VERSION ""

NS_ :

BS_:

BU_: APIM_CISM FCIMB RACM_RCIM DSP WCM DACMC HUD_ADV TRM_ITRM ACM GWM _delete APIM IPC GENERIC TSTR

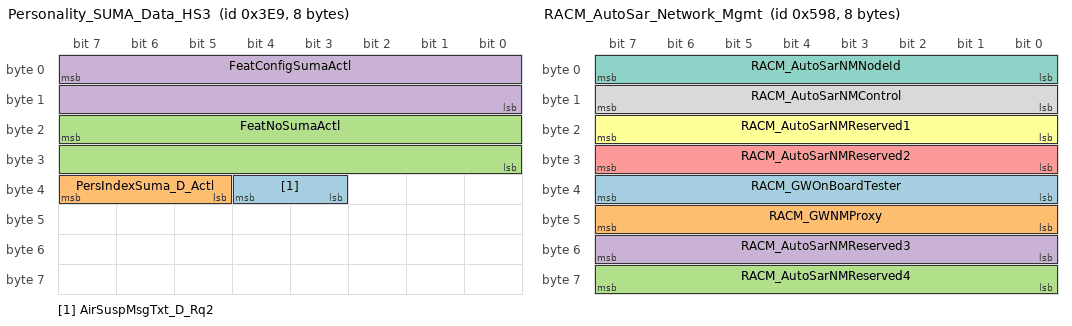
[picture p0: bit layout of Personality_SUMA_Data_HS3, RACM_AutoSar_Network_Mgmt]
BO_ 1001 Personality_SUMA_Data_HS3: 8 GWM
 SG_ AirSuspMsgTxt_D_Rq2 : 36|2@0+ (1,0) [0|3] "SED"  APIM_CISM,APIM,IPC
 SG_ PersIndexSuma_D_Actl : 39|3@0+ (1,0) [0|7] "SED"  APIM_CISM,APIM,IPC
 SG_ FeatNoSumaActl : 23|16@0+ (1,0) [0|65535] "Number"  APIM_CISM,APIM,IPC
 SG_ FeatConfigSumaActl : 7|16@0+ (1,0) [0|65535] "Undefined"  APIM_CISM,APIM,IPC

BO_ 1916 TesterPhysicalResRACM: 8 RACM_RCIM
 SG_ TesterPhysicalResRACM : 7|64@0+ (1,0) [0|1.84467E+019] "unitless"  TSTR

BO_ 1908 TesterPhysicalReqRACM: 8 TSTR
 SG_ TesterPhysicalReqRACM : 7|64@0+ (1,0) [0|1.84467E+019] "unitless"  RACM_RCIM

BO_ 1432 RACM_AutoSar_Network_Mgmt: 8 RACM_RCIM
 SG_ RACM_GWOnBoardTester : 39|8@0+ (1,0) [0|255] "unitless"  HUD_ADV,GWM
 SG_ RACM_GWNMProxy : 47|8@0+ (1,0) [0|255] "unitless"  HUD_ADV,GWM
 SG_ RACM_AutoSarNMReserved4 : 63|8@0+ (1,0) [0|255] "unitless"  HUD_ADV,GWM
 SG_ RACM_AutoSarNMReserved3 : 55|8@0+ (1,0) [0|255] "unitless"  HUD_ADV,GWM
 SG_ RACM_AutoSarNMReserved2 : 31|8@0+ (1,0) [0|255] "unitless"  HUD_ADV,GWM
 SG_ RACM_AutoSarNMReserved1 : 23|8@0+ (1,0) [0|255] "unitless"  HUD_ADV,GWM
 SG_ RACM_AutoSarNMNodeId : 7|8@0+ (1,0) [0|255] "unitless"  HUD_ADV,GWM
 SG_ RACM_AutoSarNMControl : 15|8@0+ (1,0) [0|255] "unitless"  HUD_ADV,GWM

BO_ 1923 TesterPhysicalReqDSP: 8 TSTR
 SG_ TesterPhysicalReqDSP : 7|64@0+ (1,0) [0|1.84467E+019] "unitless"  DSP

BO_ 1931 TesterPhysicalResDSP: 8 DSP
 SG_ TesterPhysicalResDSP : 7|64@0+ (1,0) [0|1.84467E+019] "unitless"  TSTR

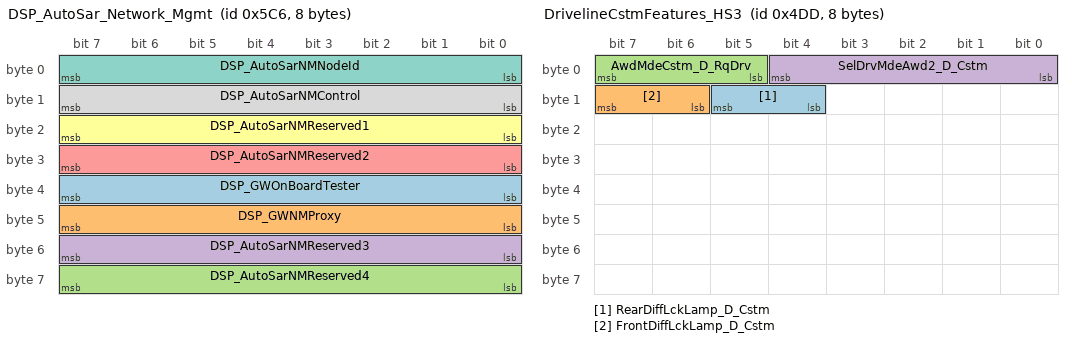
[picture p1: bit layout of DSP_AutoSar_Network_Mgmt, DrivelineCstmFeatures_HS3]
BO_ 1478 DSP_AutoSar_Network_Mgmt: 8 DSP
 SG_ DSP_GWOnBoardTester : 39|8@0+ (1,0) [0|255] "unitless"  HUD_ADV
 SG_ DSP_GWNMProxy : 47|8@0+ (1,0) [0|255] "unitless"  HUD_ADV
 SG_ DSP_AutoSarNMReserved4 : 63|8@0+ (1,0) [0|255] "unitless"  HUD_ADV
 SG_ DSP_AutoSarNMReserved3 : 55|8@0+ (1,0) [0|255] "unitless"  HUD_ADV
 SG_ DSP_AutoSarNMReserved2 : 31|8@0+ (1,0) [0|255] "unitless"  HUD_ADV
 SG_ DSP_AutoSarNMReserved1 : 23|8@0+ (1,0) [0|255] "unitless"  HUD_ADV
 SG_ DSP_AutoSarNMNodeId : 7|8@0+ (1,0) [0|255] "unitless"  HUD_ADV
 SG_ DSP_AutoSarNMControl : 15|8@0+ (1,0) [0|255] "unitless"  HUD_ADV

BO_ 1245 DrivelineCstmFeatures_HS3: 8 GWM
 SG_ RearDiffLckLamp_D_Cstm : 13|2@0+ (1,0) [0|3] "SED"  IPC
 SG_ FrontDiffLckLamp_D_Cstm : 15|2@0+ (1,0) [0|3] "SED"  IPC
 SG_ AwdMdeCstm_D_RqDrv : 7|3@0+ (1,0) [0|7] "SED"  IPC
 SG_ SelDrvMdeAwd2_D_Cstm : 4|5@0+ (1,0) [0|31] "SED"  GENERIC

BO_ 1242 PowertrainCstmData_HS3: 8 GWM
 SG_ EngExhMdeQuietCstm_D_Rq : 7|3@0+ (1,0) [0|7] "SED"  IPC
 SG_ StopStrtCstm_D_Rq : 15|2@0+ (1,0) [0|3] "SED"  IPC
 SG_ SelDrvMdeCstmPt_D_Rq : 4|5@0+ (1,0) [0|31] "SED"  GENERIC

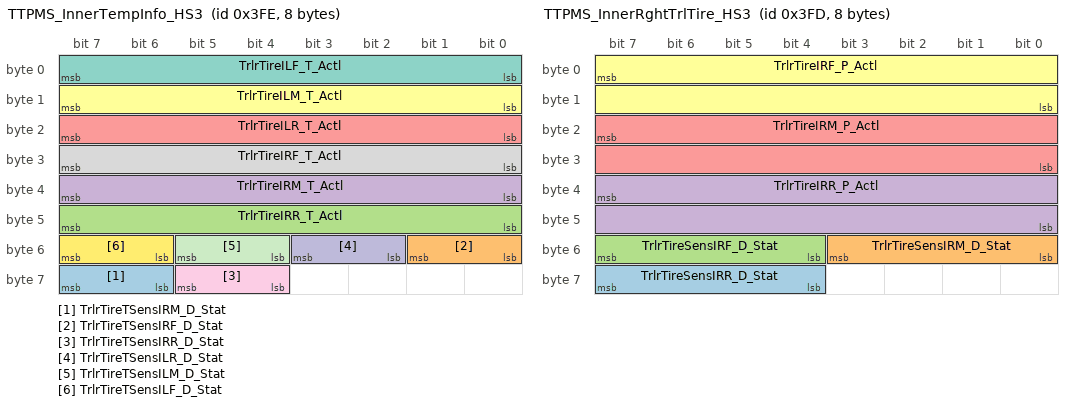
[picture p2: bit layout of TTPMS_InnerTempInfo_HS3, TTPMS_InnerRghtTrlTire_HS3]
BO_ 1022 TTPMS_InnerTempInfo_HS3: 8 GWM
 SG_ TrlrTireTSensIRM_D_Stat : 63|2@0+ (1,0) [0|3] "SED"  APIM_CISM,APIM,IPC
 SG_ TrlrTireTSensIRF_D_Stat : 49|2@0+ (1,0) [0|3] "SED"  APIM_CISM,APIM,IPC
 SG_ TrlrTireIRR_T_Actl : 47|8@0+ (1,-60) [-60|193] "degC"  APIM_CISM,APIM,IPC
 SG_ TrlrTireIRM_T_Actl : 39|8@0+ (1,-60) [-60|193] "degC"  APIM_CISM,APIM,IPC
 SG_ TrlrTireILR_T_Actl : 23|8@0+ (1,-60) [-60|193] "degC"  APIM_CISM,APIM,IPC
 SG_ TrlrTireILM_T_Actl : 15|8@0+ (1,-60) [-60|193] "degC"  APIM_CISM,APIM,IPC
 SG_ TrlrTireILF_T_Actl : 7|8@0+ (1,-60) [-60|193] "degC"  APIM_CISM,APIM,IPC
 SG_ TrlrTireIRF_T_Actl : 31|8@0+ (1,-60) [-60|193] "degC"  APIM_CISM,APIM,IPC
 SG_ TrlrTireTSensIRR_D_Stat : 61|2@0+ (1,0) [0|3] "SED"  APIM_CISM,APIM,IPC
 SG_ TrlrTireTSensILR_D_Stat : 51|2@0+ (1,0) [0|3] "SED"  APIM_CISM,APIM,IPC
 SG_ TrlrTireTSensILM_D_Stat : 53|2@0+ (1,0) [0|3] "SED"  APIM_CISM,APIM,IPC
 SG_ TrlrTireTSensILF_D_Stat : 55|2@0+ (1,0) [0|3] "SED"  APIM_CISM,APIM,IPC

BO_ 1021 TTPMS_InnerRghtTrlTire_HS3: 8 GWM
 SG_ TrlrTireSensIRR_D_Stat : 63|4@0+ (1,0) [0|15] "SED"  APIM_CISM,APIM,IPC
 SG_ TrlrTireSensIRM_D_Stat : 51|4@0+ (1,0) [0|15] "SED"  APIM_CISM,APIM,IPC
 SG_ TrlrTireSensIRF_D_Stat : 55|4@0+ (1,0) [0|15] "SED"  APIM_CISM,APIM,IPC
 SG_ TrlrTireIRR_P_Actl : 39|16@0+ (1,0) [0|65533] "kilopascal"  APIM_CISM,APIM,IPC
 SG_ TrlrTireIRM_P_Actl : 23|16@0+ (1,0) [0|65533] "kilopascal"  APIM_CISM,APIM,IPC
 SG_ TrlrTireIRF_P_Actl : 7|16@0+ (1,0) [0|65533] "kilopascal"  APIM_CISM,APIM,IPC

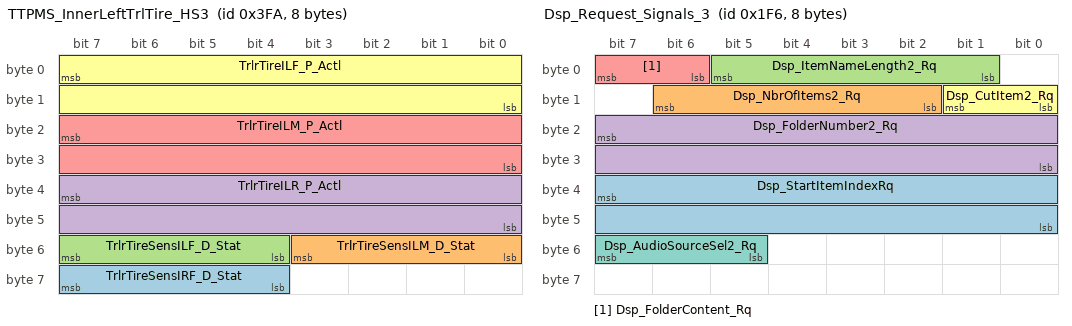
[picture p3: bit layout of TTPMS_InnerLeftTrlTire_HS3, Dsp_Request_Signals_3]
BO_ 1018 TTPMS_InnerLeftTrlTire_HS3: 8 GWM
 SG_ TrlrTireSensIRF_D_Stat : 63|4@0+ (1,0) [0|15] "SED"  APIM,IPC
 SG_ TrlrTireSensILM_D_Stat : 51|4@0+ (1,0) [0|15] "SED"  APIM_CISM,APIM,IPC
 SG_ TrlrTireSensILF_D_Stat : 55|4@0+ (1,0) [0|15] "SED"  APIM_CISM,APIM,IPC
 SG_ TrlrTireILR_P_Actl : 39|16@0+ (1,0) [0|65533] "kilopascal"  APIM_CISM,APIM,IPC
 SG_ TrlrTireILM_P_Actl : 23|16@0+ (1,0) [0|65533] "kilopascal"  APIM_CISM,APIM,IPC
 SG_ TrlrTireILF_P_Actl : 7|16@0+ (1,0) [0|65533] "kilopascal"  APIM_CISM,APIM,IPC

BO_ 502 Dsp_Request_Signals_3: 8 APIM
 SG_ Dsp_StartItemIndexRq : 39|16@0+ (1,0) [0|65535] "unitless"  APIM_CISM,ACM
 SG_ Dsp_NbrOfItems2_Rq : 14|5@0+ (1,0) [0|20] "SED"  APIM_CISM,ACM
 SG_ Dsp_ItemNameLength2_Rq : 5|5@0+ (1,0) [0|20] "SED"  APIM_CISM,ACM
 SG_ Dsp_FolderNumber2_Rq : 23|16@0+ (1,0) [0|65535] "unitless"  APIM_CISM,ACM
 SG_ Dsp_FolderContent_Rq : 7|2@0+ (1,0) [0|3] "SED"  APIM_CISM,ACM
 SG_ Dsp_CutItem2_Rq : 9|2@0+ (1,0) [0|3] "SED"  APIM_CISM,ACM
 SG_ Dsp_AudioSourceSel2_Rq : 55|3@0+ (1,0) [0|7] "SED"  APIM_CISM,ACM

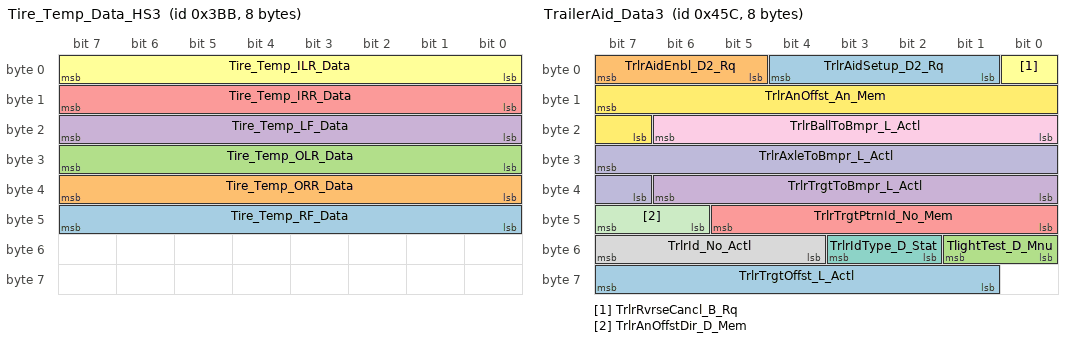
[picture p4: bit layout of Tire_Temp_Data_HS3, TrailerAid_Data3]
BO_ 955 Tire_Temp_Data_HS3: 8 GWM
 SG_ Tire_Temp_RF_Data : 47|8@0+ (1,-60) [-60|193] "degC"  IPC,APIM,APIM_CISM
 SG_ Tire_Temp_ORR_Data : 39|8@0+ (1,-60) [-60|193] "degC"  IPC,APIM,APIM_CISM
 SG_ Tire_Temp_OLR_Data : 31|8@0+ (1,-60) [-60|193] "degC"  IPC,APIM,APIM_CISM
 SG_ Tire_Temp_LF_Data : 23|8@0+ (1,-60) [-60|193] "degC"  IPC,APIM,APIM_CISM
 SG_ Tire_Temp_IRR_Data : 15|8@0+ (1,-60) [-60|193] "degC"  IPC,APIM,APIM_CISM
 SG_ Tire_Temp_ILR_Data : 7|8@0+ (1,-60) [-60|193] "degC"  IPC,APIM,APIM_CISM

BO_ 1116 TrailerAid_Data3: 8 APIM
 SG_ TrlrAidSetup_D2_Rq : 4|4@0+ (1,0) [0|15] "SED"  GWM
 SG_ TrlrAidEnbl_D2_Rq : 7|3@0+ (1,0) [0|7] "SED"  GWM
 SG_ TlightTest_D_Mnu : 49|2@0+ (1,0) [0|3] "SED"  GWM
 SG_ TrlrTrgtToBmpr_L_Actl : 38|7@0+ (0.0127,0) [0|1.6129] "meter"  GWM
 SG_ TrlrTrgtPtrnId_No_Mem : 45|6@0+ (1,0) [0|63] "unitless"  GWM
 SG_ TrlrRvrseCancl_B_Rq : 0|1@0+ (1,0) [0|1] "SED"  GWM
 SG_ TrlrIdType_D_Stat : 51|2@0+ (1,0) [0|3] "SED"  GWM
 SG_ TrlrId_No_Actl : 55|4@0+ (1,0) [0|15] "unitless"  GWM
 SG_ TrlrBallToBmpr_L_Actl : 22|7@0+ (0.0127,0) [0|1.6129] "meter"  GWM
 SG_ TrlrAxleToBmpr_L_Actl : 31|9@0+ (0.0254,0) [0|12.9794] "meter"  GWM
 SG_ TrlrAnOffstDir_D_Mem : 47|2@0+ (1,0) [0|3] "SED"  GWM
 SG_ TrlrAnOffst_An_Mem : 15|9@0+ (0.1,0) [0|51.1] "degrees"  GWM
 SG_ TrlrTrgtOffst_L_Actl : 63|7@0+ (0.0127,0) [0|1.6129] "meter"  GWM

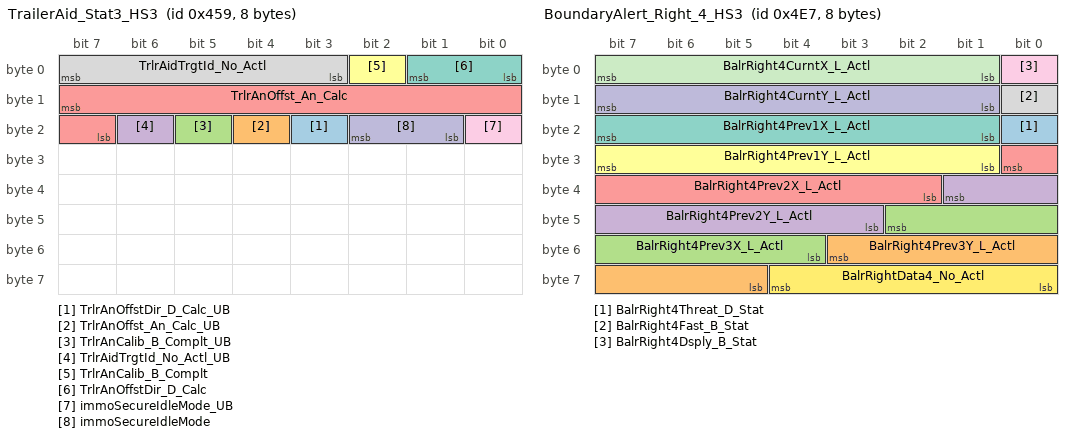
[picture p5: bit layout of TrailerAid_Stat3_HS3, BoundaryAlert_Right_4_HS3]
BO_ 1113 TrailerAid_Stat3_HS3: 8 GWM
 SG_ TrlrAnOffstDir_D_Calc_UB : 19|1@0+ (1,0) [0|1] "SED"  APIM_CISM,IPC,APIM
 SG_ TrlrAnOffst_An_Calc_UB : 20|1@0+ (1,0) [0|1] "SED"  APIM_CISM,IPC,APIM
 SG_ TrlrAnCalib_B_Complt_UB : 21|1@0+ (1,0) [0|1] "SED"  APIM_CISM,IPC,APIM
 SG_ TrlrAidTrgtId_No_Actl_UB : 22|1@0+ (1,0) [0|1] "SED"  APIM_CISM,IPC,APIM
 SG_ TrlrAnOffst_An_Calc : 15|9@0+ (0.1,0) [0|51.1] "degrees"  APIM_CISM,IPC,APIM
 SG_ TrlrAnCalib_B_Complt : 2|1@0+ (1,0) [0|1] "SED"  APIM_CISM,IPC,APIM
 SG_ TrlrAnOffstDir_D_Calc : 1|2@0+ (1,0) [0|3] "SED"  APIM_CISM,IPC,APIM
 SG_ TrlrAidTrgtId_No_Actl : 7|5@0+ (1,0) [0|31] "unitless"  APIM_CISM,IPC,APIM
 SG_ immoSecureIdleMode_UB : 16|1@0+ (1,0) [0|1] "SED"  APIM_CISM,APIM
 SG_ immoSecureIdleMode : 18|2@0+ (1,0) [0|3] "SED"  APIM_CISM,APIM

BO_ 1255 BoundaryAlert_Right_4_HS3: 8 GWM
 SG_ BalrRight4Threat_D_Stat : 16|1@0+ (1,0) [0|1] "SED"  IPC
 SG_ BalrRight4Prev3Y_L_Actl : 51|7@0+ (0.5,-32) [-32|31.5] "meter"  IPC
 SG_ BalrRight4Prev3X_L_Actl : 42|7@0+ (0.5,-32) [-32|31.5] "meter"  IPC
 SG_ BalrRight4Prev2Y_L_Actl : 33|7@0+ (0.5,-32) [-32|31.5] "meter"  IPC
 SG_ BalrRight4Prev2X_L_Actl : 24|7@0+ (0.5,-32) [-32|31.5] "meter"  IPC
 SG_ BalrRight4Prev1Y_L_Actl : 31|7@0+ (0.5,-32) [-32|31.5] "meter"  IPC
 SG_ BalrRight4Prev1X_L_Actl : 23|7@0+ (0.5,-32) [-32|31.5] "meter"  IPC
 SG_ BalrRight4Fast_B_Stat : 8|1@0+ (1,0) [0|1] "SED"  IPC
 SG_ BalrRight4Dsply_B_Stat : 0|1@0+ (1,0) [0|1] "SED"  IPC
 SG_ BalrRight4CurntY_L_Actl : 15|7@0+ (0.5,-32) [-32|31.5] "meter"  IPC
 SG_ BalrRight4CurntX_L_Actl : 7|7@0+ (0.5,-32) [-32|31.5] "meter"  IPC
 SG_ BalrRightData4_No_Actl : 60|5@0+ (1,0) [0|31] "unitless" Vector__XXX

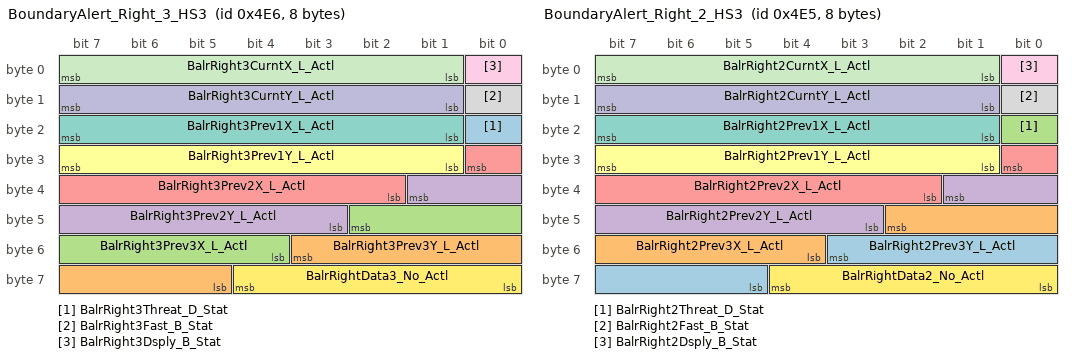
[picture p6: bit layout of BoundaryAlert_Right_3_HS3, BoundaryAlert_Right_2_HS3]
BO_ 1254 BoundaryAlert_Right_3_HS3: 8 GWM
 SG_ BalrRight3Threat_D_Stat : 16|1@0+ (1,0) [0|1] "SED"  IPC
 SG_ BalrRight3Prev3Y_L_Actl : 51|7@0+ (0.5,-32) [-32|31.5] "meter"  IPC
 SG_ BalrRight3Prev3X_L_Actl : 42|7@0+ (0.5,-32) [-32|31.5] "meter"  IPC
 SG_ BalrRight3Prev2Y_L_Actl : 33|7@0+ (0.5,-32) [-32|31.5] "meter"  IPC
 SG_ BalrRight3Prev2X_L_Actl : 24|7@0+ (0.5,-32) [-32|31.5] "meter"  IPC
 SG_ BalrRight3Prev1Y_L_Actl : 31|7@0+ (0.5,-32) [-32|31.5] "meter"  IPC
 SG_ BalrRight3Prev1X_L_Actl : 23|7@0+ (0.5,-32) [-32|31.5] "meter"  IPC
 SG_ BalrRight3Fast_B_Stat : 8|1@0+ (1,0) [0|1] "SED"  IPC
 SG_ BalrRight3Dsply_B_Stat : 0|1@0+ (1,0) [0|1] "SED"  IPC
 SG_ BalrRight3CurntY_L_Actl : 15|7@0+ (0.5,-32) [-32|31.5] "meter"  IPC
 SG_ BalrRight3CurntX_L_Actl : 7|7@0+ (0.5,-32) [-32|31.5] "meter"  IPC
 SG_ BalrRightData3_No_Actl : 60|5@0+ (1,0) [0|31] "unitless" Vector__XXX

BO_ 1253 BoundaryAlert_Right_2_HS3: 8 GWM
 SG_ BalrRight2Prev3Y_L_Actl : 51|7@0+ (0.5,-32) [-32|31.5] "meter"  IPC
 SG_ BalrRight2Prev3X_L_Actl : 42|7@0+ (0.5,-32) [-32|31.5] "meter"  IPC
 SG_ BalrRight2Threat_D_Stat : 16|1@0+ (1,0) [0|1] "SED"  IPC
 SG_ BalrRight2Prev2Y_L_Actl : 33|7@0+ (0.5,-32) [-32|31.5] "meter"  IPC
 SG_ BalrRight2Prev2X_L_Actl : 24|7@0+ (0.5,-32) [-32|31.5] "meter"  IPC
 SG_ BalrRight2Prev1Y_L_Actl : 31|7@0+ (0.5,-32) [-32|31.5] "meter"  IPC
 SG_ BalrRight2Prev1X_L_Actl : 23|7@0+ (0.5,-32) [-32|31.5] "meter"  IPC
 SG_ BalrRight2Fast_B_Stat : 8|1@0+ (1,0) [0|1] "SED"  IPC
 SG_ BalrRight2Dsply_B_Stat : 0|1@0+ (1,0) [0|1] "SED"  IPC
 SG_ BalrRight2CurntY_L_Actl : 15|7@0+ (0.5,-32) [-32|31.5] "meter"  IPC
 SG_ BalrRight2CurntX_L_Actl : 7|7@0+ (0.5,-32) [-32|31.5] "meter"  IPC
 SG_ BalrRightData2_No_Actl : 60|5@0+ (1,0) [0|31] "unitless" Vector__XXX

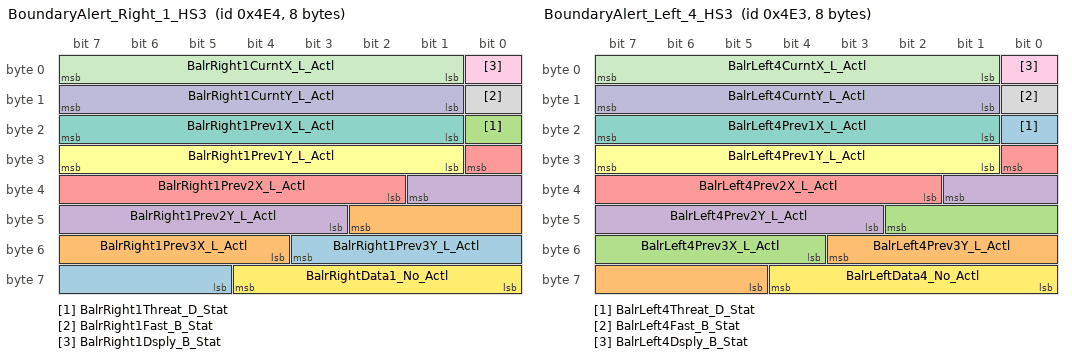
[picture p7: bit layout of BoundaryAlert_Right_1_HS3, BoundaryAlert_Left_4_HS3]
BO_ 1252 BoundaryAlert_Right_1_HS3: 8 GWM
 SG_ BalrRight1Prev3Y_L_Actl : 51|7@0+ (0.5,-32) [-32|31.5] "meter"  IPC
 SG_ BalrRight1Prev3X_L_Actl : 42|7@0+ (0.5,-32) [-32|31.5] "meter"  IPC
 SG_ BalrRight1Threat_D_Stat : 16|1@0+ (1,0) [0|1] "SED"  IPC
 SG_ BalrRight1Prev2Y_L_Actl : 33|7@0+ (0.5,-32) [-32|31.5] "meter"  IPC
 SG_ BalrRight1Prev2X_L_Actl : 24|7@0+ (0.5,-32) [-32|31.5] "meter"  IPC
 SG_ BalrRight1Prev1Y_L_Actl : 31|7@0+ (0.5,-32) [-32|31.5] "meter"  IPC
 SG_ BalrRight1Prev1X_L_Actl : 23|7@0+ (0.5,-32) [-32|31.5] "meter"  IPC
 SG_ BalrRight1Fast_B_Stat : 8|1@0+ (1,0) [0|1] "SED"  IPC
 SG_ BalrRight1Dsply_B_Stat : 0|1@0+ (1,0) [0|1] "SED"  IPC
 SG_ BalrRight1CurntY_L_Actl : 15|7@0+ (0.5,-32) [-32|31.5] "meter"  IPC
 SG_ BalrRight1CurntX_L_Actl : 7|7@0+ (0.5,-32) [-32|31.5] "meter"  IPC
 SG_ BalrRightData1_No_Actl : 60|5@0+ (1,0) [0|31] "unitless" Vector__XXX

BO_ 1251 BoundaryAlert_Left_4_HS3: 8 GWM
 SG_ BalrLeft4Threat_D_Stat : 16|1@0+ (1,0) [0|1] "SED"  IPC
 SG_ BalrLeft4Prev3Y_L_Actl : 51|7@0+ (0.5,-32) [-32|31.5] "meter"  IPC
 SG_ BalrLeft4Prev3X_L_Actl : 42|7@0+ (0.5,-32) [-32|31.5] "meter"  IPC
 SG_ BalrLeft4Prev2Y_L_Actl : 33|7@0+ (0.5,-32) [-32|31.5] "meter"  IPC
 SG_ BalrLeft4Prev2X_L_Actl : 24|7@0+ (0.5,-32) [-32|31.5] "meter"  IPC
 SG_ BalrLeft4Prev1Y_L_Actl : 31|7@0+ (0.5,-32) [-32|31.5] "meter"  IPC
 SG_ BalrLeft4Prev1X_L_Actl : 23|7@0+ (0.5,-32) [-32|31.5] "meter"  IPC
 SG_ BalrLeft4Fast_B_Stat : 8|1@0+ (1,0) [0|1] "SED"  IPC
 SG_ BalrLeft4Dsply_B_Stat : 0|1@0+ (1,0) [0|1] "SED"  IPC
 SG_ BalrLeft4CurntY_L_Actl : 15|7@0+ (0.5,-32) [-32|31.5] "meter"  IPC
 SG_ BalrLeft4CurntX_L_Actl : 7|7@0+ (0.5,-32) [-32|31.5] "meter"  IPC
 SG_ BalrLeftData4_No_Actl : 60|5@0+ (1,0) [0|31] "unitless" Vector__XXX

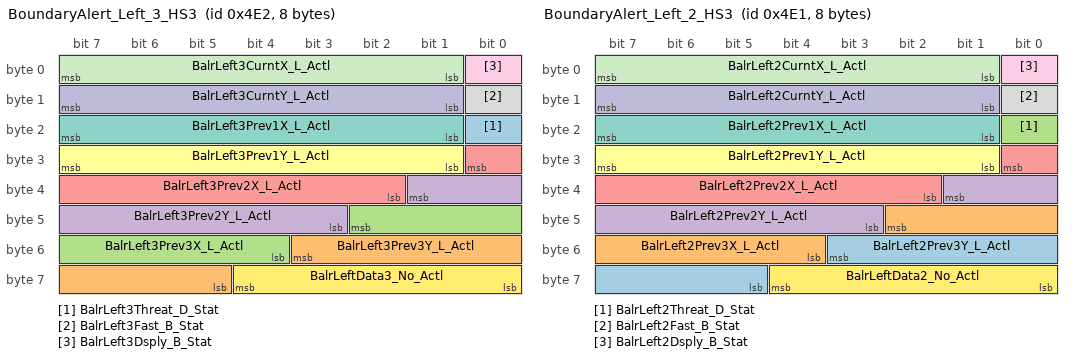
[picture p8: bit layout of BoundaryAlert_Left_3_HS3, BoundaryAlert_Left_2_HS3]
BO_ 1250 BoundaryAlert_Left_3_HS3: 8 GWM
 SG_ BalrLeft3Threat_D_Stat : 16|1@0+ (1,0) [0|1] "SED"  IPC
 SG_ BalrLeft3Prev3Y_L_Actl : 51|7@0+ (0.5,-32) [-32|31.5] "meter"  IPC
 SG_ BalrLeft3Prev3X_L_Actl : 42|7@0+ (0.5,-32) [-32|31.5] "meter"  IPC
 SG_ BalrLeft3Prev2Y_L_Actl : 33|7@0+ (0.5,-32) [-32|31.5] "meter"  IPC
 SG_ BalrLeft3Prev2X_L_Actl : 24|7@0+ (0.5,-32) [-32|31.5] "meter"  IPC
 SG_ BalrLeft3Prev1Y_L_Actl : 31|7@0+ (0.5,-32) [-32|31.5] "meter"  IPC
 SG_ BalrLeft3Prev1X_L_Actl : 23|7@0+ (0.5,-32) [-32|31.5] "meter"  IPC
 SG_ BalrLeft3Fast_B_Stat : 8|1@0+ (1,0) [0|1] "SED"  IPC
 SG_ BalrLeft3Dsply_B_Stat : 0|1@0+ (1,0) [0|1] "SED"  IPC
 SG_ BalrLeft3CurntY_L_Actl : 15|7@0+ (0.5,-32) [-32|31.5] "meter"  IPC
 SG_ BalrLeft3CurntX_L_Actl : 7|7@0+ (0.5,-32) [-32|31.5] "meter"  IPC
 SG_ BalrLeftData3_No_Actl : 60|5@0+ (1,0) [0|31] "unitless" Vector__XXX

BO_ 1249 BoundaryAlert_Left_2_HS3: 8 GWM
 SG_ BalrLeft2Prev3Y_L_Actl : 51|7@0+ (0.5,-32) [-32|31.5] "meter"  IPC
 SG_ BalrLeft2Prev3X_L_Actl : 42|7@0+ (0.5,-32) [-32|31.5] "meter"  IPC
 SG_ BalrLeft2Threat_D_Stat : 16|1@0+ (1,0) [0|1] "SED"  IPC
 SG_ BalrLeft2Prev2Y_L_Actl : 33|7@0+ (0.5,-32) [-32|31.5] "meter"  IPC
 SG_ BalrLeft2Prev2X_L_Actl : 24|7@0+ (0.5,-32) [-32|31.5] "meter"  IPC
 SG_ BalrLeft2Prev1Y_L_Actl : 31|7@0+ (0.5,-32) [-32|31.5] "meter"  IPC
 SG_ BalrLeft2Prev1X_L_Actl : 23|7@0+ (0.5,-32) [-32|31.5] "meter"  IPC
 SG_ BalrLeft2Fast_B_Stat : 8|1@0+ (1,0) [0|1] "SED"  IPC
 SG_ BalrLeft2Dsply_B_Stat : 0|1@0+ (1,0) [0|1] "SED"  IPC
 SG_ BalrLeft2CurntY_L_Actl : 15|7@0+ (0.5,-32) [-32|31.5] "meter"  IPC
 SG_ BalrLeft2CurntX_L_Actl : 7|7@0+ (0.5,-32) [-32|31.5] "meter"  IPC
 SG_ BalrLeftData2_No_Actl : 60|5@0+ (1,0) [0|31] "unitless" Vector__XXX

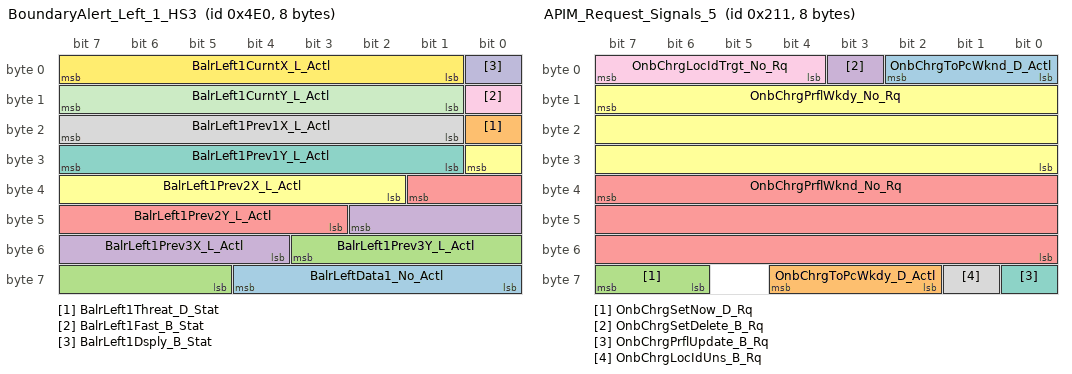
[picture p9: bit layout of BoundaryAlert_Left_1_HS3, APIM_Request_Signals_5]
BO_ 1248 BoundaryAlert_Left_1_HS3: 8 GWM
 SG_ BalrLeftData1_No_Actl : 60|5@0+ (1,0) [0|31] "unitless" Vector__XXX
 SG_ BalrLeft1Threat_D_Stat : 16|1@0+ (1,0) [0|1] "SED"  IPC
 SG_ BalrLeft1Prev3Y_L_Actl : 51|7@0+ (0.5,-32) [-32|31.5] "meter"  IPC
 SG_ BalrLeft1Prev3X_L_Actl : 42|7@0+ (0.5,-32) [-32|31.5] "meter"  IPC
 SG_ BalrLeft1Prev2Y_L_Actl : 33|7@0+ (0.5,-32) [-32|31.5] "meter"  IPC
 SG_ BalrLeft1Prev2X_L_Actl : 24|7@0+ (0.5,-32) [-32|31.5] "meter"  IPC
 SG_ BalrLeft1Prev1Y_L_Actl : 31|7@0+ (0.5,-32) [-32|31.5] "meter"  IPC
 SG_ BalrLeft1Prev1X_L_Actl : 23|7@0+ (0.5,-32) [-32|31.5] "meter"  IPC
 SG_ BalrLeft1Fast_B_Stat : 8|1@0+ (1,0) [0|1] "SED"  IPC
 SG_ BalrLeft1Dsply_B_Stat : 0|1@0+ (1,0) [0|1] "SED"  IPC
 SG_ BalrLeft1CurntY_L_Actl : 15|7@0+ (0.5,-32) [-32|31.5] "meter"  IPC
 SG_ BalrLeft1CurntX_L_Actl : 7|7@0+ (0.5,-32) [-32|31.5] "meter"  IPC

BO_ 1256 GWM_Send_Signals_15_HS3: 8 GWM
 SG_ StopLamp_B_RqTrlrAft_UB : 47|1@0+ (1,0) [0|1] "SED"  TRM_ITRM
 SG_ StopLamp_B_RqTrlrAft : 32|1@0+ (1,0) [0|1] "SED"  TRM_ITRM
 SG_ BalrMdeRight_D_Stat_UB : 21|1@0+ (1,0) [0|1] "SED"  IPC
 SG_ BalrMdeSelRight_B_Stat_UB : 17|1@0+ (1,0) [0|1] "SED"  IPC
 SG_ BalrRight_D_Stat_UB : 16|1@0+ (1,0) [0|1] "SED"  IPC
 SG_ BalrLckRight_B_Stat_UB : 14|1@0+ (1,0) [0|1] "SED"  IPC
 SG_ BalrChimeRight_D_Rq_UB : 2|1@0+ (1,0) [0|1] "SED"  IPC
 SG_ BalrSnsRight_D_Falt_UB : 24|1@0+ (1,0) [0|1] "SED"  IPC
 SG_ BalrWndwRight_B_Stat_UB : 36|1@0+ (1,0) [0|1] "SED"  IPC
 SG_ BalrLckRight_B_Stat : 15|1@0+ (1,0) [0|1] "SED"  IPC
 SG_ BalrWndwRight_B_Stat : 37|1@0+ (1,0) [0|1] "SED"  IPC
 SG_ BalrMdeSelRight_B_Stat : 18|1@0+ (1,0) [0|1] "SED"  IPC
 SG_ BalrSnsRight_D_Falt : 26|2@0+ (1,0) [0|3] "SED"  IPC
 SG_ BalrChimeRight_D_Rq : 4|2@0+ (1,0) [0|3] "SED"  IPC
 SG_ BalrMdeRight_D_Stat : 23|2@0+ (1,0) [0|3] "SED"  IPC
 SG_ BalrRight_D_Stat : 31|2@0+ (1,0) [0|3] "SED"  IPC
 SG_ BalrWndwLeft_B_Stat_UB : 38|1@0+ (1,0) [0|1] "SED"  IPC
 SG_ BalrSnsLeft_D_Falt_UB : 27|1@0+ (1,0) [0|1] "SED"  IPC
 SG_ BalrMdeSelLeft_B_Stat_UB : 19|1@0+ (1,0) [0|1] "SED"  IPC
 SG_ BalrMdeLeft_D_Stat_UB : 8|1@0+ (1,0) [0|1] "SED"  IPC
 SG_ BalrLeft_D_Stat_UB : 11|1@0+ (1,0) [0|1] "SED"  IPC
 SG_ BalrLckLeft_B_Stat_UB : 0|1@0+ (1,0) [0|1] "SED"  IPC
 SG_ BalrChimeLeft_D_Rq_UB : 5|1@0+ (1,0) [0|1] "SED"  IPC
 SG_ BalrLeft_D_Stat : 13|2@0+ (1,0) [0|3] "SED"  IPC
 SG_ BalrMdeSelLeft_B_Stat : 20|1@0+ (1,0) [0|1] "SED"  IPC
 SG_ BalrLckLeft_B_Stat : 1|1@0+ (1,0) [0|1] "SED"  IPC
 SG_ BalrWndwLeft_B_Stat : 39|1@0+ (1,0) [0|1] "SED"  IPC
 SG_ BalrMdeLeft_D_Stat : 10|2@0+ (1,0) [0|3] "SED"  IPC
 SG_ BalrSnsLeft_D_Falt : 29|2@0+ (1,0) [0|3] "SED"  IPC
 SG_ BalrChimeLeft_D_Rq : 7|2@0+ (1,0) [0|3] "SED"  IPC
 SG_ WakeAlarm2_D_Stat_UB : 33|1@0+ (1,0) [0|1] "SED"  TRM_ITRM
 SG_ WakeAlarm2_D_Stat : 35|2@0+ (1,0) [0|3] "SED"  TRM_ITRM

BO_ 529 APIM_Request_Signals_5: 8 APIM
 SG_ OnbChrgToPcWknd_D_Actl : 2|3@0+ (1,0) [0|7] "percent"  GWM
 SG_ OnbChrgToPcWkdy_D_Actl : 60|3@0+ (1,0) [0|7] "percent"  GWM
 SG_ OnbChrgSetNow_D_Rq : 63|2@0+ (1,0) [0|3] "SED"  GWM
 SG_ OnbChrgSetDelete_B_Rq : 3|1@0+ (1,0) [0|1] "SED"  GWM
 SG_ OnbChrgPrflWknd_No_Rq : 39|24@0+ (1,0) [0|16777215] "unitless"  GWM
 SG_ OnbChrgPrflWkdy_No_Rq : 15|24@0+ (1,0) [0|16777215] "unitless"  GWM
 SG_ OnbChrgPrflUpdate_B_Rq : 56|1@0+ (1,0) [0|1] "SED"  GWM
 SG_ OnbChrgLocIdUns_B_Rq : 57|1@0+ (1,0) [0|1] "SED"  GWM
 SG_ OnbChrgLocIdTrgt_No_Rq : 7|4@0+ (1,0) [0|15] "Unitless"  GWM

BO_ 642 GWM_Send_Signals_14_HS3: 8 GWM
 SG_ SldrrMsgTxt_D2_Rq_UB : 8|1@0+ (1,0) [0|1] "SED"  IPC
 SG_ SldrrMsgTxt_D2_Rq : 11|3@0+ (1,0) [0|7] "SED"  IPC
 SG_ SldrrChime_D_Rq_UB : 12|1@0+ (1,0) [0|1] "SED"  IPC
 SG_ SldrrChime_D_Rq : 15|3@0+ (1,0) [0|7] "SED"  IPC
 SG_ SldrlMsgTxt_D2_Rq_UB : 0|1@0+ (1,0) [0|1] "SED"  IPC
 SG_ SldrlMsgTxt_D2_Rq : 3|3@0+ (1,0) [0|7] "SED"  IPC
 SG_ SldrlChime_D_Rq_UB : 4|1@0+ (1,0) [0|1] "SED"  IPC
 SG_ SldrlChime_D_Rq : 7|3@0+ (1,0) [0|7] "SED"  IPC
 SG_ PaakMyKeySearch_D_Stat_UB : 27|1@0+ (1,0) [0|1] "SED"  APIM_CISM,APIM
 SG_ UreaLvlQlty_D_RqDsply_UB : 48|1@0+ (1,0) [0|1] "SED"  IPC
 SG_ DieslPrtcWarn_D_Rq_UB : 24|1@0+ (1,0) [0|1] "SED"  IPC
 SG_ UreaQltySysWarn_D_Rq_UB : 25|1@0+ (1,0) [0|1] "SED"  IPC
 SG_ UreaLvlTxtWarn_D_Rq_UB : 26|1@0+ (1,0) [0|1] "SED"  IPC
 SG_ UreaLvlQlty_D_RqDsply : 59|3@0+ (1,0) [0|7] "SED"  IPC
 SG_ UreaLvlTxtWarn_D_Rq : 63|4@0+ (1,0) [0|15] "SED"  IPC
 SG_ UreaQltySysWarn_D_Rq : 51|3@0+ (1,0) [0|7] "SED"  IPC
 SG_ DieslPrtcWarn_D_Rq : 55|4@0+ (1,0) [0|15] "SED"  IPC
 SG_ KeyMyKeyTot_No2_Cnt_UB : 40|1@0+ (1,0) [0|1] "SED"  APIM_CISM,APIM
 SG_ KeyAdmnTot_No2_Cnt_UB : 32|1@0+ (1,0) [0|1] "SED"  APIM_CISM,APIM
 SG_ KeyMyKeyTot_No2_Cnt : 47|7@0+ (1,0) [0|127] "unitless"  APIM_CISM,APIM
 SG_ KeyAdmnTot_No2_Cnt : 39|7@0+ (1,0) [0|127] "unitless"  APIM_CISM,APIM
 SG_ DcChrgSrvcRqd_B_Rq_UB : 31|1@0+ (1,0) [0|1] "SED"  IPC
 SG_ DcChrgSrvcRqd_B_Rq : 16|1@0+ (1,0) [0|1] "SED"  IPC
 SG_ PaakMyKeySearch_D_Stat : 30|3@0+ (1,0) [0|7] "SED"  APIM_CISM,APIM
 SG_ GrdAsstActv_B_Stat_UB : 17|1@0+ (1,0) [0|1] "SED"  IPC
 SG_ GrdAsstActv_B_Stat : 18|1@0+ (1,0) [0|1] "SED"  IPC
 SG_ TrlrAidTrlrId_No_Rq_UB : 19|1@0+ (1,0) [0|1] "SED"  APIM_CISM,IPC,APIM
 SG_ TrlrAidTrlrId_No_Rq : 23|4@0+ (1,0) [0|15] "unitless"  APIM_CISM,IPC,APIM

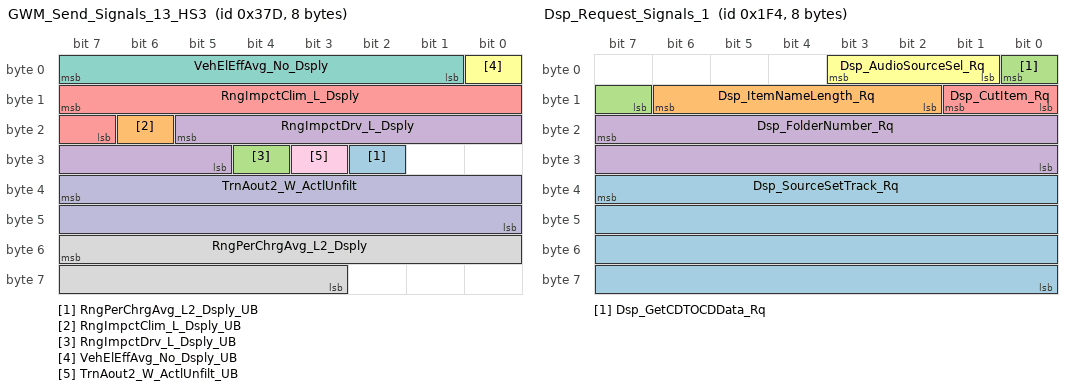
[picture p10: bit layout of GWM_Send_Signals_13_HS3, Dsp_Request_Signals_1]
BO_ 893 GWM_Send_Signals_13_HS3: 8 GWM
 SG_ RngPerChrgAvg_L2_Dsply_UB : 26|1@0+ (1,0) [0|1] "SED"  APIM,APIM_CISM,IPC
 SG_ RngImpctClim_L_Dsply_UB : 22|1@0+ (1,0) [0|1] "SED"  IPC
 SG_ RngImpctDrv_L_Dsply_UB : 28|1@0+ (1,0) [0|1] "SED"  IPC
 SG_ RngImpctDrv_L_Dsply : 21|9@0+ (1,-255) [-255|256] "km"  IPC
 SG_ RngImpctClim_L_Dsply : 15|9@0+ (1,-255) [-255|256] "km"  IPC
 SG_ VehElEffAvg_No_Dsply_UB : 0|1@0+ (1,0) [0|1] "SED"  APIM_CISM,IPC,APIM
 SG_ VehElEffAvg_No_Dsply : 7|7@0+ (10,-100) [-100|1150] "wattHr/km"  APIM_CISM,IPC,APIM
 SG_ RngPerChrgAvg_L2_Dsply : 55|13@0+ (0.1,0) [0|818.9] "km"  APIM,APIM_CISM,IPC
 SG_ TrnAout2_W_ActlUnfilt_UB : 27|1@0+ (1,0) [0|1] "SED"  APIM_CISM,ACM
 SG_ TrnAout2_W_ActlUnfilt : 39|16@0+ (0.1,-3276.5) [-3276.5|3276.8] "rad/s"  APIM_CISM,ACM

BO_ 500 Dsp_Request_Signals_1: 8 APIM
 SG_ Dsp_SourceSetTrack_Rq : 39|32@0+ (1,0) [0|4294967295] "unitless"  APIM_CISM,ACM
 SG_ Dsp_ItemNameLength_Rq : 14|5@0+ (1,0) [0|20] "SED"  APIM_CISM,ACM
 SG_ Dsp_GetCDTOCDData_Rq : 0|2@0+ (1,0) [0|3] "SED"  APIM_CISM,ACM
 SG_ Dsp_FolderNumber_Rq : 23|16@0+ (1,0) [0|65535] "unitless"  APIM_CISM,ACM
 SG_ Dsp_CutItem_Rq : 9|2@0+ (1,0) [0|3] "SED"  APIM_CISM,ACM
 SG_ Dsp_AudioSourceSel_Rq : 3|3@0+ (1,0) [0|7] "SED"  APIM_CISM,ACM

BO_ 503 Dsp_Request_Signals_4: 8 APIM
 SG_ Dsp_PlayFrstTrInFldr_Rq : 39|16@0+ (1,0) [0|65535] "unitless"  APIM_CISM,ACM
 SG_ Dsp_ItemIndex_Rq : 23|16@0+ (1,0) [0|65535] "unitless"  APIM_CISM,ACM
 SG_ Dsp_FolderNumber3_Rq : 7|16@0+ (1,0) [0|65535] "unitless"  APIM_CISM,ACM
 SG_ Dsp_AudioSourceSel3_Rq : 55|3@0+ (1,0) [0|7] "SED"  APIM_CISM,ACM

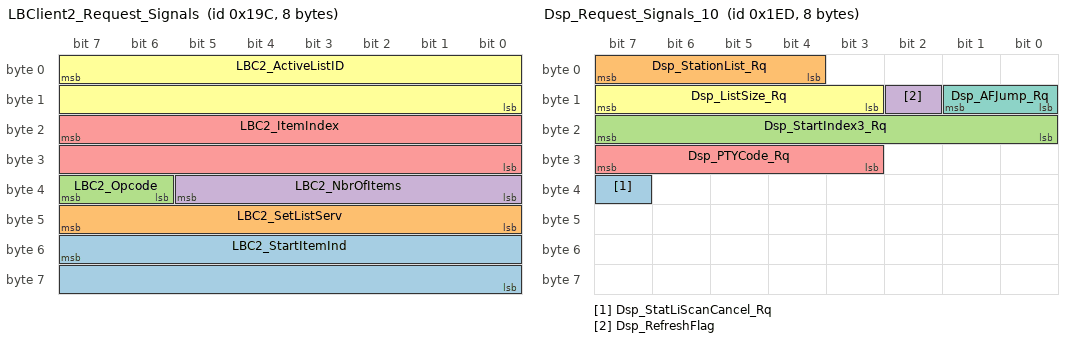
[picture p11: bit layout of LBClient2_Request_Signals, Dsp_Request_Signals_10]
BO_ 412 LBClient2_Request_Signals: 8 APIM
 SG_ LBC2_StartItemInd : 55|16@0+ (1,0) [0|65535] "unitless"  APIM_CISM,ACM
 SG_ LBC2_SetListServ : 47|8@0+ (1,0) [0|255] "unitless"  APIM_CISM,ACM
 SG_ LBC2_Opcode : 39|2@0+ (1,0) [0|3] "SED"  APIM_CISM,ACM
 SG_ LBC2_NbrOfItems : 37|6@0+ (1,0) [0|63] "unitless"  APIM_CISM,ACM
 SG_ LBC2_ItemIndex : 23|16@0+ (1,0) [0|65535] "unitless"  APIM_CISM,ACM
 SG_ LBC2_ActiveListID : 7|16@0+ (1,0) [0|65535] "unitless"  APIM_CISM,ACM

BO_ 493 Dsp_Request_Signals_10: 8 APIM
 SG_ Dsp_StatLiScanCancel_Rq : 39|1@0+ (1,0) [0|1] "SED"  APIM_CISM,ACM
 SG_ Dsp_StationList_Rq : 7|4@0+ (1,0) [0|15] "SED"  APIM_CISM,ACM
 SG_ Dsp_StartIndex3_Rq : 23|8@0+ (1,0) [0|255] "unitless"  APIM_CISM,ACM
 SG_ Dsp_RefreshFlag : 10|1@0+ (1,0) [0|1] "SED"  APIM_CISM,ACM
 SG_ Dsp_PTYCode_Rq : 31|5@0+ (1,0) [0|31] "SED"  APIM_CISM,ACM
 SG_ Dsp_ListSize_Rq : 15|5@0+ (1,0) [0|31] "SED"  APIM_CISM,ACM
 SG_ Dsp_AFJump_Rq : 9|2@0+ (1,0) [0|3] "SED"  APIM_CISM,ACM

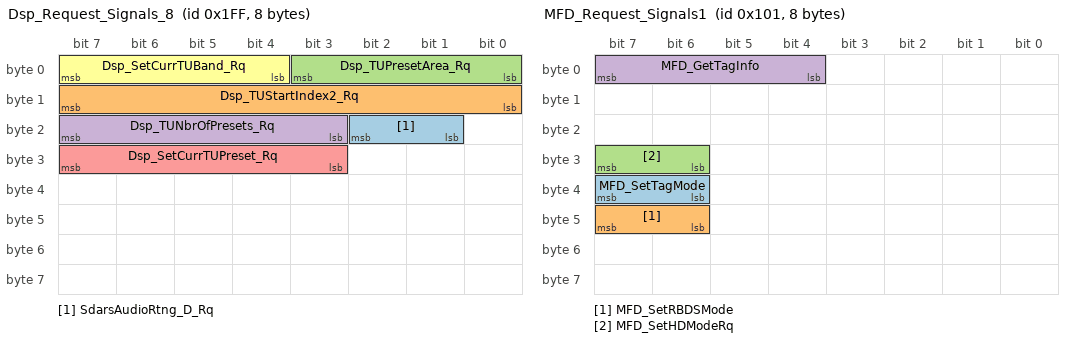
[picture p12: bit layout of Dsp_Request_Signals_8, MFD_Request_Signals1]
BO_ 511 Dsp_Request_Signals_8: 8 APIM
 SG_ SdarsAudioRtng_D_Rq : 18|2@0+ (1,0) [0|3] "SED"  APIM_CISM,ACM
 SG_ Dsp_TUStartIndex2_Rq : 15|8@0+ (1,0) [0|255] "unitless"  APIM_CISM,ACM
 SG_ Dsp_TUPresetArea_Rq : 3|4@0+ (1,0) [0|15] "SED"  APIM_CISM,ACM
 SG_ Dsp_TUNbrOfPresets_Rq : 23|5@0+ (1,0) [0|30] "SED"  APIM_CISM,ACM
 SG_ Dsp_SetCurrTUPreset_Rq : 31|5@0+ (1,0) [0|31] "SED"  APIM_CISM,ACM
 SG_ Dsp_SetCurrTUBand_Rq : 7|4@0+ (1,0) [0|15] "SED"  APIM_CISM,ACM

BO_ 257 MFD_Request_Signals1: 8 APIM
 SG_ MFD_SetTagMode : 39|2@0+ (1,0) [0|3] "SED"  APIM_CISM,ACM
 SG_ MFD_SetRBDSMode : 47|2@0+ (1,0) [0|3] "SED"  APIM_CISM,ACM
 SG_ MFD_SetHDModeRq : 31|2@0+ (1,0) [0|3] "SED"  APIM_CISM,ACM
 SG_ MFD_GetTagInfo : 7|4@0+ (1,0) [0|15] "day"  APIM_CISM,ACM

BO_ 713 SDARS_RDISP_WORD_Rx: 8 APIM
 SG_ SDARS_RDISP_WORD_Rx : 7|64@0+ (1,0) [0|1.84467440737096E+019] "unitless"  APIM_CISM,ACM

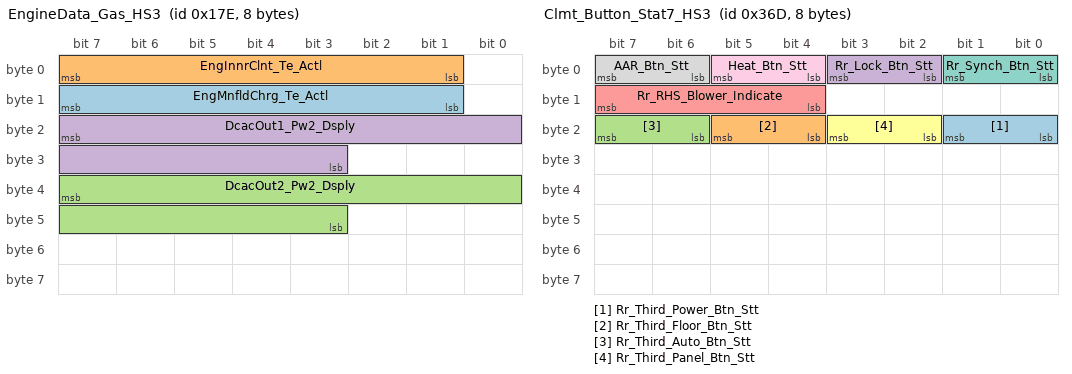
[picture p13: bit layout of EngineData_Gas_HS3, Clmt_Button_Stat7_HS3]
BO_ 382 EngineData_Gas_HS3: 8 GWM
 SG_ EngMnfldChrg_Te_Actl : 15|7@0+ (1,-20) [-20|105] "degC"  IPC
 SG_ EngInnrClnt_Te_Actl : 7|7@0+ (1,50) [50|175] "degC"  IPC
 SG_ DcacOut2_Pw2_Dsply : 39|13@0+ (1,0) [0|8189] "watts"  APIM_CISM,APIM
 SG_ DcacOut1_Pw2_Dsply : 23|13@0+ (1,0) [0|8189] "watts"  APIM_CISM,APIM

BO_ 877 Clmt_Button_Stat7_HS3: 8 GWM
 SG_ Rr_Third_Power_Btn_Stt : 17|2@0+ (1,0) [0|3] "SED"  APIM_CISM,APIM,RACM_RCIM
 SG_ Rr_Third_Floor_Btn_Stt : 21|2@0+ (1,0) [0|3] "SED"  APIM_CISM,APIM,RACM_RCIM
 SG_ Rr_Third_Auto_Btn_Stt : 23|2@0+ (1,0) [0|3] "SED"  APIM_CISM,APIM,RACM_RCIM
 SG_ Rr_Lock_Btn_Stt : 3|2@0+ (1,0) [0|3] "SED"  APIM_CISM,RACM_RCIM,APIM
 SG_ Rr_RHS_Blower_Indicate : 15|4@0+ (1,0) [0|15] "SED"  APIM_CISM,RACM_RCIM,APIM
 SG_ Rr_Third_Panel_Btn_Stt : 19|2@0+ (1,0) [0|3] "SED"  APIM_CISM,APIM,RACM_RCIM
 SG_ Rr_Synch_Btn_Stt : 1|2@0+ (1,0) [0|3] "SED"  RACM_RCIM,APIM_CISM,APIM
 SG_ AAR_Btn_Stt : 7|2@0+ (1,0) [0|3] "SED"  RACM_RCIM,APIM_CISM,FCIMB,APIM
 SG_ Heat_Btn_Stt : 5|2@0+ (1,0) [0|3] "SED"  RACM_RCIM,APIM_CISM,FCIMB,APIM

BO_ 592 RFA_BLEM_APIM_Tx_HS3: 8 GWM
 SG_ RFA_BLEM_APIM_Tx : 7|64@0+ (1,0) [0|1.84467440737096E+019] "unitless"  APIM_CISM,APIM

BO_ 600 APIM_RFA_BLEM_Tx: 8 APIM
 SG_ APIM_RFA_BLEM_Tx : 7|64@0+ (1,0) [0|1.84467440737096E+019] "unitless"  GWM

BO_ 708 TMCSrvr_TMCClnt_WORD_Tx: 8 ACM
 SG_ TMCSrvr_TMCClnt_WORD_Tx : 7|64@0+ (1,0) [0|1.84467440737096E+019] "unitless"  APIM_CISM,APIM

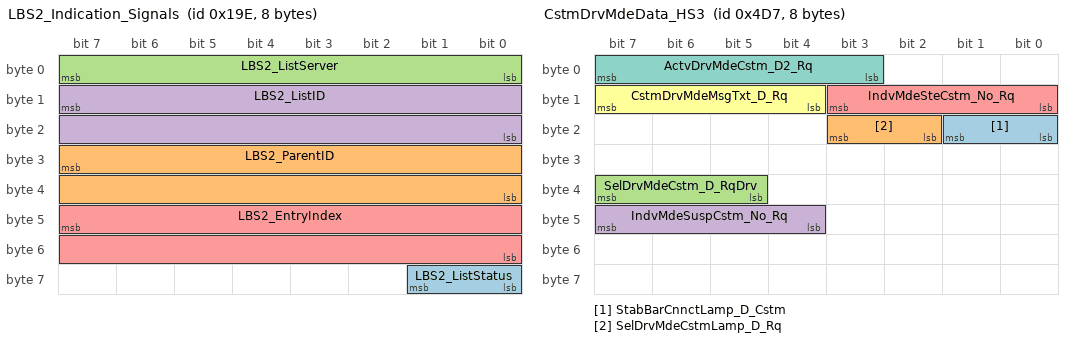
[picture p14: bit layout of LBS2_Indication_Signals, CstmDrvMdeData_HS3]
BO_ 414 LBS2_Indication_Signals: 8 ACM
 SG_ LBS2_ListStatus : 57|2@0+ (1,0) [0|3] "SED"  RACM_RCIM,APIM,IPC
 SG_ LBS2_ParentID : 31|16@0+ (1,0) [0|65535] "unitless"  RACM_RCIM,APIM,IPC
 SG_ LBS2_ListServer : 7|8@0+ (1,0) [0|255] "unitless"  RACM_RCIM,APIM,IPC
 SG_ LBS2_ListID : 15|16@0+ (1,0) [0|65535] "unitless"  RACM_RCIM,APIM,IPC
 SG_ LBS2_EntryIndex : 47|16@0+ (1,0) [0|65535] "unitless"  APIM,IPC,RACM_RCIM

BO_ 1239 CstmDrvMdeData_HS3: 8 GWM
 SG_ StabBarCnnctLamp_D_Cstm : 17|2@0+ (1,0) [0|3] "SED"  IPC
 SG_ SelDrvMdeCstmLamp_D_Rq : 19|2@0+ (1,0) [0|3] "SED"  IPC
 SG_ SelDrvMdeCstm_D_RqDrv : 39|3@0+ (1,0) [0|7] "SED"  IPC
 SG_ IndvMdeSuspCstm_No_Rq : 47|4@0+ (1,0) [0|15] "unitless"  IPC
 SG_ IndvMdeSteCstm_No_Rq : 11|4@0+ (1,0) [0|15] "unitless"  IPC
 SG_ CstmDrvMdeMsgTxt_D_Rq : 15|4@0+ (1,0) [0|15] "SED"  IPC
 SG_ ActvDrvMdeCstm_D2_Rq : 7|5@0+ (1,0) [0|31] "SED"  IPC

BO_ 716 TMCSrvr_TMCClient_WORD_Rx: 8 APIM
 SG_ TMCSrvr_TMCClnt_WORD_Rx : 7|64@0+ (1,0) [0|1.84467440737096E+019] "unitless"  APIM_CISM,ACM

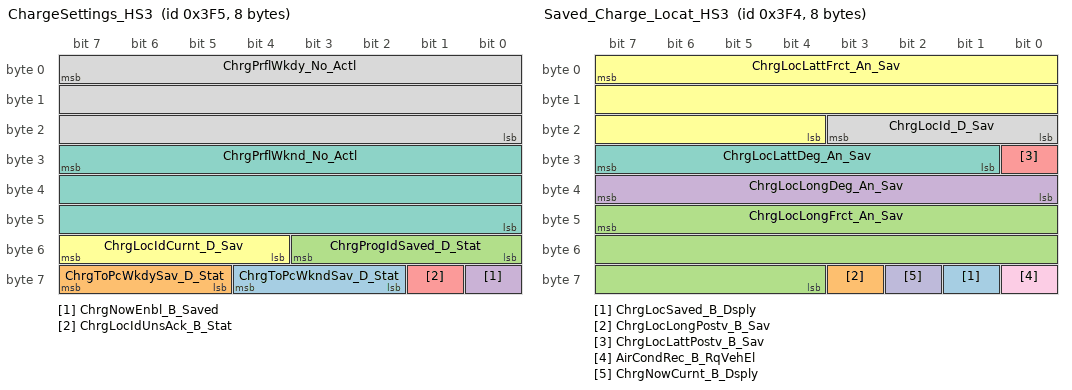
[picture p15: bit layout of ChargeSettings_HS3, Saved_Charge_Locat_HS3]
BO_ 1013 ChargeSettings_HS3: 8 GWM
 SG_ ChrgToPcWkndSav_D_Stat : 60|3@0+ (1,0) [0|7] "SED"  APIM_CISM,APIM
 SG_ ChrgToPcWkdySav_D_Stat : 63|3@0+ (1,0) [0|7] "SED"  APIM_CISM,APIM
 SG_ ChrgProgIdSaved_D_Stat : 51|4@0+ (1,0) [0|15] "Unitless"  APIM_CISM,APIM
 SG_ ChrgNowEnbl_B_Saved : 56|1@0+ (1,0) [0|1] "SED"  APIM_CISM,APIM
 SG_ ChrgLocIdUnsAck_B_Stat : 57|1@0+ (1,0) [0|1] "SED"  APIM_CISM,APIM
 SG_ ChrgLocIdCurnt_D_Sav : 55|4@0+ (1,0) [0|15] "unitless"  APIM_CISM,IPC,APIM
 SG_ ChrgPrflWknd_No_Actl : 31|24@0+ (1,0) [0|16777215] "unitless"  APIM_CISM,APIM
 SG_ ChrgPrflWkdy_No_Actl : 7|24@0+ (1,0) [0|16777215] "unitless"  APIM_CISM,APIM

BO_ 641 GWM_Send_Signals_10_HS3: 8 GWM
 SG_ ChrgGoTElement_B_Dsply_UB : 57|1@0+ (1,0) [0|1] "SED"  APIM,APIM_CISM
 SG_ ChrgGoTElement_B_Dsply : 58|1@0+ (1,0) [0|1] "SED"  APIM,APIM_CISM
 SG_ BattChrgTrgtSoC_D_Rq : 46|3@0+ (1,0) [0|7] "Percent"  IPC
 SG_ BattChrgTrgtSoC_D_Rq_UB : 43|1@0+ (1,0) [0|1] "SED"  IPC
 SG_ ChrgLocIdCurnt_D_Uns_UB : 59|1@0+ (1,0) [0|1] "SED"  APIM_CISM,APIM
 SG_ ChrgLocIdCurnt_D_Uns : 63|4@0+ (1,0) [0|15] "unitless"  APIM_CISM,APIM
 SG_ IgnPsswrdActv_B_Stat_UB : 54|1@0+ (1,0) [0|1] "SED"  APIM_CISM,APIM
 SG_ IgnPsswrdSetup_B_Rq_UB : 50|1@0+ (1,0) [0|1] "SED"  APIM_CISM,APIM
 SG_ IgnPsswrdLckout_B_Stat_UB : 51|1@0+ (1,0) [0|1] "SED"  APIM_CISM,APIM
 SG_ IgnPsswrdSetup_B_Rq : 52|1@0+ (1,0) [0|1] "SED"  APIM_CISM,APIM
 SG_ IgnPsswrdLckout_B_Stat : 53|1@0+ (1,0) [0|1] "SED"  APIM_CISM,APIM
 SG_ PaakCnnct_D_Stat_UB : 40|1@0+ (1,0) [0|1] "SED"  APIM_CISM,APIM
 SG_ PaakCnnct_D_Stat : 42|2@0+ (1,0) [0|3] "SED"  APIM_CISM,APIM
 SG_ IgnPsswrdActv_B_Stat : 55|1@0+ (1,0) [0|1] "SED"  APIM_CISM,APIM
 SG_ ChrgGoTTouch_B_Stat_UB : 47|1@0+ (1,0) [0|1] "SED"  APIM_CISM,APIM
 SG_ ChrgGoTTouch_B_Stat : 24|1@0+ (1,0) [0|1] "SED"  APIM_CISM,APIM
 SG_ ChrgGoTPrcond_D_Stat_UB : 16|1@0+ (1,0) [0|1] "SED"  APIM_CISM,APIM
 SG_ ChrgGoTPrcond_D_Stat : 26|2@0+ (1,0) [0|3] "SED"  APIM_CISM,APIM
 SG_ ChrgGoTNext_D_Stat_UB : 17|1@0+ (1,0) [0|1] "SED"  APIM_CISM,APIM
 SG_ ChrgGoTNext_D_Stat : 35|4@0+ (1,0) [0|15] "Unitless"  APIM_CISM,APIM
 SG_ ChrgGoTMnte_D_Stat_UB : 18|1@0+ (1,0) [0|1] "SED"  APIM_CISM,APIM
 SG_ ChrgGoTMnte_D_Stat : 39|4@0+ (1,0) [0|15] "SED"  APIM_CISM,APIM
 SG_ ChrgGoTHr_T_Stat_UB : 19|1@0+ (1,0) [0|1] "SED"  APIM_CISM,APIM
 SG_ ChrgGoTHr_T_Stat : 31|5@0+ (1,0) [0|29] "hour"  APIM_CISM,APIM
 SG_ ChrgGoTExtHtr_B_Stat_UB : 8|1@0+ (1,0) [0|1] "SED"  APIM_CISM,APIM
 SG_ ChrgGoTExtHtr_B_Stat : 9|1@0+ (1,0) [0|1] "SED"  APIM_CISM,APIM
 SG_ ChrgGoTElement_D_Stat_UB : 10|1@0+ (1,0) [0|1] "SED"  APIM_CISM,APIM
 SG_ ChrgGoTElement_D_Stat : 23|4@0+ (1,0) [0|15] "Unitless"  APIM_CISM,APIM
 SG_ ChrgGoTAllOn_B_Stat_UB : 11|1@0+ (1,0) [0|1] "SED"  APIM_CISM,APIM
 SG_ ChrgGoTAllOn_B_Stat : 12|1@0+ (1,0) [0|1] "SED"  APIM_CISM,APIM
 SG_ TrlrAidMsgTxt_D2_Rq : 7|6@0+ (1,0) [0|63] "SED"  APIM_CISM,IPC,TRM_ITRM,APIM
 SG_ TrlrAidEnbl_D2_Stat : 15|3@0+ (1,0) [0|7] "SED"  APIM_CISM,IPC,TRM_ITRM,APIM
 SG_ TrlrAidMsgTxt_D2_Rq_UB : 1|1@0+ (1,0) [0|1] "SED"  APIM_CISM,IPC,TRM_ITRM,APIM
 SG_ TrlrAidEnbl_D2_Stat_UB : 0|1@0+ (1,0) [0|1] "SED"  APIM_CISM,IPC,TRM_ITRM,APIM

BO_ 1012 Saved_Charge_Locat_HS3: 8 GWM
 SG_ ChrgLocSaved_B_Dsply : 57|1@0+ (1,0) [0|1] "SED"  APIM,APIM_CISM
 SG_ ChrgLocLongPostv_B_Sav : 59|1@0+ (1,0) [0|1] "SED"  APIM_CISM,APIM
 SG_ ChrgLocLongFrct_An_Sav : 47|20@0+ (1E-006,0) [0|1.048575] "degrees"  APIM_CISM,APIM
 SG_ ChrgLocLongDeg_An_Sav : 39|8@0+ (1,0) [0|255] "degrees"  APIM_CISM,APIM
 SG_ ChrgLocLattPostv_B_Sav : 24|1@0+ (1,0) [0|1] "SED"  APIM_CISM,APIM
 SG_ ChrgLocLattFrct_An_Sav : 7|20@0+ (1E-006,0) [0|1.048575] "degrees"  APIM_CISM,APIM
 SG_ ChrgLocLattDeg_An_Sav : 31|7@0+ (1,0) [0|127] "unitless"  APIM_CISM,APIM
 SG_ ChrgLocId_D_Sav : 19|4@0+ (1,0) [0|15] "unitless"  APIM_CISM,APIM
 SG_ AirCondRec_B_RqVehEl : 56|1@0+ (1,0) [0|1] "SED"  GENERIC
 SG_ ChrgNowCurnt_B_Dsply : 58|1@0+ (1,0) [0|1] "SED"  IPC,APIM_CISM,APIM

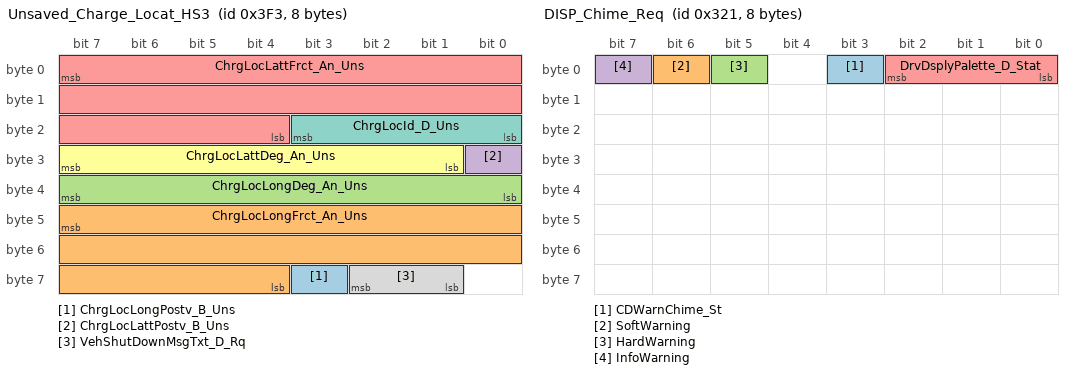
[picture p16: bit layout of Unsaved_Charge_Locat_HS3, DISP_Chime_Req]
BO_ 1011 Unsaved_Charge_Locat_HS3: 8 GWM
 SG_ ChrgLocLongPostv_B_Uns : 59|1@0+ (1,0) [0|1] "SED"  APIM_CISM,APIM
 SG_ ChrgLocLongFrct_An_Uns : 47|20@0+ (1E-006,0) [0|1.048575] "degrees"  APIM_CISM,APIM
 SG_ ChrgLocLongDeg_An_Uns : 39|8@0+ (1,0) [0|255] "degrees"  APIM_CISM,APIM
 SG_ ChrgLocLattPostv_B_Uns : 24|1@0+ (1,0) [0|1] "SED"  APIM_CISM,APIM
 SG_ ChrgLocLattFrct_An_Uns : 7|20@0+ (1E-006,0) [0|1.048575] "degrees"  APIM_CISM,APIM
 SG_ ChrgLocLattDeg_An_Uns : 31|7@0+ (1,0) [0|127] "unitless"  APIM_CISM,APIM
 SG_ ChrgLocId_D_Uns : 19|4@0+ (1,0) [0|15] "unitless"  APIM_CISM,APIM
 SG_ VehShutDownMsgTxt_D_Rq : 58|2@0+ (1,0) [0|3] "SED"  IPC

BO_ 533 APIM_Send_Signals_2: 8 APIM
 SG_ AutoEpbZoomView_B_Stat : 32|1@0+ (1,0) [0|1] "SED"  GWM
 SG_ ClrExitAsstEnbl_D_RqMnu : 60|2@0+ (1,0) [0|3] "SED"  GWM
 SG_ PaakMyKey_D_Rq : 7|2@0+ (1,0) [0|3] "SED"  GWM
 SG_ AutoEpbButtn_B_Stat : 19|1@0+ (1,0) [0|1] "SED"  GWM
 SG_ TrlrAidMde_D_Rq : 5|2@0+ (1,0) [0|3] "SED"  GWM
 SG_ TCU_Init_Actvtn_St : 1|2@0+ (1,0) [0|3] "SED"  GWM
 SG_ TCU_Final_Actvtn_St : 3|2@0+ (1,0) [0|3] "SED"  GWM
 SG_ DcacPw_D_Rq : 62|2@0+ (1,0) [0|3] "SED"  GWM
 SG_ DcacPwReset_B_Rq : 63|1@0+ (1,0) [0|1] "SED"  GWM
 SG_ LghtAmbDrvMde_D_Rq : 49|2@0+ (1,0) [0|3] "SED"  GWM
 SG_ OtaTrg_D_Stat : 41|2@0+ (1,0) [0|3] "SED"  GWM
 SG_ DcacPwLoButtn_B_Stat : 13|1@0+ (1,0) [0|1] "SED"  GWM
 SG_ DcacPwOffButtn_B_Stat : 12|1@0+ (1,0) [0|1] "SED"  GWM
 SG_ DcacPwHiButtn_B_Stat : 14|1@0+ (1,0) [0|1] "SED"  GWM
 SG_ DcacPwResetButtn_B_Stat : 11|1@0+ (1,0) [0|1] "SED"  GWM
 SG_ DcacPwButtn_B_Falt : 15|1@0+ (1,0) [0|1] "SED"  GWM
 SG_ OnbChrgGoTTouch_D_Rq : 43|2@0+ (1,0) [0|3] "SED"  GWM
 SG_ OnbChrgGoTPrcond_D_Rq : 34|2@0+ (1,0) [0|3] "SED"  GWM
 SG_ OnbChrgGoTOn_D_Rq : 25|2@0+ (1,0) [0|3] "SED"  GWM
 SG_ OnbChrgGoTMnte_D_Rq : 47|4@0+ (1,0) [0|15] "minute"  GWM
 SG_ OnbChrgGoTHr_T_Rq : 39|5@0+ (1,0) [0|29] "hour"  GWM
 SG_ OnbChrgGoTExtHtr_D_Rq : 27|2@0+ (1,0) [0|3] "SED"  GWM
 SG_ OnbChrgGoTElement_D_Rq : 31|4@0+ (1,0) [0|15] "Unitless"  GWM
 SG_ OnbChrgGoTDelete_B_Rq : 17|1@0+ (1,0) [0|1] "SED"  GWM
 SG_ OnbChrgClearAll_B_Rq : 18|1@0+ (1,0) [0|1] "SED"  GWM
 SG_ OnbChrgGoTUpdate_B_Rq : 16|1@0+ (1,0) [0|1] "SED"  GWM
 SG_ TrlrAlarmButtn_B_Stat : 50|1@0+ (1,0) [0|1] "SED"  TRM_ITRM,GWM
 SG_ DcacMdeButtn_B_Stat : 8|1@0+ (1,0) [0|1] "SED"  GWM
 SG_ DcacGfciTestBttn_B_Stat : 9|1@0+ (1,0) [0|1] "SED"  GWM
 SG_ TrlrBrkGain_No_Rq : 55|5@0+ (0.5,0) [0|15.5] "unitless"  TRM_ITRM,GWM
 SG_ TrlrHitch_D_RqMnu : 23|4@0+ (1,0) [0|15] "SED"  GWM
 SG_ DcacPwButtn_B_Stat : 10|1@0+ (1,0) [0|1] "SED"  GWM

BO_ 1184 APIM_TCU_Word_Rx_HS3: 8 GWM
 SG_ APIM_TCU_Word_Rx : 7|64@0+ (1,0) [0|1.84467440737096E+019] "unitless"  APIM_CISM,APIM

BO_ 801 DISP_Chime_Req: 8 APIM
 SG_ CDWarnChime_St : 3|1@0+ (1,0) [0|1] "SED"  IPC
 SG_ SoftWarning : 6|1@0+ (1,0) [0|1] "SED"  IPC
 SG_ HardWarning : 5|1@0+ (1,0) [0|1] "SED"  IPC
 SG_ InfoWarning : 7|1@0+ (1,0) [0|1] "SED"  IPC
 SG_ DrvDsplyPalette_D_Stat : 2|3@0+ (1,0) [0|7] "SED"  IPC

BO_ 878 Rear_Climate_Data2: 8 RACM_RCIM
 SG_ ClimtSyncRear2_B_Stat : 58|1@0+ (1,0) [0|1] "SED"  GENERIC,GWM
 SG_ ClimtStHeatRr2_B_Stat : 54|1@0+ (1,0) [0|1] "SED"  GENERIC,GWM
 SG_ ClimtStHeatRl2_B_Stat : 55|1@0+ (1,0) [0|1] "SED"  GENERIC,GWM
 SG_ ClimtStCoolRr2_B_Stat : 52|1@0+ (1,0) [0|1] "SED"  GENERIC,GWM
 SG_ ClimtStCoolRl2_B_Stat : 53|1@0+ (1,0) [0|1] "SED"  GENERIC,GWM
 SG_ ClimtSeatRr2_D_Rq : 39|8@0+ (1,0) [0|64] "SED"  GENERIC,GWM
 SG_ ClimtSeatRl2_D_Rq : 47|8@0+ (1,0) [0|64] "SED"  GENERIC,GWM
 SG_ ClimtRrTe3rd2_D_Stat : 51|2@0+ (1,0) [0|3] "SED"  GENERIC,GWM
 SG_ ClimtRrPw3rd2_B_Stat : 59|1@0+ (1,0) [0|1] "SED"  GENERIC,GWM
 SG_ ClimtRrPnl3rd2_B_Stat : 62|1@0+ (1,0) [0|1] "SED"  GENERIC,GWM
 SG_ ClimtRrPf3rd2_B_Stat : 63|1@0+ (1,0) [0|1] "SED"  GENERIC,GWM
 SG_ ClimtRrFlr3rd2_B_Stat : 61|1@0+ (1,0) [0|1] "SED"  GENERIC,GWM
 SG_ ClimtRrBlwr3rd2_D_Stat : 49|2@0+ (1,0) [0|3] "SED"  GENERIC,GWM
 SG_ ClimtRrAuto3rd2_B_Stat : 60|1@0+ (1,0) [0|1] "SED"  GENERIC,GWM
 SG_ ClimtRearView2_D_Stat : 57|2@0+ (1,0) [0|3] "SED"  GENERIC,GWM
 SG_ ClimtRearTe2_D_Stat : 11|2@0+ (1,0) [0|3] "SED"  GENERIC,GWM
 SG_ ClimtRearTe2_An_Actl : 7|9@0+ (1,0) [0|510] "degrees"  GENERIC,GWM
 SG_ ClimtRearPw2_B_Stat : 29|1@0+ (1,0) [0|1] "SED"  GENERIC,GWM
 SG_ ClimtRearPnlFlr2_B_Stat : 13|1@0+ (1,0) [0|1] "SED"  GENERIC,GWM
 SG_ ClimtRearPnl2_B_Stat : 14|1@0+ (1,0) [0|1] "SED"  GENERIC,GWM
 SG_ ClimtRearFlr2_B_Stat : 12|1@0+ (1,0) [0|1] "SED"  GENERIC,GWM
 SG_ ClimtRearBlwr2_D_Stat : 9|2@0+ (1,0) [0|3] "SED"  GENERIC,GWM
 SG_ ClimtRearBlwr2_An_Actl : 23|9@0+ (1,0) [0|510] "degrees"  GENERIC,GWM
 SG_ ClimtRearAuto2_B_Stat : 30|1@0+ (1,0) [0|1] "SED"  GENERIC,GWM

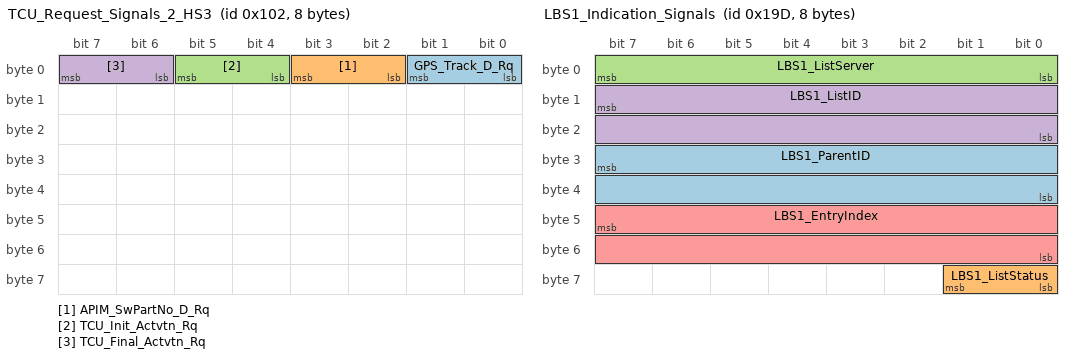
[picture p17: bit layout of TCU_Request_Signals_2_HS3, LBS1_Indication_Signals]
BO_ 258 TCU_Request_Signals_2_HS3: 8 GWM
 SG_ GPS_Track_D_Rq : 1|2@0+ (1,0) [0|3] "SED"  APIM_CISM,APIM
 SG_ APIM_SwPartNo_D_Rq : 3|2@0+ (1,0) [0|3] "SED"  APIM_CISM,APIM
 SG_ TCU_Init_Actvtn_Rq : 5|2@0+ (1,0) [0|3] "SED"  APIM_CISM,APIM
 SG_ TCU_Final_Actvtn_Rq : 7|2@0+ (1,0) [0|3] "SED"  APIM_CISM,APIM

BO_ 1192 APIM_TCU_Word_Tx: 8 APIM
 SG_ APIM_TCU_Word_Tx : 7|64@0+ (1,0) [0|1.84467440737096E+019] "unitless"  GWM

BO_ 413 LBS1_Indication_Signals: 8 APIM
 SG_ LBS1_ParentID : 31|16@0+ (1,0) [0|65535] "unitless"  RACM_RCIM,IPC
 SG_ LBS1_ListStatus : 57|2@0+ (1,0) [0|3] "SED"  IPC,RACM_RCIM
 SG_ LBS1_ListServer : 7|8@0+ (1,0) [0|255] "unitless"  IPC,RACM_RCIM
 SG_ LBS1_ListID : 15|16@0+ (1,0) [0|65535] "unitless"  IPC,RACM_RCIM
 SG_ LBS1_EntryIndex : 47|16@0+ (1,0) [0|65535] "unitless"  IPC,RACM_RCIM

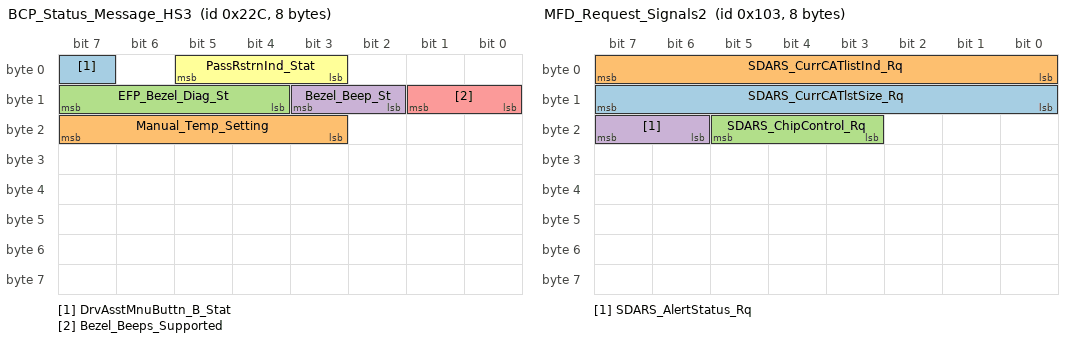
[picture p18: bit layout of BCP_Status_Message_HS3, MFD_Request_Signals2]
BO_ 556 BCP_Status_Message_HS3: 8 GWM
 SG_ DrvAsstMnuButtn_B_Stat : 7|1@0+ (1,0) [0|1] "SED"  APIM_CISM,APIM
 SG_ Manual_Temp_Setting : 23|5@0+ (1,0) [0|31] "SED"  APIM,APIM_CISM
 SG_ EFP_Bezel_Diag_St : 15|4@0+ (1,0) [0|15] "SED"  APIM,APIM_CISM
 SG_ Bezel_Beep_St : 11|2@0+ (1,0) [0|3] "SED"  APIM,APIM_CISM
 SG_ Bezel_Beeps_Supported : 9|2@0+ (1,0) [0|3] "SED"  APIM,APIM_CISM
 SG_ PassRstrnInd_Stat : 5|3@0+ (1,0) [0|7] "SED"  GENERIC

BO_ 259 MFD_Request_Signals2: 8 APIM
 SG_ SDARS_CurrCATlstSize_Rq : 15|8@0+ (1,0) [0|255] "unitless"  APIM_CISM,ACM
 SG_ SDARS_CurrCATlistInd_Rq : 7|8@0+ (1,0) [0|255] "unitless"  APIM_CISM,ACM
 SG_ SDARS_ChipControl_Rq : 21|3@0+ (1,0) [0|7] "SED"  APIM_CISM,ACM
 SG_ SDARS_AlertStatus_Rq : 23|2@0+ (1,0) [0|3] "SED"  APIM_CISM,ACM

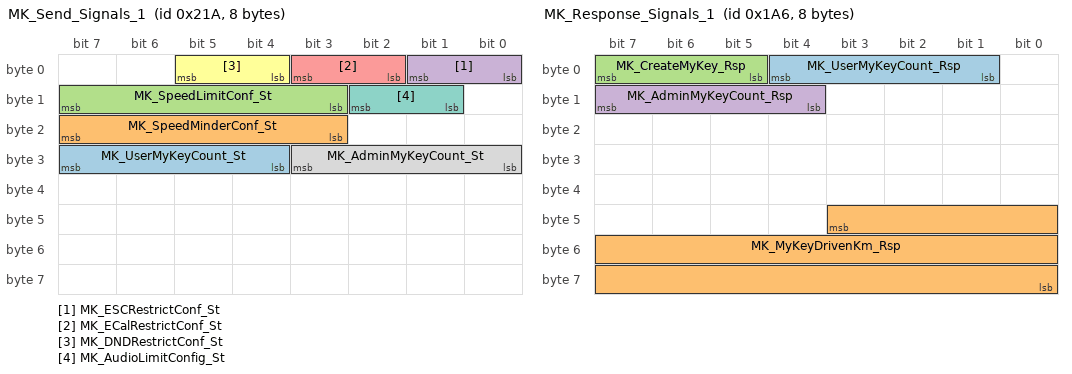
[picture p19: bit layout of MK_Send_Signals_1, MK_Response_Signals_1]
BO_ 538 MK_Send_Signals_1: 8 IPC
 SG_ MK_UserMyKeyCount_St : 31|4@0+ (1,0) [0|13] "SED"  APIM_CISM,APIM
 SG_ MK_SpeedMinderConf_St : 23|5@0+ (1,0) [0|31] "SED"  APIM_CISM,APIM
 SG_ MK_SpeedLimitConf_St : 15|5@0+ (1,0) [0|31] "SED"  APIM_CISM,APIM
 SG_ MK_ESCRestrictConf_St : 1|2@0+ (1,0) [0|3] "SED"  APIM_CISM,GENERIC
 SG_ MK_ECalRestrictConf_St : 3|2@0+ (1,0) [0|3] "SED"  APIM_CISM,APIM
 SG_ MK_DNDRestrictConf_St : 5|2@0+ (1,0) [0|3] "SED"  APIM_CISM,APIM
 SG_ MK_AudioLimitConfig_St : 10|2@0+ (1,0) [0|3] "SED"  APIM_CISM,APIM
 SG_ MK_AdminMyKeyCount_St : 27|4@0+ (1,0) [0|13] "SED"  APIM_CISM,APIM

BO_ 422 MK_Response_Signals_1: 8 IPC
 SG_ MK_UserMyKeyCount_Rsp : 4|4@0+ (1,0) [0|15] "SED"  APIM_CISM,APIM
 SG_ MK_MyKeyDrivenKm_Rsp : 43|20@0+ (1,0) [0|1048575] "km"  APIM_CISM,APIM
 SG_ MK_CreateMyKey_Rsp : 7|3@0+ (1,0) [0|7] "SED"  APIM_CISM,APIM
 SG_ MK_AdminMyKeyCount_Rsp : 15|4@0+ (1,0) [0|15] "SED"  APIM_CISM,APIM

BO_ 1020 Personality_APIM_Data4: 8 APIM
 SG_ CtrStkPersIndex2_D_Actl : 39|3@0+ (1,0) [0|7] "SED"  IPC
 SG_ CtrStkFeatConfig2Actl : 7|16@0+ (1,0) [0|65535] "Undefined"  IPC
 SG_ CtrStkFeat2NoActl : 23|16@0+ (1,0) [0|65535] "Undefined"  IPC
 SG_ CtrStkDsplyOp2_D_Rq : 36|3@0+ (1,0) [0|7] "SED"  IPC

BO_ 1007 Personality_IPC_Data_3: 8 IPC
 SG_ PersIndexIpc2_D_Actl : 39|3@0+ (1,0) [0|7] "SED"  APIM,APIM_CISM
 SG_ FeatNoIpc2Actl : 23|16@0+ (1,0) [0|65535] "Number"  APIM,APIM_CISM
 SG_ FeatConfigIpc2Actl : 7|16@0+ (1,0) [0|65535] "unitless"  APIM,APIM_CISM

BO_TX_BU_ 502 : APIM_CISM,APIM;
BO_TX_BU_ 1116 : APIM_CISM,APIM;
BO_TX_BU_ 529 : APIM_CISM,APIM;
BO_TX_BU_ 500 : APIM_CISM,APIM;
BO_TX_BU_ 503 : APIM_CISM,APIM;
BO_TX_BU_ 412 : APIM_CISM,APIM;
BO_TX_BU_ 493 : APIM_CISM,APIM;
BO_TX_BU_ 511 : APIM_CISM,APIM;
BO_TX_BU_ 257 : APIM_CISM,APIM;
BO_TX_BU_ 713 : APIM_CISM,APIM;
BO_TX_BU_ 600 : APIM_CISM,APIM;
BO_TX_BU_ 708 : APIM_CISM,ACM;
BO_TX_BU_ 414 : APIM_CISM,ACM;
BO_TX_BU_ 716 : APIM_CISM,APIM;
BO_TX_BU_ 533 : APIM_CISM,APIM;
BO_TX_BU_ 801 : ACM,APIM_CISM,APIM;
BO_TX_BU_ 1192 : APIM_CISM,APIM;
BO_TX_BU_ 413 : APIM_CISM,APIM;
BO_TX_BU_ 556 : FCIMB,GWM;
BO_TX_BU_ 259 : APIM_CISM,APIM;
BO_TX_BU_ 1020 : APIM_CISM,APIM;
CM_ SG_ 502 Dsp_StartItemIndexRq "Object Media Player BT SDCard.GetMPInfo.StartItemIndex
USB.GetMPInfo.StartItemIndex
SingleCD.GetMPInfo.StartItemIndex

$FFFF: Inactive";
CM_ SG_ 502 Dsp_NbrOfItems2_Rq "Object Media Player 
BT Audio.GetMPInfo.NbrOfItems
SDCard.GetMPInfo.NbrOfItems
USB.GetMPInfo.NbrOfItems
SingleCD.GetMPInfo.NbrOfItems";
CM_ SG_ 502 Dsp_ItemNameLength2_Rq "Object Media Player 
BT Audio.GetMPInfo.ItemNameLength
SDCard.GetMPInfo.ItemNameLength
USB.GetMPInfo.ItemNameLength
SingleCD.GetMPInfo.ItemNameLength";
CM_ SG_ 502 Dsp_FolderNumber2_Rq "Object Media Player 
BT Audio.GetMPInfo.FolderNumber
USB.GetMPInfo.FolderNumber
SDCard.GetMPInfo.FolderNumber
SingleCD.GetMPInfo.FolderNumber

$FFFF: Inactive";
CM_ SG_ 502 Dsp_FolderContent_Rq "Object Media Player 
BT Audio.GetMPInfo.FolderContent
SDCard.GetMPInfo.FolderContent
USB.GetMPInfo.FolderContent
SingleCD.GetMPinfo.Foldercontent

Note: Value table entries were truncated from:
$0: ..FolderNumber
$1: ..OfParameterFolderNumber";
CM_ SG_ 502 Dsp_CutItem2_Rq "Object Media Player 
BT Audio.GetMPInfo.CutItemName
SDCard.GetMPInfo.CutItemName
USB.GetMPInfo.CutItemName
SingleCD.GetMPInfo.CutItemName

Note: value table entry for value $2 was truncated from:
OneQuarterFromTheBeginningThreeQuarterFromTheEnd";
CM_ SG_ 502 Dsp_AudioSourceSel2_Rq "Object Media Player 
BT Audio.GetMPInfo.AudioSource
SDCard.GetMPInfo.AudioSource
USB.GetMPInfo.AudioSource
SingleCD.GetMPInfo.AudioSource";
CM_ SG_ 500 Dsp_SourceSetTrack_Rq "Object Media Player BTAudio.SetTrack
Object Media Player USB.SetTrack
Object Single CD.SetTrack.AudioSource
";
CM_ SG_ 500 Dsp_ItemNameLength_Rq "Object Media Player BTAudio.GetFolderName.ItemNameLength
Object Media Player USB.GetFolderName.ItemNameLength
Object Single CD.GetFolderName.ItemNameLength";
CM_ SG_ 500 Dsp_GetCDTOCDData_Rq "GetCDTOCData";
CM_ SG_ 500 Dsp_FolderNumber_Rq "Object Media Player BTAudio.GetFolderName.FolderNumber
Object Media Player USB.GetFolderName.FolderNumber
Object Single CD.GetFolderName.FolderNumber";
CM_ SG_ 500 Dsp_CutItem_Rq "Object Media Player BTAudio.GetFolderName.CutItemName
Object Media Player USB.GetFolderName.CutItemName
Object Single CD.GetFolderName.CutItemName

Note: value table entry for value $2 was truncated from:
OneQuarterFromTheBeginningThreeQuarterFromTheEnd";
CM_ SG_ 500 Dsp_AudioSourceSel_Rq "Object Media Player 
{ BTAudio.GetFolderName, 
SDCard.GetFolderName,
USB.GetFolderName,
BTAudio.SetTrack,
SD Card.SetTrack}.AudioSource
USB.SetTrack.AudioSource
Object Single CD.GetFolderName.AudioSource
Object Single CD.SetTrack.AudioSource";
CM_ SG_ 503 Dsp_PlayFrstTrInFldr_Rq "Object Single CD.PlayFirstTrackInFolder
Object Media Player BTAudio.PlayFirstTrackInFolder.FolderNumber
Object Media Player USB.PlayFirstTrackInFolder.FolderNumber

$FFFF: Inactive";
CM_ SG_ 503 Dsp_ItemIndex_Rq "Object Media Player BTAudio.GetDetailedMPInfo.ItemIndex
Object Media Player USB.GetDetailedMPInfo.ItemIndex

$FFFF: Inactive";
CM_ SG_ 503 Dsp_FolderNumber3_Rq "Object Media Player BTAudio.GetDetailedMPInfo.FolderNumber
Object Media Player USB.GetDetailedMPInfo.FolderNumber

$FFFF: Inactive";
CM_ SG_ 503 Dsp_AudioSourceSel3_Rq "Objects Media Player  {BTAudio, USB}.GetDetailedMPInfo.AudioSource

Objects Media Player {Single CD, BTAudio, USB}.PlayFirstTrackInFolder.AudioSource";
CM_ SG_ 412 LBC2_StartItemInd "Object. ListBrowser.ItemInf.Rq.StartItemInd
0x0000:Inactive
0x0001:1
0xFFFE:65634
0xFFFF:Reserved";
CM_ SG_ 412 LBC2_SetListServ "Object. ListBrowser.ItemInf.Rq.SetListServ
0x00:Inactive
0x01:ServerID_1
0xFF:ALL";
CM_ SG_ 412 LBC2_Opcode "Object. ListBrowser.ItemInf.Rq.Opcode";
CM_ SG_ 412 LBC2_NbrOfItems "Object. ListBrowser.ItemInf.Rq.NbrOfItems
0x00:Inactive
0x01:1Item
0x3F:63Items";
CM_ SG_ 412 LBC2_ItemIndex "Object. ListBrowser.ItemInf.Rq.ItemIndex
0x0000:BrowseActiveListID
0x0001:EntryIndex_1
0xFFFF:ParentOfActiveListID";
CM_ SG_ 412 LBC2_ActiveListID "Object. ListBrowser.ItemInf.Rq.ActiveListID
0x0000:Root
0xFFFF:Reserved";
CM_ SG_ 493 Dsp_StatLiScanCancel_Rq "Object Tuner.StationListScan";
CM_ SG_ 493 Dsp_StationList_Rq "Object Tuner.GetStationList(StationList)
(Parameter1)";
CM_ SG_ 493 Dsp_StartIndex3_Rq "Object TunerGetStationList(StartingIndex)
(Parameter3)";
CM_ SG_ 493 Dsp_RefreshFlag "Object Tuner.GetStationList(StationList)
(Parameter5)";
CM_ SG_ 493 Dsp_PTYCode_Rq "Object Tuner.GetStationList(PTYCode)
(Parramater4)

$0: Invalid
$1: PTY 1 (News)
..
$1F: PTY 31 (Alarm)";
CM_ SG_ 493 Dsp_ListSize_Rq "Object Tuner.GetStationList(ListSize)
(Parameter2)";
CM_ SG_ 493 Dsp_AFJump_Rq "Object Tuner.AFJump.Rq";
CM_ SG_ 511 Dsp_TUStartIndex2_Rq "Object Tuner.GetTUPresetInfo.StartIndex2
Object DAB.GetTUPresetInfo.StartIndex2
Object SDARS.GetTUPresetInfo.StartIndex2

$1-$FF: Preset 1 to 255";
CM_ SG_ 511 Dsp_TUPresetArea_Rq "Object Tuner.GetTUPresetInfo.PresetArea
Object DAB.GetTUPresetInfo.PresetArea
Object SDARS.GetTUPresetInfo.PresetArea";
CM_ SG_ 511 Dsp_TUNbrOfPresets_Rq "Object Tuner.GetTUPresetInfo.NumberOfPresets
Object DAB.GetTUPresetInfo.NumberOfPresets
Object SDARS.GetTUPresetInfo.NumberOfPresets

$1-$1E: Preset 1 to 30";
CM_ SG_ 511 Dsp_SetCurrTUPreset_Rq "Object Tuner.GetTUPresetInfo.SetCurrentTUPreset
Object DAB.GetTUPresetInfo.SetCurrentTUPreset
Object SDARS.GetTUPresetInfo.SetCurrentTUPreset

$1-$1E: Preset 1 to 30";
CM_ SG_ 511 Dsp_SetCurrTUBand_Rq "Object Tuner.SetCurrTUBand
Object DAB.SetCurrTUBand
Object SDARS.SetCurrTUBand
";
CM_ SG_ 257 MFD_SetTagMode "Used by MFD to distribute actual Master Clock data to the Slave";
CM_ SG_ 257 MFD_SetRBDSMode "Used by MFD to distribute actual Master Clock data to the Slave";
CM_ SG_ 257 MFD_SetHDModeRq "Used by MFD to distribute actual Master Clock data to the Slave";
CM_ SG_ 257 MFD_GetTagInfo "Used by MFD to distribute actual Master Clock data to the Slave";
CM_ BO_ 382 "ECM, PCM Gas Only msg";
CM_ BO_ 600 "Tx by HS3 APIM";
CM_ SG_ 600 APIM_RFA_BLEM_Tx "Tx by HS3 APIM";
CM_ SG_ 708 TMCSrvr_TMCClnt_WORD_Tx "MM ISO 15765-2 Message Catalogue RDISP2 - AUDIO";
CM_ SG_ 414 LBS2_ParentID "Object. ListBrowser.ItemInf.Rq.ActiveListID
0x0000:Root
0xFFFF:Reserved";
CM_ SG_ 414 LBS2_ListID "Object. ListBrowser.ItemInf.Rq.ItemIndex
0x0000:BrowseActiveListID
0x0001:EntryIndex_1
0xFFFF:ParentOfActiveListID";
CM_ SG_ 414 LBS2_EntryIndex "Object. ListBrowser.ItemInf.Rq.ActiveListID
0x0000:Root
0xFFFF:Reserved";
CM_ SG_ 641 IgnPsswrdSetup_B_Rq "ABSGenSigTimeoutTime=1000";
CM_ SG_ 641 IgnPsswrdLckout_B_Stat "ABSGenSigTimeoutTime=1000";
CM_ BO_ 1184 "TP message";
CM_ SG_ 1192 APIM_TCU_Word_Tx "Tx by HS3 APIM";
CM_ SG_ 413 LBS1_ParentID "Object. ListBrowser.ItemInf.Rq.ActiveListID
0x0000:Root
0xFFFF:Reserved";
CM_ SG_ 413 LBS1_ListID "Object. ListBrowser.ItemInf.Rq.ItemIndex
0x0000:BrowseActiveListID
0x0001:EntryIndex_1
0xFFFF:ParentOfActiveListID";
CM_ SG_ 413 LBS1_EntryIndex "Object. ListBrowser.ItemInf.Rq.ActiveListID
0x0000:Root
0xFFFF:Reserved";
CM_ SG_ 556 EFP_Bezel_Diag_St "Object:BezelDiagnostics.EFP_Bezel_Diag.St";
CM_ SG_ 556 Bezel_Beep_St "Object:VehicleSettings.Bezel_Beeps.St.Status";
CM_ SG_ 556 Bezel_Beeps_Supported "Object: Vehicle Settings. Bezel_Beeps_Supported.St";
CM_ SG_ 259 SDARS_CurrCATlstSize_Rq "Object:SDARSClient.CurrentCatList.Rq.NumberOfItems 

0x00: Invalid
0x01: List Size 1
0x02: List Size 2
....
0x1E: List Size 30
0xFF: No Entry
";
CM_ SG_ 259 SDARS_CurrCATlistInd_Rq "ObjectTuner.SDARSTuner.CurrentCATList
$0: Inactive
$FF:No_Entry";
CM_ SG_ 259 SDARS_AlertStatus_Rq "Object.SDARSClient.AlertStatus.Rq.Status";
CM_ SG_ 538 MK_UserMyKeyCount_St "Object MyKey.SystemKeyCount_St
[Parameter1]";
CM_ SG_ 538 MK_SpeedMinderConf_St "Object MyKey.SpeedMinderConfig_St";
CM_ SG_ 538 MK_SpeedLimitConf_St "Object MyKey.SpeedLimitConfig_St";
CM_ SG_ 538 MK_ECalRestrictConf_St "Object MyKey.ECallRestrictionConfig_St";
CM_ SG_ 538 MK_DNDRestrictConf_St "Object MyKey.DNDRestrictionConfig_St";
CM_ SG_ 538 MK_AudioLimitConfig_St "Object MyKey.AudioLimitConfig_St";
CM_ SG_ 538 MK_AdminMyKeyCount_St "Object MyKey.SystemKeyCount_St
[Parameter2]";
BA_DEF_ BO_  "FrameRouting" STRING ;
BA_DEF_ BO_  "FrameGatewayNetwork" STRING ;
BA_DEF_ BO_  "NetworkInitialization" ENUM  "No","Yes";
BA_DEF_ BO_  "FrameGatewayId" HEX 0 1407;
BA_DEF_ BO_  "EventRateOfChange" INT 10 10000;
BA_DEF_ BO_  "GenMsgStartDelayTime" INT 0 10000;
BA_DEF_ BO_  "GenMsgNrOfRepetition" INT 0 100;
BA_DEF_ BO_  "GenMsgDelayTime" INT 0 1000;
BA_DEF_ BO_  "GenMsgCycleTime" INT 0 100000;
BA_DEF_ BO_  "GenMsgSendType" ENUM  "FixedPeriodic","Event","EnabledPeriodic","NotUsed","NotUsed","EventPeriodic","NotUsed","NotUsed","NoMsgSendType";
BA_DEF_ SG_  "U_U55X_MY2022_Tx" ENUM  "No","Yes";
BA_DEF_ SG_  "U_CD542_MY2021_Tx" ENUM  "No","Yes";
BA_DEF_ SG_  "ECGUsedTxSignal" ENUM  "No","Yes";
BA_DEF_ SG_  "U_T6_MCA_MY2020_Tx" ENUM  "No","Yes";
BA_DEF_ SG_  "U_P702_MY2021_Tx" ENUM  "No","Yes";
BA_DEF_ SG_  "U_CX727_MY2021_Tx" ENUM  "No","Yes";
BA_DEF_ SG_  "U_FNV2_IVI_Rx" ENUM  "No","Yes";
BA_DEF_ SG_  "U_U55X_MY2022_Rx" ENUM  "No","Yes";
BA_DEF_ SG_  "U_CD542_MY2021_Rx" ENUM  "No","Yes";
BA_DEF_ SG_  "ECGUsedRxSignal" ENUM  "No","Yes";
BA_DEF_ SG_  "U_T6_MCA_MY2020_Rx" ENUM  "No","Yes";
BA_DEF_ SG_  "U_P702_MY2021_Rx" ENUM  "No","Yes";
BA_DEF_ SG_  "U_CX727_MY2021_Rx" ENUM  "No","Yes";
BA_DEF_ SG_  "GenSigStartValue" HEX 0 268435455;
BA_DEF_ SG_  "MetaData" ENUM  "No","Yes";
BA_DEF_ SG_  "ContentDependant" ENUM  "No","Yes";
BA_DEF_ SG_  "GenSigStartValueInteger" INT 0 1000000000;
BA_DEF_ SG_  "UsedOnPgmDBC" ENUM  "No","Yes";
BA_DEF_ SG_  "WakeupSignal" ENUM  "No","Yes";
BA_DEF_ SG_  "GenSigInactiveValue" INT 0 100000;
BA_DEF_ SG_  "GenSigSendType" ENUM  "Cyclic","OnWrite","vector_leerstring","OnChange","vector_leerstring","IfActive","vector_leerstring","NoSigSendType";
BA_DEF_ BO_  "OvtpPushApplication" ENUM  "FALSE","TRUE";
BA_DEF_ BO_  "SCP_FreshnessValueLength" INT 0 512;
BA_DEF_ BO_  "SCP_FreshnessValueTxLength" INT 0 512;
BA_DEF_ BO_  "SCP_AuthInfoTxLength" INT 0 512;
BA_DEF_ BO_  "GenMsgRoutingTimeoutTime" INT 0 5000;
BA_DEF_ BO_  "MessageGateway" ENUM  "No","Yes";
BA_DEF_ BO_  "NmAsrMessage" ENUM  "No","Yes";
BA_DEF_ BO_  "DiagState" ENUM  "No","Yes";
BA_DEF_ BO_  "TpTxIndex" INT 0 536870911;
BA_DEF_ BO_  "DiagRequest" ENUM  "No","Yes";
BA_DEF_ BO_  "DiagResponse" ENUM  "No","Yes";
BA_DEF_ BO_  "GenMsgILSupport" ENUM  "No","Yes";
BA_DEF_DEF_  "FrameRouting" "";
BA_DEF_DEF_  "FrameGatewayNetwork" "NONE";
BA_DEF_DEF_  "NetworkInitialization" "Yes";
BA_DEF_DEF_  "FrameGatewayId" 0;
BA_DEF_DEF_  "EventRateOfChange" 10000;
BA_DEF_DEF_  "GenMsgStartDelayTime" 0;
BA_DEF_DEF_  "GenMsgNrOfRepetition" 1;
BA_DEF_DEF_  "GenMsgDelayTime" 20;
BA_DEF_DEF_  "GenMsgCycleTime" 0;
BA_DEF_DEF_  "GenMsgSendType" "NoMsgSendType";
BA_DEF_DEF_  "U_U55X_MY2022_Tx" "No";
BA_DEF_DEF_  "U_CD542_MY2021_Tx" "No";
BA_DEF_DEF_  "ECGUsedTxSignal" "No";
BA_DEF_DEF_  "U_T6_MCA_MY2020_Tx" "No";
BA_DEF_DEF_  "U_P702_MY2021_Tx" "No";
BA_DEF_DEF_  "U_CX727_MY2021_Tx" "No";
BA_DEF_DEF_  "U_FNV2_IVI_Rx" "No";
BA_DEF_DEF_  "U_U55X_MY2022_Rx" "No";
BA_DEF_DEF_  "U_CD542_MY2021_Rx" "No";
BA_DEF_DEF_  "ECGUsedRxSignal" "No";
BA_DEF_DEF_  "U_T6_MCA_MY2020_Rx" "No";
BA_DEF_DEF_  "U_P702_MY2021_Rx" "No";
BA_DEF_DEF_  "U_CX727_MY2021_Rx" "No";
BA_DEF_DEF_  "GenSigStartValue" 0;
BA_DEF_DEF_  "MetaData" "No";
BA_DEF_DEF_  "ContentDependant" "No";
BA_DEF_DEF_  "GenSigStartValueInteger" 0;
BA_DEF_DEF_  "UsedOnPgmDBC" "Yes";
BA_DEF_DEF_  "WakeupSignal" "No";
BA_DEF_DEF_  "GenSigInactiveValue" 0;
BA_DEF_DEF_  "GenSigSendType" "NoSigSendType";
BA_DEF_DEF_  "OvtpPushApplication" "FALSE";
BA_DEF_DEF_  "SCP_FreshnessValueLength" 64;
BA_DEF_DEF_  "SCP_FreshnessValueTxLength" 11;
BA_DEF_DEF_  "SCP_AuthInfoTxLength" 53;
BA_DEF_DEF_  "GenMsgRoutingTimeoutTime" 0;
BA_DEF_DEF_  "MessageGateway" "No";
BA_DEF_DEF_  "NmAsrMessage" "No";
BA_DEF_DEF_  "DiagState" "No";
BA_DEF_DEF_  "TpTxIndex" 0;
BA_DEF_DEF_  "DiagRequest" "No";
BA_DEF_DEF_  "DiagResponse" "No";
BA_DEF_DEF_  "GenMsgILSupport" "Yes";
BA_ "FrameRouting" BO_ 1001 "HS2_CAN,0x3E9;";
BA_ "FrameGatewayNetwork" BO_ 1001 "HS2_CAN";
BA_ "FrameGatewayId" BO_ 1001 1001;
BA_ "NetworkInitialization" BO_ 1916 0;
BA_ "GenMsgDelayTime" BO_ 1916 0;
BA_ "GenMsgSendType" BO_ 1916 1;
BA_ "DiagResponse" BO_ 1916 1;
BA_ "GenMsgILSupport" BO_ 1916 0;
BA_ "NetworkInitialization" BO_ 1908 0;
BA_ "GenMsgDelayTime" BO_ 1908 0;
BA_ "GenMsgSendType" BO_ 1908 1;
BA_ "DiagRequest" BO_ 1908 1;
BA_ "GenMsgILSupport" BO_ 1908 0;
BA_ "NetworkInitialization" BO_ 1432 0;
BA_ "GenMsgCycleTime" BO_ 1432 1000;
BA_ "GenMsgSendType" BO_ 1432 0;
BA_ "NmAsrMessage" BO_ 1432 1;
BA_ "GenMsgILSupport" BO_ 1432 0;
BA_ "NetworkInitialization" BO_ 1923 0;
BA_ "GenMsgDelayTime" BO_ 1923 0;
BA_ "GenMsgSendType" BO_ 1923 1;
BA_ "DiagRequest" BO_ 1923 1;
BA_ "GenMsgILSupport" BO_ 1923 0;
BA_ "NetworkInitialization" BO_ 1931 0;
BA_ "GenMsgDelayTime" BO_ 1931 0;
BA_ "GenMsgSendType" BO_ 1931 1;
BA_ "DiagResponse" BO_ 1931 1;
BA_ "GenMsgILSupport" BO_ 1931 0;
BA_ "NetworkInitialization" BO_ 1478 0;
BA_ "GenMsgCycleTime" BO_ 1478 1000;
BA_ "GenMsgSendType" BO_ 1478 0;
BA_ "NmAsrMessage" BO_ 1478 1;
BA_ "GenMsgILSupport" BO_ 1478 0;
BA_ "GenMsgCycleTime" BO_ 1245 1000;
BA_ "GenMsgSendType" BO_ 1245 5;
BA_ "GenMsgCycleTime" BO_ 1242 1000;
BA_ "GenMsgSendType" BO_ 1242 5;
BA_ "FrameRouting" BO_ 1022 "MS2_CAN,0x3FE;";
BA_ "FrameGatewayNetwork" BO_ 1022 "MS2_CAN";
BA_ "FrameGatewayId" BO_ 1022 1022;
BA_ "FrameRouting" BO_ 1021 "MS2_CAN,0x3FD;";
BA_ "FrameGatewayNetwork" BO_ 1021 "MS2_CAN";
BA_ "FrameGatewayId" BO_ 1021 1021;
BA_ "FrameRouting" BO_ 1018 "MS2_CAN,0x3FA;";
BA_ "FrameGatewayNetwork" BO_ 1018 "MS2_CAN";
BA_ "FrameGatewayId" BO_ 1018 1018;
BA_ "GenMsgSendType" BO_ 502 1;
BA_ "FrameRouting" BO_ 955 "HS1_CAN,0x3BB;";
BA_ "FrameGatewayNetwork" BO_ 955 "HS1_CAN";
BA_ "FrameGatewayId" BO_ 955 955;
BA_ "GenMsgCycleTime" BO_ 1116 1000;
BA_ "GenMsgSendType" BO_ 1116 5;
BA_ "GenMsgCycleTime" BO_ 1113 50;
BA_ "GenMsgSendType" BO_ 1113 0;
BA_ "FrameRouting" BO_ 1255 "FD1_CAN,0x4E7;MS1_CAN,0x4E7";
BA_ "FrameRouting" BO_ 1254 "FD1_CAN,0x4E6;MS1_CAN,0x4E6";
BA_ "FrameRouting" BO_ 1253 "FD1_CAN,0x4E5;MS1_CAN,0x4E5";
BA_ "FrameRouting" BO_ 1252 "FD1_CAN,0x4E4;MS1_CAN,0x4E4";
BA_ "FrameRouting" BO_ 1251 "FD1_CAN,0x4E3;MS1_CAN,0x4E3";
BA_ "FrameRouting" BO_ 1250 "FD1_CAN,0x4E2;MS1_CAN,0x4E2";
BA_ "FrameRouting" BO_ 1249 "FD1_CAN,0x4E1;MS1_CAN,0x4E1";
BA_ "FrameRouting" BO_ 1248 "FD1_CAN,0x4E0;MS1_CAN,0x4E0";
BA_ "GenMsgCycleTime" BO_ 1256 1000;
BA_ "GenMsgSendType" BO_ 1256 5;
BA_ "GenMsgCycleTime" BO_ 529 1000;
BA_ "GenMsgSendType" BO_ 529 5;
BA_ "GenMsgCycleTime" BO_ 642 1000;
BA_ "GenMsgSendType" BO_ 642 5;
BA_ "GenMsgCycleTime" BO_ 893 1000;
BA_ "GenMsgSendType" BO_ 893 0;
BA_ "GenMsgSendType" BO_ 500 1;
BA_ "GenMsgSendType" BO_ 503 1;
BA_ "GenMsgSendType" BO_ 412 1;
BA_ "GenMsgSendType" BO_ 493 1;
BA_ "GenMsgSendType" BO_ 511 1;
BA_ "GenMsgSendType" BO_ 257 1;
BA_ "TpTxIndex" BO_ 713 27;
BA_ "FrameRouting" BO_ 382 "FD1_CAN,0x17E;";
BA_ "FrameGatewayNetwork" BO_ 382 "FD1_CAN";
BA_ "FrameGatewayId" BO_ 382 382;
BA_ "FrameRouting" BO_ 877 "MS1_CAN,0x36D;";
BA_ "FrameGatewayNetwork" BO_ 877 "MS1_CAN";
BA_ "FrameGatewayId" BO_ 877 877;
BA_ "FrameRouting" BO_ 592 "HS4_CAN,0x250";
BA_ "FrameGatewayNetwork" BO_ 592 "HS4_CAN";
BA_ "FrameGatewayId" BO_ 592 592;
BA_ "TpTxIndex" BO_ 592 50;
BA_ "TpTxIndex" BO_ 600 50;
BA_ "TpTxIndex" BO_ 708 33;
BA_ "GenMsgSendType" BO_ 414 1;
BA_ "GenMsgCycleTime" BO_ 1239 1000;
BA_ "GenMsgSendType" BO_ 1239 5;
BA_ "TpTxIndex" BO_ 716 33;
BA_ "FrameRouting" BO_ 1013 "HS1_CAN,0x3F5;";
BA_ "FrameGatewayNetwork" BO_ 1013 "HS1_CAN";
BA_ "FrameGatewayId" BO_ 1013 1013;
BA_ "GenMsgCycleTime" BO_ 641 1000;
BA_ "GenMsgSendType" BO_ 641 5;
BA_ "FrameRouting" BO_ 1012 "HS1_CAN,0x3F4;";
BA_ "FrameGatewayNetwork" BO_ 1012 "HS1_CAN";
BA_ "FrameGatewayId" BO_ 1012 1012;
BA_ "FrameRouting" BO_ 1011 "FD1_CAN,0x3F3;HS1_CAN,0x3F3";
BA_ "GenMsgCycleTime" BO_ 533 1000;
BA_ "GenMsgSendType" BO_ 533 5;
BA_ "FrameRouting" BO_ 1184 "HS4_CAN,0x4A0";
BA_ "FrameGatewayNetwork" BO_ 1184 "HS4_CAN";
BA_ "FrameGatewayId" BO_ 1184 1184;
BA_ "TpTxIndex" BO_ 1184 20;
BA_ "GenMsgCycleTime" BO_ 801 1000;
BA_ "GenMsgSendType" BO_ 801 5;
BA_ "GenMsgCycleTime" BO_ 878 1000;
BA_ "GenMsgSendType" BO_ 878 5;
BA_ "FrameRouting" BO_ 258 "HS4_CAN,0x102;";
BA_ "FrameGatewayNetwork" BO_ 258 "HS4_CAN";
BA_ "FrameGatewayId" BO_ 258 258;
BA_ "TpTxIndex" BO_ 1192 20;
BA_ "GenMsgSendType" BO_ 413 1;
BA_ "FrameRouting" BO_ 556 "MS1_CAN,0x22C;HS3_CAN,0x22C";
BA_ "GenMsgSendType" BO_ 259 1;
BA_ "GenMsgCycleTime" BO_ 538 1000;
BA_ "GenMsgSendType" BO_ 538 5;
BA_ "NetworkInitialization" BO_ 422 0;
BA_ "GenMsgCycleTime" BO_ 422 1000;
BA_ "GenMsgSendType" BO_ 422 5;
BA_ "GenMsgCycleTime" BO_ 1020 1000;
BA_ "GenMsgSendType" BO_ 1020 5;
BA_ "GenMsgCycleTime" BO_ 1007 1000;
BA_ "GenMsgSendType" BO_ 1007 5;
BA_ "U_U55X_MY2022_Rx" SG_ 1001 AirSuspMsgTxt_D_Rq2 1;
BA_ "U_T6_MCA_MY2020_Rx" SG_ 1001 AirSuspMsgTxt_D_Rq2 1;
BA_ "U_P702_MY2021_Rx" SG_ 1001 AirSuspMsgTxt_D_Rq2 1;
BA_ "U_CD542_MY2021_Rx" SG_ 1001 AirSuspMsgTxt_D_Rq2 1;
BA_ "U_U55X_MY2022_Rx" SG_ 1001 PersIndexSuma_D_Actl 1;
BA_ "U_P702_MY2021_Rx" SG_ 1001 PersIndexSuma_D_Actl 1;
BA_ "U_CD542_MY2021_Rx" SG_ 1001 PersIndexSuma_D_Actl 1;
BA_ "U_T6_MCA_MY2020_Rx" SG_ 1001 PersIndexSuma_D_Actl 1;
BA_ "GenSigStartValue" SG_ 1001 PersIndexSuma_D_Actl 4;
BA_ "GenSigStartValueInteger" SG_ 1001 PersIndexSuma_D_Actl 4;
BA_ "U_U55X_MY2022_Rx" SG_ 1001 FeatNoSumaActl 1;
BA_ "U_T6_MCA_MY2020_Rx" SG_ 1001 FeatNoSumaActl 1;
BA_ "U_P702_MY2021_Rx" SG_ 1001 FeatNoSumaActl 1;
BA_ "U_CD542_MY2021_Rx" SG_ 1001 FeatNoSumaActl 1;
BA_ "U_U55X_MY2022_Rx" SG_ 1001 FeatConfigSumaActl 1;
BA_ "U_P702_MY2021_Rx" SG_ 1001 FeatConfigSumaActl 1;
BA_ "U_CD542_MY2021_Rx" SG_ 1001 FeatConfigSumaActl 1;
BA_ "U_T6_MCA_MY2020_Rx" SG_ 1001 FeatConfigSumaActl 1;
BA_ "U_U55X_MY2022_Tx" SG_ 1916 TesterPhysicalResRACM 1;
BA_ "GenSigSendType" SG_ 1916 TesterPhysicalResRACM 3;
BA_ "U_U55X_MY2022_Rx" SG_ 1908 TesterPhysicalReqRACM 1;
BA_ "GenSigSendType" SG_ 1908 TesterPhysicalReqRACM 3;
BA_ "U_U55X_MY2022_Tx" SG_ 1432 RACM_GWOnBoardTester 1;
BA_ "U_U55X_MY2022_Rx" SG_ 1432 RACM_GWOnBoardTester 1;
BA_ "GenSigStartValue" SG_ 1432 RACM_GWOnBoardTester 255;
BA_ "ContentDependant" SG_ 1432 RACM_GWOnBoardTester 1;
BA_ "GenSigStartValueInteger" SG_ 1432 RACM_GWOnBoardTester 255;
BA_ "U_U55X_MY2022_Tx" SG_ 1432 RACM_GWNMProxy 1;
BA_ "U_U55X_MY2022_Rx" SG_ 1432 RACM_GWNMProxy 1;
BA_ "GenSigStartValue" SG_ 1432 RACM_GWNMProxy 255;
BA_ "ContentDependant" SG_ 1432 RACM_GWNMProxy 1;
BA_ "GenSigStartValueInteger" SG_ 1432 RACM_GWNMProxy 255;
BA_ "U_U55X_MY2022_Tx" SG_ 1432 RACM_AutoSarNMReserved4 1;
BA_ "U_U55X_MY2022_Rx" SG_ 1432 RACM_AutoSarNMReserved4 1;
BA_ "GenSigStartValue" SG_ 1432 RACM_AutoSarNMReserved4 255;
BA_ "ContentDependant" SG_ 1432 RACM_AutoSarNMReserved4 1;
BA_ "GenSigStartValueInteger" SG_ 1432 RACM_AutoSarNMReserved4 255;
BA_ "U_U55X_MY2022_Tx" SG_ 1432 RACM_AutoSarNMReserved3 1;
BA_ "U_U55X_MY2022_Rx" SG_ 1432 RACM_AutoSarNMReserved3 1;
BA_ "GenSigStartValue" SG_ 1432 RACM_AutoSarNMReserved3 255;
BA_ "ContentDependant" SG_ 1432 RACM_AutoSarNMReserved3 1;
BA_ "GenSigStartValueInteger" SG_ 1432 RACM_AutoSarNMReserved3 255;
BA_ "U_U55X_MY2022_Tx" SG_ 1432 RACM_AutoSarNMReserved2 1;
BA_ "U_U55X_MY2022_Rx" SG_ 1432 RACM_AutoSarNMReserved2 1;
BA_ "GenSigStartValue" SG_ 1432 RACM_AutoSarNMReserved2 255;
BA_ "ContentDependant" SG_ 1432 RACM_AutoSarNMReserved2 1;
BA_ "GenSigStartValueInteger" SG_ 1432 RACM_AutoSarNMReserved2 255;
BA_ "U_U55X_MY2022_Tx" SG_ 1432 RACM_AutoSarNMReserved1 1;
BA_ "U_U55X_MY2022_Rx" SG_ 1432 RACM_AutoSarNMReserved1 1;
BA_ "GenSigStartValue" SG_ 1432 RACM_AutoSarNMReserved1 255;
BA_ "ContentDependant" SG_ 1432 RACM_AutoSarNMReserved1 1;
BA_ "GenSigStartValueInteger" SG_ 1432 RACM_AutoSarNMReserved1 255;
BA_ "U_U55X_MY2022_Tx" SG_ 1432 RACM_AutoSarNMNodeId 1;
BA_ "U_U55X_MY2022_Rx" SG_ 1432 RACM_AutoSarNMNodeId 1;
BA_ "GenSigStartValue" SG_ 1432 RACM_AutoSarNMNodeId 152;
BA_ "ContentDependant" SG_ 1432 RACM_AutoSarNMNodeId 1;
BA_ "GenSigStartValueInteger" SG_ 1432 RACM_AutoSarNMNodeId 150;
BA_ "U_U55X_MY2022_Tx" SG_ 1432 RACM_AutoSarNMControl 1;
BA_ "U_U55X_MY2022_Rx" SG_ 1432 RACM_AutoSarNMControl 1;
BA_ "ContentDependant" SG_ 1432 RACM_AutoSarNMControl 1;
BA_ "U_U55X_MY2022_Rx" SG_ 1923 TesterPhysicalReqDSP 1;
BA_ "U_CD542_MY2021_Rx" SG_ 1923 TesterPhysicalReqDSP 1;
BA_ "U_T6_MCA_MY2020_Rx" SG_ 1923 TesterPhysicalReqDSP 1;
BA_ "U_P702_MY2021_Rx" SG_ 1923 TesterPhysicalReqDSP 1;
BA_ "GenSigSendType" SG_ 1923 TesterPhysicalReqDSP 3;
BA_ "U_U55X_MY2022_Tx" SG_ 1931 TesterPhysicalResDSP 1;
BA_ "U_CD542_MY2021_Tx" SG_ 1931 TesterPhysicalResDSP 1;
BA_ "U_T6_MCA_MY2020_Tx" SG_ 1931 TesterPhysicalResDSP 1;
BA_ "GenSigSendType" SG_ 1931 TesterPhysicalResDSP 3;
BA_ "U_U55X_MY2022_Tx" SG_ 1478 DSP_GWOnBoardTester 1;
BA_ "U_CD542_MY2021_Tx" SG_ 1478 DSP_GWOnBoardTester 1;
BA_ "U_T6_MCA_MY2020_Tx" SG_ 1478 DSP_GWOnBoardTester 1;
BA_ "U_U55X_MY2022_Rx" SG_ 1478 DSP_GWOnBoardTester 1;
BA_ "U_T6_MCA_MY2020_Rx" SG_ 1478 DSP_GWOnBoardTester 1;
BA_ "GenSigStartValue" SG_ 1478 DSP_GWOnBoardTester 255;
BA_ "ContentDependant" SG_ 1478 DSP_GWOnBoardTester 1;
BA_ "GenSigStartValueInteger" SG_ 1478 DSP_GWOnBoardTester 255;
BA_ "U_U55X_MY2022_Tx" SG_ 1478 DSP_GWNMProxy 1;
BA_ "U_CD542_MY2021_Tx" SG_ 1478 DSP_GWNMProxy 1;
BA_ "U_T6_MCA_MY2020_Tx" SG_ 1478 DSP_GWNMProxy 1;
BA_ "U_U55X_MY2022_Rx" SG_ 1478 DSP_GWNMProxy 1;
BA_ "U_T6_MCA_MY2020_Rx" SG_ 1478 DSP_GWNMProxy 1;
BA_ "GenSigStartValue" SG_ 1478 DSP_GWNMProxy 255;
BA_ "ContentDependant" SG_ 1478 DSP_GWNMProxy 1;
BA_ "GenSigStartValueInteger" SG_ 1478 DSP_GWNMProxy 255;
BA_ "U_U55X_MY2022_Tx" SG_ 1478 DSP_AutoSarNMReserved4 1;
BA_ "U_CD542_MY2021_Tx" SG_ 1478 DSP_AutoSarNMReserved4 1;
BA_ "U_T6_MCA_MY2020_Tx" SG_ 1478 DSP_AutoSarNMReserved4 1;
BA_ "U_U55X_MY2022_Rx" SG_ 1478 DSP_AutoSarNMReserved4 1;
BA_ "U_T6_MCA_MY2020_Rx" SG_ 1478 DSP_AutoSarNMReserved4 1;
BA_ "GenSigStartValue" SG_ 1478 DSP_AutoSarNMReserved4 255;
BA_ "ContentDependant" SG_ 1478 DSP_AutoSarNMReserved4 1;
BA_ "GenSigStartValueInteger" SG_ 1478 DSP_AutoSarNMReserved4 255;
BA_ "U_U55X_MY2022_Tx" SG_ 1478 DSP_AutoSarNMReserved3 1;
BA_ "U_CD542_MY2021_Tx" SG_ 1478 DSP_AutoSarNMReserved3 1;
BA_ "U_T6_MCA_MY2020_Tx" SG_ 1478 DSP_AutoSarNMReserved3 1;
BA_ "U_U55X_MY2022_Rx" SG_ 1478 DSP_AutoSarNMReserved3 1;
BA_ "U_T6_MCA_MY2020_Rx" SG_ 1478 DSP_AutoSarNMReserved3 1;
BA_ "GenSigStartValue" SG_ 1478 DSP_AutoSarNMReserved3 255;
BA_ "ContentDependant" SG_ 1478 DSP_AutoSarNMReserved3 1;
BA_ "GenSigStartValueInteger" SG_ 1478 DSP_AutoSarNMReserved3 255;
BA_ "U_U55X_MY2022_Tx" SG_ 1478 DSP_AutoSarNMReserved2 1;
BA_ "U_CD542_MY2021_Tx" SG_ 1478 DSP_AutoSarNMReserved2 1;
BA_ "U_T6_MCA_MY2020_Tx" SG_ 1478 DSP_AutoSarNMReserved2 1;
BA_ "U_U55X_MY2022_Rx" SG_ 1478 DSP_AutoSarNMReserved2 1;
BA_ "U_T6_MCA_MY2020_Rx" SG_ 1478 DSP_AutoSarNMReserved2 1;
BA_ "GenSigStartValue" SG_ 1478 DSP_AutoSarNMReserved2 255;
BA_ "ContentDependant" SG_ 1478 DSP_AutoSarNMReserved2 1;
BA_ "GenSigStartValueInteger" SG_ 1478 DSP_AutoSarNMReserved2 255;
BA_ "U_U55X_MY2022_Tx" SG_ 1478 DSP_AutoSarNMReserved1 1;
BA_ "U_CD542_MY2021_Tx" SG_ 1478 DSP_AutoSarNMReserved1 1;
BA_ "U_T6_MCA_MY2020_Tx" SG_ 1478 DSP_AutoSarNMReserved1 1;
BA_ "U_U55X_MY2022_Rx" SG_ 1478 DSP_AutoSarNMReserved1 1;
BA_ "U_T6_MCA_MY2020_Rx" SG_ 1478 DSP_AutoSarNMReserved1 1;
BA_ "GenSigStartValue" SG_ 1478 DSP_AutoSarNMReserved1 255;
BA_ "ContentDependant" SG_ 1478 DSP_AutoSarNMReserved1 1;
BA_ "GenSigStartValueInteger" SG_ 1478 DSP_AutoSarNMReserved1 255;
BA_ "U_U55X_MY2022_Tx" SG_ 1478 DSP_AutoSarNMNodeId 1;
BA_ "U_CD542_MY2021_Tx" SG_ 1478 DSP_AutoSarNMNodeId 1;
BA_ "U_T6_MCA_MY2020_Tx" SG_ 1478 DSP_AutoSarNMNodeId 1;
BA_ "U_U55X_MY2022_Rx" SG_ 1478 DSP_AutoSarNMNodeId 1;
BA_ "U_T6_MCA_MY2020_Rx" SG_ 1478 DSP_AutoSarNMNodeId 1;
BA_ "GenSigStartValue" SG_ 1478 DSP_AutoSarNMNodeId 198;
BA_ "ContentDependant" SG_ 1478 DSP_AutoSarNMNodeId 1;
BA_ "GenSigStartValueInteger" SG_ 1478 DSP_AutoSarNMNodeId 198;
BA_ "U_U55X_MY2022_Tx" SG_ 1478 DSP_AutoSarNMControl 1;
BA_ "U_CD542_MY2021_Tx" SG_ 1478 DSP_AutoSarNMControl 1;
BA_ "U_T6_MCA_MY2020_Tx" SG_ 1478 DSP_AutoSarNMControl 1;
BA_ "U_U55X_MY2022_Rx" SG_ 1478 DSP_AutoSarNMControl 1;
BA_ "U_T6_MCA_MY2020_Rx" SG_ 1478 DSP_AutoSarNMControl 1;
BA_ "ContentDependant" SG_ 1478 DSP_AutoSarNMControl 1;
BA_ "ECGUsedTxSignal" SG_ 1245 RearDiffLckLamp_D_Cstm 1;
BA_ "GenSigSendType" SG_ 1245 RearDiffLckLamp_D_Cstm 3;
BA_ "ECGUsedTxSignal" SG_ 1245 FrontDiffLckLamp_D_Cstm 1;
BA_ "GenSigSendType" SG_ 1245 FrontDiffLckLamp_D_Cstm 3;
BA_ "ECGUsedTxSignal" SG_ 1245 AwdMdeCstm_D_RqDrv 1;
BA_ "GenSigSendType" SG_ 1245 AwdMdeCstm_D_RqDrv 3;
BA_ "GenSigStartValueInteger" SG_ 1245 AwdMdeCstm_D_RqDrv 5;
BA_ "ECGUsedTxSignal" SG_ 1245 SelDrvMdeAwd2_D_Cstm 1;
BA_ "GenSigSendType" SG_ 1245 SelDrvMdeAwd2_D_Cstm 3;
BA_ "GenSigStartValue" SG_ 1245 SelDrvMdeAwd2_D_Cstm 31;
BA_ "GenSigStartValueInteger" SG_ 1245 SelDrvMdeAwd2_D_Cstm 31;
BA_ "ECGUsedTxSignal" SG_ 1242 EngExhMdeQuietCstm_D_Rq 1;
BA_ "GenSigSendType" SG_ 1242 EngExhMdeQuietCstm_D_Rq 3;
BA_ "ECGUsedTxSignal" SG_ 1242 StopStrtCstm_D_Rq 1;
BA_ "GenSigSendType" SG_ 1242 StopStrtCstm_D_Rq 3;
BA_ "ECGUsedTxSignal" SG_ 1242 SelDrvMdeCstmPt_D_Rq 1;
BA_ "GenSigSendType" SG_ 1242 SelDrvMdeCstmPt_D_Rq 3;
BA_ "GenSigStartValue" SG_ 1022 TrlrTireIRR_T_Actl 253;
BA_ "GenSigStartValue" SG_ 1022 TrlrTireIRM_T_Actl 253;
BA_ "GenSigStartValue" SG_ 1022 TrlrTireILR_T_Actl 253;
BA_ "GenSigStartValue" SG_ 1022 TrlrTireILM_T_Actl 253;
BA_ "GenSigStartValue" SG_ 1022 TrlrTireILF_T_Actl 253;
BA_ "GenSigStartValue" SG_ 1022 TrlrTireIRF_T_Actl 253;
BA_ "GenSigStartValue" SG_ 1021 TrlrTireIRR_P_Actl 65533;
BA_ "GenSigStartValueInteger" SG_ 1021 TrlrTireIRR_P_Actl 65533;
BA_ "GenSigStartValue" SG_ 1021 TrlrTireIRM_P_Actl 65533;
BA_ "GenSigStartValueInteger" SG_ 1021 TrlrTireIRM_P_Actl 65533;
BA_ "GenSigStartValue" SG_ 1021 TrlrTireIRF_P_Actl 65533;
BA_ "GenSigStartValueInteger" SG_ 1021 TrlrTireIRF_P_Actl 65533;
BA_ "GenSigStartValue" SG_ 1018 TrlrTireILR_P_Actl 65533;
BA_ "GenSigStartValueInteger" SG_ 1018 TrlrTireILR_P_Actl 65533;
BA_ "GenSigStartValue" SG_ 1018 TrlrTireILM_P_Actl 65533;
BA_ "GenSigStartValueInteger" SG_ 1018 TrlrTireILM_P_Actl 65533;
BA_ "GenSigStartValue" SG_ 1018 TrlrTireILF_P_Actl 65533;
BA_ "GenSigStartValueInteger" SG_ 1018 TrlrTireILF_P_Actl 65533;
BA_ "U_U55X_MY2022_Tx" SG_ 502 Dsp_StartItemIndexRq 1;
BA_ "U_CD542_MY2021_Tx" SG_ 502 Dsp_StartItemIndexRq 1;
BA_ "U_T6_MCA_MY2020_Tx" SG_ 502 Dsp_StartItemIndexRq 1;
BA_ "U_P702_MY2021_Tx" SG_ 502 Dsp_StartItemIndexRq 1;
BA_ "U_U55X_MY2022_Rx" SG_ 502 Dsp_StartItemIndexRq 1;
BA_ "U_CD542_MY2021_Rx" SG_ 502 Dsp_StartItemIndexRq 1;
BA_ "U_T6_MCA_MY2020_Rx" SG_ 502 Dsp_StartItemIndexRq 1;
BA_ "U_P702_MY2021_Rx" SG_ 502 Dsp_StartItemIndexRq 1;
BA_ "U_U55X_MY2022_Tx" SG_ 502 Dsp_NbrOfItems2_Rq 1;
BA_ "U_CD542_MY2021_Tx" SG_ 502 Dsp_NbrOfItems2_Rq 1;
BA_ "U_T6_MCA_MY2020_Tx" SG_ 502 Dsp_NbrOfItems2_Rq 1;
BA_ "U_P702_MY2021_Tx" SG_ 502 Dsp_NbrOfItems2_Rq 1;
BA_ "U_U55X_MY2022_Rx" SG_ 502 Dsp_NbrOfItems2_Rq 1;
BA_ "U_CD542_MY2021_Rx" SG_ 502 Dsp_NbrOfItems2_Rq 1;
BA_ "U_T6_MCA_MY2020_Rx" SG_ 502 Dsp_NbrOfItems2_Rq 1;
BA_ "U_P702_MY2021_Rx" SG_ 502 Dsp_NbrOfItems2_Rq 1;
BA_ "U_U55X_MY2022_Tx" SG_ 502 Dsp_ItemNameLength2_Rq 1;
BA_ "U_CD542_MY2021_Tx" SG_ 502 Dsp_ItemNameLength2_Rq 1;
BA_ "U_T6_MCA_MY2020_Tx" SG_ 502 Dsp_ItemNameLength2_Rq 1;
BA_ "U_P702_MY2021_Tx" SG_ 502 Dsp_ItemNameLength2_Rq 1;
BA_ "U_U55X_MY2022_Rx" SG_ 502 Dsp_ItemNameLength2_Rq 1;
BA_ "U_CD542_MY2021_Rx" SG_ 502 Dsp_ItemNameLength2_Rq 1;
BA_ "U_T6_MCA_MY2020_Rx" SG_ 502 Dsp_ItemNameLength2_Rq 1;
BA_ "U_P702_MY2021_Rx" SG_ 502 Dsp_ItemNameLength2_Rq 1;
BA_ "U_U55X_MY2022_Tx" SG_ 502 Dsp_FolderNumber2_Rq 1;
BA_ "U_CD542_MY2021_Tx" SG_ 502 Dsp_FolderNumber2_Rq 1;
BA_ "U_T6_MCA_MY2020_Tx" SG_ 502 Dsp_FolderNumber2_Rq 1;
BA_ "U_P702_MY2021_Tx" SG_ 502 Dsp_FolderNumber2_Rq 1;
BA_ "U_U55X_MY2022_Rx" SG_ 502 Dsp_FolderNumber2_Rq 1;
BA_ "U_CD542_MY2021_Rx" SG_ 502 Dsp_FolderNumber2_Rq 1;
BA_ "U_T6_MCA_MY2020_Rx" SG_ 502 Dsp_FolderNumber2_Rq 1;
BA_ "U_P702_MY2021_Rx" SG_ 502 Dsp_FolderNumber2_Rq 1;
BA_ "U_U55X_MY2022_Tx" SG_ 502 Dsp_FolderContent_Rq 1;
BA_ "U_CD542_MY2021_Tx" SG_ 502 Dsp_FolderContent_Rq 1;
BA_ "U_T6_MCA_MY2020_Tx" SG_ 502 Dsp_FolderContent_Rq 1;
BA_ "U_P702_MY2021_Tx" SG_ 502 Dsp_FolderContent_Rq 1;
BA_ "U_U55X_MY2022_Rx" SG_ 502 Dsp_FolderContent_Rq 1;
BA_ "U_CD542_MY2021_Rx" SG_ 502 Dsp_FolderContent_Rq 1;
BA_ "U_T6_MCA_MY2020_Rx" SG_ 502 Dsp_FolderContent_Rq 1;
BA_ "U_P702_MY2021_Rx" SG_ 502 Dsp_FolderContent_Rq 1;
BA_ "U_U55X_MY2022_Tx" SG_ 502 Dsp_CutItem2_Rq 1;
BA_ "U_CD542_MY2021_Tx" SG_ 502 Dsp_CutItem2_Rq 1;
BA_ "U_T6_MCA_MY2020_Tx" SG_ 502 Dsp_CutItem2_Rq 1;
BA_ "U_P702_MY2021_Tx" SG_ 502 Dsp_CutItem2_Rq 1;
BA_ "U_U55X_MY2022_Rx" SG_ 502 Dsp_CutItem2_Rq 1;
BA_ "U_CD542_MY2021_Rx" SG_ 502 Dsp_CutItem2_Rq 1;
BA_ "U_T6_MCA_MY2020_Rx" SG_ 502 Dsp_CutItem2_Rq 1;
BA_ "U_P702_MY2021_Rx" SG_ 502 Dsp_CutItem2_Rq 1;
BA_ "U_U55X_MY2022_Tx" SG_ 502 Dsp_AudioSourceSel2_Rq 1;
BA_ "U_CD542_MY2021_Tx" SG_ 502 Dsp_AudioSourceSel2_Rq 1;
BA_ "U_T6_MCA_MY2020_Tx" SG_ 502 Dsp_AudioSourceSel2_Rq 1;
BA_ "U_P702_MY2021_Tx" SG_ 502 Dsp_AudioSourceSel2_Rq 1;
BA_ "U_U55X_MY2022_Rx" SG_ 502 Dsp_AudioSourceSel2_Rq 1;
BA_ "U_CD542_MY2021_Rx" SG_ 502 Dsp_AudioSourceSel2_Rq 1;
BA_ "U_T6_MCA_MY2020_Rx" SG_ 502 Dsp_AudioSourceSel2_Rq 1;
BA_ "U_P702_MY2021_Rx" SG_ 502 Dsp_AudioSourceSel2_Rq 1;
BA_ "GenSigSendType" SG_ 502 Dsp_AudioSourceSel2_Rq 3;
BA_ "U_CD542_MY2021_Rx" SG_ 955 Tire_Temp_RF_Data 1;
BA_ "U_U55X_MY2022_Rx" SG_ 955 Tire_Temp_RF_Data 1;
BA_ "U_T6_MCA_MY2020_Rx" SG_ 955 Tire_Temp_RF_Data 1;
BA_ "GenSigStartValue" SG_ 955 Tire_Temp_RF_Data 253;
BA_ "GenSigStartValueInteger" SG_ 955 Tire_Temp_RF_Data 253;
BA_ "U_CD542_MY2021_Rx" SG_ 955 Tire_Temp_ORR_Data 1;
BA_ "U_U55X_MY2022_Rx" SG_ 955 Tire_Temp_ORR_Data 1;
BA_ "U_T6_MCA_MY2020_Rx" SG_ 955 Tire_Temp_ORR_Data 1;
BA_ "GenSigStartValue" SG_ 955 Tire_Temp_ORR_Data 253;
BA_ "GenSigStartValueInteger" SG_ 955 Tire_Temp_ORR_Data 253;
BA_ "U_CD542_MY2021_Rx" SG_ 955 Tire_Temp_OLR_Data 1;
BA_ "U_U55X_MY2022_Rx" SG_ 955 Tire_Temp_OLR_Data 1;
BA_ "U_T6_MCA_MY2020_Rx" SG_ 955 Tire_Temp_OLR_Data 1;
BA_ "GenSigStartValue" SG_ 955 Tire_Temp_OLR_Data 253;
BA_ "GenSigStartValueInteger" SG_ 955 Tire_Temp_OLR_Data 253;
BA_ "U_CD542_MY2021_Rx" SG_ 955 Tire_Temp_LF_Data 1;
BA_ "U_U55X_MY2022_Rx" SG_ 955 Tire_Temp_LF_Data 1;
BA_ "U_T6_MCA_MY2020_Rx" SG_ 955 Tire_Temp_LF_Data 1;
BA_ "GenSigStartValue" SG_ 955 Tire_Temp_LF_Data 253;
BA_ "GenSigStartValueInteger" SG_ 955 Tire_Temp_LF_Data 253;
BA_ "U_CD542_MY2021_Rx" SG_ 955 Tire_Temp_IRR_Data 1;
BA_ "U_U55X_MY2022_Rx" SG_ 955 Tire_Temp_IRR_Data 1;
BA_ "U_T6_MCA_MY2020_Rx" SG_ 955 Tire_Temp_IRR_Data 1;
BA_ "GenSigStartValue" SG_ 955 Tire_Temp_IRR_Data 253;
BA_ "GenSigStartValueInteger" SG_ 955 Tire_Temp_IRR_Data 253;
BA_ "U_CD542_MY2021_Rx" SG_ 955 Tire_Temp_ILR_Data 1;
BA_ "U_U55X_MY2022_Rx" SG_ 955 Tire_Temp_ILR_Data 1;
BA_ "U_T6_MCA_MY2020_Rx" SG_ 955 Tire_Temp_ILR_Data 1;
BA_ "GenSigStartValue" SG_ 955 Tire_Temp_ILR_Data 253;
BA_ "GenSigStartValueInteger" SG_ 955 Tire_Temp_ILR_Data 253;
BA_ "U_U55X_MY2022_Tx" SG_ 1116 TrlrAidSetup_D2_Rq 1;
BA_ "U_CD542_MY2021_Tx" SG_ 1116 TrlrAidSetup_D2_Rq 1;
BA_ "U_T6_MCA_MY2020_Tx" SG_ 1116 TrlrAidSetup_D2_Rq 1;
BA_ "GenSigSendType" SG_ 1116 TrlrAidSetup_D2_Rq 3;
BA_ "U_U55X_MY2022_Tx" SG_ 1116 TrlrAidEnbl_D2_Rq 1;
BA_ "U_CD542_MY2021_Tx" SG_ 1116 TrlrAidEnbl_D2_Rq 1;
BA_ "U_T6_MCA_MY2020_Tx" SG_ 1116 TrlrAidEnbl_D2_Rq 1;
BA_ "GenSigSendType" SG_ 1116 TrlrAidEnbl_D2_Rq 3;
BA_ "U_U55X_MY2022_Tx" SG_ 1116 TlightTest_D_Mnu 1;
BA_ "U_CD542_MY2021_Tx" SG_ 1116 TlightTest_D_Mnu 1;
BA_ "U_T6_MCA_MY2020_Tx" SG_ 1116 TlightTest_D_Mnu 1;
BA_ "U_U55X_MY2022_Rx" SG_ 1116 TlightTest_D_Mnu 1;
BA_ "U_CD542_MY2021_Rx" SG_ 1116 TlightTest_D_Mnu 1;
BA_ "ECGUsedRxSignal" SG_ 1116 TlightTest_D_Mnu 1;
BA_ "GenSigSendType" SG_ 1116 TlightTest_D_Mnu 3;
BA_ "U_U55X_MY2022_Tx" SG_ 1116 TrlrTrgtToBmpr_L_Actl 1;
BA_ "U_CD542_MY2021_Tx" SG_ 1116 TrlrTrgtToBmpr_L_Actl 1;
BA_ "U_T6_MCA_MY2020_Tx" SG_ 1116 TrlrTrgtToBmpr_L_Actl 1;
BA_ "U_U55X_MY2022_Tx" SG_ 1116 TrlrTrgtPtrnId_No_Mem 1;
BA_ "U_CD542_MY2021_Tx" SG_ 1116 TrlrTrgtPtrnId_No_Mem 1;
BA_ "U_T6_MCA_MY2020_Tx" SG_ 1116 TrlrTrgtPtrnId_No_Mem 1;
BA_ "U_U55X_MY2022_Tx" SG_ 1116 TrlrRvrseCancl_B_Rq 1;
BA_ "U_CD542_MY2021_Tx" SG_ 1116 TrlrRvrseCancl_B_Rq 1;
BA_ "U_T6_MCA_MY2020_Tx" SG_ 1116 TrlrRvrseCancl_B_Rq 1;
BA_ "GenSigSendType" SG_ 1116 TrlrRvrseCancl_B_Rq 3;
BA_ "U_U55X_MY2022_Tx" SG_ 1116 TrlrIdType_D_Stat 1;
BA_ "U_CD542_MY2021_Tx" SG_ 1116 TrlrIdType_D_Stat 1;
BA_ "U_T6_MCA_MY2020_Tx" SG_ 1116 TrlrIdType_D_Stat 1;
BA_ "GenSigSendType" SG_ 1116 TrlrIdType_D_Stat 3;
BA_ "U_U55X_MY2022_Tx" SG_ 1116 TrlrId_No_Actl 1;
BA_ "U_CD542_MY2021_Tx" SG_ 1116 TrlrId_No_Actl 1;
BA_ "U_T6_MCA_MY2020_Tx" SG_ 1116 TrlrId_No_Actl 1;
BA_ "U_U55X_MY2022_Tx" SG_ 1116 TrlrBallToBmpr_L_Actl 1;
BA_ "U_CD542_MY2021_Tx" SG_ 1116 TrlrBallToBmpr_L_Actl 1;
BA_ "U_T6_MCA_MY2020_Tx" SG_ 1116 TrlrBallToBmpr_L_Actl 1;
BA_ "U_U55X_MY2022_Tx" SG_ 1116 TrlrAxleToBmpr_L_Actl 1;
BA_ "U_CD542_MY2021_Tx" SG_ 1116 TrlrAxleToBmpr_L_Actl 1;
BA_ "U_T6_MCA_MY2020_Tx" SG_ 1116 TrlrAxleToBmpr_L_Actl 1;
BA_ "U_U55X_MY2022_Tx" SG_ 1116 TrlrAnOffstDir_D_Mem 1;
BA_ "U_CD542_MY2021_Tx" SG_ 1116 TrlrAnOffstDir_D_Mem 1;
BA_ "U_T6_MCA_MY2020_Tx" SG_ 1116 TrlrAnOffstDir_D_Mem 1;
BA_ "GenSigSendType" SG_ 1116 TrlrAnOffstDir_D_Mem 3;
BA_ "U_U55X_MY2022_Tx" SG_ 1116 TrlrAnOffst_An_Mem 1;
BA_ "U_CD542_MY2021_Tx" SG_ 1116 TrlrAnOffst_An_Mem 1;
BA_ "U_T6_MCA_MY2020_Tx" SG_ 1116 TrlrAnOffst_An_Mem 1;
BA_ "U_U55X_MY2022_Tx" SG_ 1116 TrlrTrgtOffst_L_Actl 1;
BA_ "U_CD542_MY2021_Tx" SG_ 1116 TrlrTrgtOffst_L_Actl 1;
BA_ "U_T6_MCA_MY2020_Tx" SG_ 1116 TrlrTrgtOffst_L_Actl 1;
BA_ "U_CD542_MY2021_Rx" SG_ 1113 TrlrAnOffstDir_D_Calc_UB 1;
BA_ "U_P702_MY2021_Rx" SG_ 1113 TrlrAnOffstDir_D_Calc_UB 1;
BA_ "U_U55X_MY2022_Rx" SG_ 1113 TrlrAnOffstDir_D_Calc_UB 1;
BA_ "U_T6_MCA_MY2020_Rx" SG_ 1113 TrlrAnOffstDir_D_Calc_UB 1;
BA_ "U_CD542_MY2021_Rx" SG_ 1113 TrlrAnOffst_An_Calc_UB 1;
BA_ "U_P702_MY2021_Rx" SG_ 1113 TrlrAnOffst_An_Calc_UB 1;
BA_ "U_U55X_MY2022_Rx" SG_ 1113 TrlrAnOffst_An_Calc_UB 1;
BA_ "U_T6_MCA_MY2020_Rx" SG_ 1113 TrlrAnOffst_An_Calc_UB 1;
BA_ "U_CD542_MY2021_Rx" SG_ 1113 TrlrAnCalib_B_Complt_UB 1;
BA_ "U_U55X_MY2022_Rx" SG_ 1113 TrlrAnCalib_B_Complt_UB 1;
BA_ "U_T6_MCA_MY2020_Rx" SG_ 1113 TrlrAnCalib_B_Complt_UB 1;
BA_ "U_CD542_MY2021_Rx" SG_ 1113 TrlrAidTrgtId_No_Actl_UB 1;
BA_ "U_U55X_MY2022_Rx" SG_ 1113 TrlrAidTrgtId_No_Actl_UB 1;
BA_ "U_T6_MCA_MY2020_Rx" SG_ 1113 TrlrAidTrgtId_No_Actl_UB 1;
BA_ "U_CD542_MY2021_Rx" SG_ 1113 TrlrAnOffst_An_Calc 1;
BA_ "U_P702_MY2021_Rx" SG_ 1113 TrlrAnOffst_An_Calc 1;
BA_ "U_U55X_MY2022_Rx" SG_ 1113 TrlrAnOffst_An_Calc 1;
BA_ "U_T6_MCA_MY2020_Rx" SG_ 1113 TrlrAnOffst_An_Calc 1;
BA_ "U_CD542_MY2021_Rx" SG_ 1113 TrlrAnCalib_B_Complt 1;
BA_ "U_U55X_MY2022_Rx" SG_ 1113 TrlrAnCalib_B_Complt 1;
BA_ "U_T6_MCA_MY2020_Rx" SG_ 1113 TrlrAnCalib_B_Complt 1;
BA_ "U_CD542_MY2021_Rx" SG_ 1113 TrlrAnOffstDir_D_Calc 1;
BA_ "U_P702_MY2021_Rx" SG_ 1113 TrlrAnOffstDir_D_Calc 1;
BA_ "U_U55X_MY2022_Rx" SG_ 1113 TrlrAnOffstDir_D_Calc 1;
BA_ "U_T6_MCA_MY2020_Rx" SG_ 1113 TrlrAnOffstDir_D_Calc 1;
BA_ "U_CD542_MY2021_Rx" SG_ 1113 TrlrAidTrgtId_No_Actl 1;
BA_ "U_U55X_MY2022_Rx" SG_ 1113 TrlrAidTrgtId_No_Actl 1;
BA_ "U_T6_MCA_MY2020_Rx" SG_ 1113 TrlrAidTrgtId_No_Actl 1;
BA_ "U_U55X_MY2022_Rx" SG_ 1113 immoSecureIdleMode_UB 1;
BA_ "U_CD542_MY2021_Rx" SG_ 1113 immoSecureIdleMode_UB 1;
BA_ "U_T6_MCA_MY2020_Rx" SG_ 1113 immoSecureIdleMode_UB 1;
BA_ "U_U55X_MY2022_Rx" SG_ 1113 immoSecureIdleMode 1;
BA_ "U_CD542_MY2021_Rx" SG_ 1113 immoSecureIdleMode 1;
BA_ "U_T6_MCA_MY2020_Rx" SG_ 1113 immoSecureIdleMode 1;
BA_ "U_CD542_MY2021_Rx" SG_ 1255 BalrRight4Threat_D_Stat 1;
BA_ "U_T6_MCA_MY2020_Rx" SG_ 1255 BalrRight4Threat_D_Stat 1;
BA_ "U_CD542_MY2021_Rx" SG_ 1255 BalrRight4Prev3Y_L_Actl 1;
BA_ "U_T6_MCA_MY2020_Rx" SG_ 1255 BalrRight4Prev3Y_L_Actl 1;
BA_ "GenSigStartValueInteger" SG_ 1255 BalrRight4Prev3Y_L_Actl 64;
BA_ "U_CD542_MY2021_Rx" SG_ 1255 BalrRight4Prev3X_L_Actl 1;
BA_ "U_T6_MCA_MY2020_Rx" SG_ 1255 BalrRight4Prev3X_L_Actl 1;
BA_ "GenSigStartValueInteger" SG_ 1255 BalrRight4Prev3X_L_Actl 64;
BA_ "U_CD542_MY2021_Rx" SG_ 1255 BalrRight4Prev2Y_L_Actl 1;
BA_ "U_T6_MCA_MY2020_Rx" SG_ 1255 BalrRight4Prev2Y_L_Actl 1;
BA_ "GenSigStartValueInteger" SG_ 1255 BalrRight4Prev2Y_L_Actl 64;
BA_ "U_CD542_MY2021_Rx" SG_ 1255 BalrRight4Prev2X_L_Actl 1;
BA_ "U_T6_MCA_MY2020_Rx" SG_ 1255 BalrRight4Prev2X_L_Actl 1;
BA_ "GenSigStartValueInteger" SG_ 1255 BalrRight4Prev2X_L_Actl 64;
BA_ "U_CD542_MY2021_Rx" SG_ 1255 BalrRight4Prev1Y_L_Actl 1;
BA_ "U_T6_MCA_MY2020_Rx" SG_ 1255 BalrRight4Prev1Y_L_Actl 1;
BA_ "GenSigStartValueInteger" SG_ 1255 BalrRight4Prev1Y_L_Actl 64;
BA_ "U_CD542_MY2021_Rx" SG_ 1255 BalrRight4Prev1X_L_Actl 1;
BA_ "U_T6_MCA_MY2020_Rx" SG_ 1255 BalrRight4Prev1X_L_Actl 1;
BA_ "GenSigStartValueInteger" SG_ 1255 BalrRight4Prev1X_L_Actl 64;
BA_ "U_CD542_MY2021_Rx" SG_ 1255 BalrRight4Fast_B_Stat 1;
BA_ "U_T6_MCA_MY2020_Rx" SG_ 1255 BalrRight4Fast_B_Stat 1;
BA_ "U_CD542_MY2021_Rx" SG_ 1255 BalrRight4Dsply_B_Stat 1;
BA_ "U_T6_MCA_MY2020_Rx" SG_ 1255 BalrRight4Dsply_B_Stat 1;
BA_ "U_CD542_MY2021_Rx" SG_ 1255 BalrRight4CurntY_L_Actl 1;
BA_ "U_T6_MCA_MY2020_Rx" SG_ 1255 BalrRight4CurntY_L_Actl 1;
BA_ "GenSigStartValueInteger" SG_ 1255 BalrRight4CurntY_L_Actl 64;
BA_ "U_CD542_MY2021_Rx" SG_ 1255 BalrRight4CurntX_L_Actl 1;
BA_ "U_T6_MCA_MY2020_Rx" SG_ 1255 BalrRight4CurntX_L_Actl 1;
BA_ "GenSigStartValueInteger" SG_ 1255 BalrRight4CurntX_L_Actl 64;
BA_ "U_CD542_MY2021_Rx" SG_ 1254 BalrRight3Threat_D_Stat 1;
BA_ "U_T6_MCA_MY2020_Rx" SG_ 1254 BalrRight3Threat_D_Stat 1;
BA_ "U_CD542_MY2021_Rx" SG_ 1254 BalrRight3Prev3Y_L_Actl 1;
BA_ "U_T6_MCA_MY2020_Rx" SG_ 1254 BalrRight3Prev3Y_L_Actl 1;
BA_ "GenSigStartValueInteger" SG_ 1254 BalrRight3Prev3Y_L_Actl 64;
BA_ "U_CD542_MY2021_Rx" SG_ 1254 BalrRight3Prev3X_L_Actl 1;
BA_ "U_T6_MCA_MY2020_Rx" SG_ 1254 BalrRight3Prev3X_L_Actl 1;
BA_ "GenSigStartValueInteger" SG_ 1254 BalrRight3Prev3X_L_Actl 64;
BA_ "U_CD542_MY2021_Rx" SG_ 1254 BalrRight3Prev2Y_L_Actl 1;
BA_ "U_T6_MCA_MY2020_Rx" SG_ 1254 BalrRight3Prev2Y_L_Actl 1;
BA_ "GenSigStartValueInteger" SG_ 1254 BalrRight3Prev2Y_L_Actl 64;
BA_ "U_CD542_MY2021_Rx" SG_ 1254 BalrRight3Prev2X_L_Actl 1;
BA_ "U_T6_MCA_MY2020_Rx" SG_ 1254 BalrRight3Prev2X_L_Actl 1;
BA_ "GenSigStartValueInteger" SG_ 1254 BalrRight3Prev2X_L_Actl 64;
BA_ "U_CD542_MY2021_Rx" SG_ 1254 BalrRight3Prev1Y_L_Actl 1;
BA_ "U_T6_MCA_MY2020_Rx" SG_ 1254 BalrRight3Prev1Y_L_Actl 1;
BA_ "GenSigStartValueInteger" SG_ 1254 BalrRight3Prev1Y_L_Actl 64;
BA_ "U_CD542_MY2021_Rx" SG_ 1254 BalrRight3Prev1X_L_Actl 1;
BA_ "U_T6_MCA_MY2020_Rx" SG_ 1254 BalrRight3Prev1X_L_Actl 1;
BA_ "GenSigStartValueInteger" SG_ 1254 BalrRight3Prev1X_L_Actl 64;
BA_ "U_CD542_MY2021_Rx" SG_ 1254 BalrRight3Fast_B_Stat 1;
BA_ "U_T6_MCA_MY2020_Rx" SG_ 1254 BalrRight3Fast_B_Stat 1;
BA_ "U_CD542_MY2021_Rx" SG_ 1254 BalrRight3Dsply_B_Stat 1;
BA_ "U_T6_MCA_MY2020_Rx" SG_ 1254 BalrRight3Dsply_B_Stat 1;
BA_ "U_CD542_MY2021_Rx" SG_ 1254 BalrRight3CurntY_L_Actl 1;
BA_ "U_T6_MCA_MY2020_Rx" SG_ 1254 BalrRight3CurntY_L_Actl 1;
BA_ "GenSigStartValueInteger" SG_ 1254 BalrRight3CurntY_L_Actl 64;
BA_ "U_CD542_MY2021_Rx" SG_ 1254 BalrRight3CurntX_L_Actl 1;
BA_ "U_T6_MCA_MY2020_Rx" SG_ 1254 BalrRight3CurntX_L_Actl 1;
BA_ "GenSigStartValueInteger" SG_ 1254 BalrRight3CurntX_L_Actl 64;
BA_ "U_CD542_MY2021_Rx" SG_ 1253 BalrRight2Prev3Y_L_Actl 1;
BA_ "U_T6_MCA_MY2020_Rx" SG_ 1253 BalrRight2Prev3Y_L_Actl 1;
BA_ "GenSigStartValueInteger" SG_ 1253 BalrRight2Prev3Y_L_Actl 64;
BA_ "U_CD542_MY2021_Rx" SG_ 1253 BalrRight2Prev3X_L_Actl 1;
BA_ "U_T6_MCA_MY2020_Rx" SG_ 1253 BalrRight2Prev3X_L_Actl 1;
BA_ "GenSigStartValueInteger" SG_ 1253 BalrRight2Prev3X_L_Actl 64;
BA_ "U_CD542_MY2021_Rx" SG_ 1253 BalrRight2Threat_D_Stat 1;
BA_ "U_T6_MCA_MY2020_Rx" SG_ 1253 BalrRight2Threat_D_Stat 1;
BA_ "U_CD542_MY2021_Rx" SG_ 1253 BalrRight2Prev2Y_L_Actl 1;
BA_ "U_T6_MCA_MY2020_Rx" SG_ 1253 BalrRight2Prev2Y_L_Actl 1;
BA_ "GenSigStartValueInteger" SG_ 1253 BalrRight2Prev2Y_L_Actl 64;
BA_ "U_CD542_MY2021_Rx" SG_ 1253 BalrRight2Prev2X_L_Actl 1;
BA_ "U_T6_MCA_MY2020_Rx" SG_ 1253 BalrRight2Prev2X_L_Actl 1;
BA_ "GenSigStartValueInteger" SG_ 1253 BalrRight2Prev2X_L_Actl 64;
BA_ "U_CD542_MY2021_Rx" SG_ 1253 BalrRight2Prev1Y_L_Actl 1;
BA_ "U_T6_MCA_MY2020_Rx" SG_ 1253 BalrRight2Prev1Y_L_Actl 1;
BA_ "GenSigStartValueInteger" SG_ 1253 BalrRight2Prev1Y_L_Actl 64;
BA_ "U_CD542_MY2021_Rx" SG_ 1253 BalrRight2Prev1X_L_Actl 1;
BA_ "U_T6_MCA_MY2020_Rx" SG_ 1253 BalrRight2Prev1X_L_Actl 1;
BA_ "GenSigStartValueInteger" SG_ 1253 BalrRight2Prev1X_L_Actl 64;
BA_ "U_CD542_MY2021_Rx" SG_ 1253 BalrRight2Fast_B_Stat 1;
BA_ "U_T6_MCA_MY2020_Rx" SG_ 1253 BalrRight2Fast_B_Stat 1;
BA_ "U_CD542_MY2021_Rx" SG_ 1253 BalrRight2Dsply_B_Stat 1;
BA_ "U_T6_MCA_MY2020_Rx" SG_ 1253 BalrRight2Dsply_B_Stat 1;
BA_ "U_CD542_MY2021_Rx" SG_ 1253 BalrRight2CurntY_L_Actl 1;
BA_ "U_T6_MCA_MY2020_Rx" SG_ 1253 BalrRight2CurntY_L_Actl 1;
BA_ "GenSigStartValueInteger" SG_ 1253 BalrRight2CurntY_L_Actl 64;
BA_ "U_CD542_MY2021_Rx" SG_ 1253 BalrRight2CurntX_L_Actl 1;
BA_ "U_T6_MCA_MY2020_Rx" SG_ 1253 BalrRight2CurntX_L_Actl 1;
BA_ "GenSigStartValueInteger" SG_ 1253 BalrRight2CurntX_L_Actl 64;
BA_ "U_CD542_MY2021_Rx" SG_ 1252 BalrRight1Prev3Y_L_Actl 1;
BA_ "U_T6_MCA_MY2020_Rx" SG_ 1252 BalrRight1Prev3Y_L_Actl 1;
BA_ "GenSigStartValueInteger" SG_ 1252 BalrRight1Prev3Y_L_Actl 64;
BA_ "U_CD542_MY2021_Rx" SG_ 1252 BalrRight1Prev3X_L_Actl 1;
BA_ "U_T6_MCA_MY2020_Rx" SG_ 1252 BalrRight1Prev3X_L_Actl 1;
BA_ "GenSigStartValueInteger" SG_ 1252 BalrRight1Prev3X_L_Actl 64;
BA_ "U_CD542_MY2021_Rx" SG_ 1252 BalrRight1Threat_D_Stat 1;
BA_ "U_T6_MCA_MY2020_Rx" SG_ 1252 BalrRight1Threat_D_Stat 1;
BA_ "U_CD542_MY2021_Rx" SG_ 1252 BalrRight1Prev2Y_L_Actl 1;
BA_ "U_T6_MCA_MY2020_Rx" SG_ 1252 BalrRight1Prev2Y_L_Actl 1;
BA_ "GenSigStartValueInteger" SG_ 1252 BalrRight1Prev2Y_L_Actl 64;
BA_ "U_CD542_MY2021_Rx" SG_ 1252 BalrRight1Prev2X_L_Actl 1;
BA_ "U_T6_MCA_MY2020_Rx" SG_ 1252 BalrRight1Prev2X_L_Actl 1;
BA_ "GenSigStartValueInteger" SG_ 1252 BalrRight1Prev2X_L_Actl 64;
BA_ "U_CD542_MY2021_Rx" SG_ 1252 BalrRight1Prev1Y_L_Actl 1;
BA_ "U_T6_MCA_MY2020_Rx" SG_ 1252 BalrRight1Prev1Y_L_Actl 1;
BA_ "GenSigStartValueInteger" SG_ 1252 BalrRight1Prev1Y_L_Actl 64;
BA_ "U_CD542_MY2021_Rx" SG_ 1252 BalrRight1Prev1X_L_Actl 1;
BA_ "U_T6_MCA_MY2020_Rx" SG_ 1252 BalrRight1Prev1X_L_Actl 1;
BA_ "GenSigStartValueInteger" SG_ 1252 BalrRight1Prev1X_L_Actl 64;
BA_ "U_CD542_MY2021_Rx" SG_ 1252 BalrRight1Fast_B_Stat 1;
BA_ "U_T6_MCA_MY2020_Rx" SG_ 1252 BalrRight1Fast_B_Stat 1;
BA_ "U_CD542_MY2021_Rx" SG_ 1252 BalrRight1Dsply_B_Stat 1;
BA_ "U_T6_MCA_MY2020_Rx" SG_ 1252 BalrRight1Dsply_B_Stat 1;
BA_ "U_CD542_MY2021_Rx" SG_ 1252 BalrRight1CurntY_L_Actl 1;
BA_ "U_T6_MCA_MY2020_Rx" SG_ 1252 BalrRight1CurntY_L_Actl 1;
BA_ "GenSigStartValueInteger" SG_ 1252 BalrRight1CurntY_L_Actl 64;
BA_ "U_CD542_MY2021_Rx" SG_ 1252 BalrRight1CurntX_L_Actl 1;
BA_ "U_T6_MCA_MY2020_Rx" SG_ 1252 BalrRight1CurntX_L_Actl 1;
BA_ "GenSigStartValueInteger" SG_ 1252 BalrRight1CurntX_L_Actl 64;
BA_ "U_CD542_MY2021_Rx" SG_ 1251 BalrLeft4Threat_D_Stat 1;
BA_ "U_T6_MCA_MY2020_Rx" SG_ 1251 BalrLeft4Threat_D_Stat 1;
BA_ "U_CD542_MY2021_Rx" SG_ 1251 BalrLeft4Prev3Y_L_Actl 1;
BA_ "U_T6_MCA_MY2020_Rx" SG_ 1251 BalrLeft4Prev3Y_L_Actl 1;
BA_ "GenSigStartValueInteger" SG_ 1251 BalrLeft4Prev3Y_L_Actl 64;
BA_ "U_CD542_MY2021_Rx" SG_ 1251 BalrLeft4Prev3X_L_Actl 1;
BA_ "U_T6_MCA_MY2020_Rx" SG_ 1251 BalrLeft4Prev3X_L_Actl 1;
BA_ "GenSigStartValueInteger" SG_ 1251 BalrLeft4Prev3X_L_Actl 64;
BA_ "U_CD542_MY2021_Rx" SG_ 1251 BalrLeft4Prev2Y_L_Actl 1;
BA_ "U_T6_MCA_MY2020_Rx" SG_ 1251 BalrLeft4Prev2Y_L_Actl 1;
BA_ "GenSigStartValueInteger" SG_ 1251 BalrLeft4Prev2Y_L_Actl 64;
BA_ "U_CD542_MY2021_Rx" SG_ 1251 BalrLeft4Prev2X_L_Actl 1;
BA_ "U_T6_MCA_MY2020_Rx" SG_ 1251 BalrLeft4Prev2X_L_Actl 1;
BA_ "GenSigStartValueInteger" SG_ 1251 BalrLeft4Prev2X_L_Actl 64;
BA_ "U_CD542_MY2021_Rx" SG_ 1251 BalrLeft4Prev1Y_L_Actl 1;
BA_ "U_T6_MCA_MY2020_Rx" SG_ 1251 BalrLeft4Prev1Y_L_Actl 1;
BA_ "GenSigStartValueInteger" SG_ 1251 BalrLeft4Prev1Y_L_Actl 64;
BA_ "U_CD542_MY2021_Rx" SG_ 1251 BalrLeft4Prev1X_L_Actl 1;
BA_ "U_T6_MCA_MY2020_Rx" SG_ 1251 BalrLeft4Prev1X_L_Actl 1;
BA_ "GenSigStartValueInteger" SG_ 1251 BalrLeft4Prev1X_L_Actl 64;
BA_ "U_CD542_MY2021_Rx" SG_ 1251 BalrLeft4Fast_B_Stat 1;
BA_ "U_T6_MCA_MY2020_Rx" SG_ 1251 BalrLeft4Fast_B_Stat 1;
BA_ "U_CD542_MY2021_Rx" SG_ 1251 BalrLeft4Dsply_B_Stat 1;
BA_ "U_T6_MCA_MY2020_Rx" SG_ 1251 BalrLeft4Dsply_B_Stat 1;
BA_ "U_CD542_MY2021_Rx" SG_ 1251 BalrLeft4CurntY_L_Actl 1;
BA_ "U_T6_MCA_MY2020_Rx" SG_ 1251 BalrLeft4CurntY_L_Actl 1;
BA_ "GenSigStartValueInteger" SG_ 1251 BalrLeft4CurntY_L_Actl 64;
BA_ "U_CD542_MY2021_Rx" SG_ 1251 BalrLeft4CurntX_L_Actl 1;
BA_ "U_T6_MCA_MY2020_Rx" SG_ 1251 BalrLeft4CurntX_L_Actl 1;
BA_ "GenSigStartValueInteger" SG_ 1251 BalrLeft4CurntX_L_Actl 64;
BA_ "U_CD542_MY2021_Rx" SG_ 1250 BalrLeft3Threat_D_Stat 1;
BA_ "U_T6_MCA_MY2020_Rx" SG_ 1250 BalrLeft3Threat_D_Stat 1;
BA_ "U_CD542_MY2021_Rx" SG_ 1250 BalrLeft3Prev3Y_L_Actl 1;
BA_ "U_T6_MCA_MY2020_Rx" SG_ 1250 BalrLeft3Prev3Y_L_Actl 1;
BA_ "GenSigStartValueInteger" SG_ 1250 BalrLeft3Prev3Y_L_Actl 64;
BA_ "U_CD542_MY2021_Rx" SG_ 1250 BalrLeft3Prev3X_L_Actl 1;
BA_ "U_T6_MCA_MY2020_Rx" SG_ 1250 BalrLeft3Prev3X_L_Actl 1;
BA_ "GenSigStartValueInteger" SG_ 1250 BalrLeft3Prev3X_L_Actl 64;
BA_ "U_CD542_MY2021_Rx" SG_ 1250 BalrLeft3Prev2Y_L_Actl 1;
BA_ "U_T6_MCA_MY2020_Rx" SG_ 1250 BalrLeft3Prev2Y_L_Actl 1;
BA_ "GenSigStartValueInteger" SG_ 1250 BalrLeft3Prev2Y_L_Actl 64;
BA_ "U_CD542_MY2021_Rx" SG_ 1250 BalrLeft3Prev2X_L_Actl 1;
BA_ "U_T6_MCA_MY2020_Rx" SG_ 1250 BalrLeft3Prev2X_L_Actl 1;
BA_ "GenSigStartValueInteger" SG_ 1250 BalrLeft3Prev2X_L_Actl 64;
BA_ "U_CD542_MY2021_Rx" SG_ 1250 BalrLeft3Prev1Y_L_Actl 1;
BA_ "U_T6_MCA_MY2020_Rx" SG_ 1250 BalrLeft3Prev1Y_L_Actl 1;
BA_ "GenSigStartValueInteger" SG_ 1250 BalrLeft3Prev1Y_L_Actl 64;
BA_ "U_CD542_MY2021_Rx" SG_ 1250 BalrLeft3Prev1X_L_Actl 1;
BA_ "U_T6_MCA_MY2020_Rx" SG_ 1250 BalrLeft3Prev1X_L_Actl 1;
BA_ "GenSigStartValueInteger" SG_ 1250 BalrLeft3Prev1X_L_Actl 64;
BA_ "U_CD542_MY2021_Rx" SG_ 1250 BalrLeft3Fast_B_Stat 1;
BA_ "U_T6_MCA_MY2020_Rx" SG_ 1250 BalrLeft3Fast_B_Stat 1;
BA_ "U_CD542_MY2021_Rx" SG_ 1250 BalrLeft3Dsply_B_Stat 1;
BA_ "U_T6_MCA_MY2020_Rx" SG_ 1250 BalrLeft3Dsply_B_Stat 1;
BA_ "U_CD542_MY2021_Rx" SG_ 1250 BalrLeft3CurntY_L_Actl 1;
BA_ "U_T6_MCA_MY2020_Rx" SG_ 1250 BalrLeft3CurntY_L_Actl 1;
BA_ "GenSigStartValueInteger" SG_ 1250 BalrLeft3CurntY_L_Actl 64;
BA_ "U_CD542_MY2021_Rx" SG_ 1250 BalrLeft3CurntX_L_Actl 1;
BA_ "U_T6_MCA_MY2020_Rx" SG_ 1250 BalrLeft3CurntX_L_Actl 1;
BA_ "GenSigStartValueInteger" SG_ 1250 BalrLeft3CurntX_L_Actl 64;
BA_ "U_CD542_MY2021_Rx" SG_ 1249 BalrLeft2Prev3Y_L_Actl 1;
BA_ "U_T6_MCA_MY2020_Rx" SG_ 1249 BalrLeft2Prev3Y_L_Actl 1;
BA_ "GenSigStartValueInteger" SG_ 1249 BalrLeft2Prev3Y_L_Actl 64;
BA_ "U_CD542_MY2021_Rx" SG_ 1249 BalrLeft2Prev3X_L_Actl 1;
BA_ "U_T6_MCA_MY2020_Rx" SG_ 1249 BalrLeft2Prev3X_L_Actl 1;
BA_ "GenSigStartValueInteger" SG_ 1249 BalrLeft2Prev3X_L_Actl 64;
BA_ "U_CD542_MY2021_Rx" SG_ 1249 BalrLeft2Threat_D_Stat 1;
BA_ "U_T6_MCA_MY2020_Rx" SG_ 1249 BalrLeft2Threat_D_Stat 1;
BA_ "U_CD542_MY2021_Rx" SG_ 1249 BalrLeft2Prev2Y_L_Actl 1;
BA_ "U_T6_MCA_MY2020_Rx" SG_ 1249 BalrLeft2Prev2Y_L_Actl 1;
BA_ "GenSigStartValueInteger" SG_ 1249 BalrLeft2Prev2Y_L_Actl 64;
BA_ "U_CD542_MY2021_Rx" SG_ 1249 BalrLeft2Prev2X_L_Actl 1;
BA_ "U_T6_MCA_MY2020_Rx" SG_ 1249 BalrLeft2Prev2X_L_Actl 1;
BA_ "GenSigStartValueInteger" SG_ 1249 BalrLeft2Prev2X_L_Actl 64;
BA_ "U_CD542_MY2021_Rx" SG_ 1249 BalrLeft2Prev1Y_L_Actl 1;
BA_ "U_T6_MCA_MY2020_Rx" SG_ 1249 BalrLeft2Prev1Y_L_Actl 1;
BA_ "GenSigStartValueInteger" SG_ 1249 BalrLeft2Prev1Y_L_Actl 64;
BA_ "U_CD542_MY2021_Rx" SG_ 1249 BalrLeft2Prev1X_L_Actl 1;
BA_ "U_T6_MCA_MY2020_Rx" SG_ 1249 BalrLeft2Prev1X_L_Actl 1;
BA_ "GenSigStartValueInteger" SG_ 1249 BalrLeft2Prev1X_L_Actl 64;
BA_ "U_CD542_MY2021_Rx" SG_ 1249 BalrLeft2Fast_B_Stat 1;
BA_ "U_T6_MCA_MY2020_Rx" SG_ 1249 BalrLeft2Fast_B_Stat 1;
BA_ "U_CD542_MY2021_Rx" SG_ 1249 BalrLeft2Dsply_B_Stat 1;
BA_ "U_T6_MCA_MY2020_Rx" SG_ 1249 BalrLeft2Dsply_B_Stat 1;
BA_ "U_CD542_MY2021_Rx" SG_ 1249 BalrLeft2CurntY_L_Actl 1;
BA_ "U_T6_MCA_MY2020_Rx" SG_ 1249 BalrLeft2CurntY_L_Actl 1;
BA_ "GenSigStartValueInteger" SG_ 1249 BalrLeft2CurntY_L_Actl 64;
BA_ "U_CD542_MY2021_Rx" SG_ 1249 BalrLeft2CurntX_L_Actl 1;
BA_ "U_T6_MCA_MY2020_Rx" SG_ 1249 BalrLeft2CurntX_L_Actl 1;
BA_ "GenSigStartValueInteger" SG_ 1249 BalrLeft2CurntX_L_Actl 64;
BA_ "U_CD542_MY2021_Rx" SG_ 1248 BalrLeft1Threat_D_Stat 1;
BA_ "U_T6_MCA_MY2020_Rx" SG_ 1248 BalrLeft1Threat_D_Stat 1;
BA_ "U_CD542_MY2021_Rx" SG_ 1248 BalrLeft1Prev3Y_L_Actl 1;
BA_ "U_T6_MCA_MY2020_Rx" SG_ 1248 BalrLeft1Prev3Y_L_Actl 1;
BA_ "GenSigStartValueInteger" SG_ 1248 BalrLeft1Prev3Y_L_Actl 64;
BA_ "U_CD542_MY2021_Rx" SG_ 1248 BalrLeft1Prev3X_L_Actl 1;
BA_ "U_T6_MCA_MY2020_Rx" SG_ 1248 BalrLeft1Prev3X_L_Actl 1;
BA_ "GenSigStartValueInteger" SG_ 1248 BalrLeft1Prev3X_L_Actl 64;
BA_ "U_CD542_MY2021_Rx" SG_ 1248 BalrLeft1Prev2Y_L_Actl 1;
BA_ "U_T6_MCA_MY2020_Rx" SG_ 1248 BalrLeft1Prev2Y_L_Actl 1;
BA_ "GenSigStartValueInteger" SG_ 1248 BalrLeft1Prev2Y_L_Actl 64;
BA_ "U_CD542_MY2021_Rx" SG_ 1248 BalrLeft1Prev2X_L_Actl 1;
BA_ "U_T6_MCA_MY2020_Rx" SG_ 1248 BalrLeft1Prev2X_L_Actl 1;
BA_ "GenSigStartValueInteger" SG_ 1248 BalrLeft1Prev2X_L_Actl 64;
BA_ "U_CD542_MY2021_Rx" SG_ 1248 BalrLeft1Prev1Y_L_Actl 1;
BA_ "U_T6_MCA_MY2020_Rx" SG_ 1248 BalrLeft1Prev1Y_L_Actl 1;
BA_ "GenSigStartValueInteger" SG_ 1248 BalrLeft1Prev1Y_L_Actl 64;
BA_ "U_CD542_MY2021_Rx" SG_ 1248 BalrLeft1Prev1X_L_Actl 1;
BA_ "U_T6_MCA_MY2020_Rx" SG_ 1248 BalrLeft1Prev1X_L_Actl 1;
BA_ "GenSigStartValueInteger" SG_ 1248 BalrLeft1Prev1X_L_Actl 64;
BA_ "U_CD542_MY2021_Rx" SG_ 1248 BalrLeft1Fast_B_Stat 1;
BA_ "U_T6_MCA_MY2020_Rx" SG_ 1248 BalrLeft1Fast_B_Stat 1;
BA_ "U_CD542_MY2021_Rx" SG_ 1248 BalrLeft1Dsply_B_Stat 1;
BA_ "U_T6_MCA_MY2020_Rx" SG_ 1248 BalrLeft1Dsply_B_Stat 1;
BA_ "U_CD542_MY2021_Rx" SG_ 1248 BalrLeft1CurntY_L_Actl 1;
BA_ "U_T6_MCA_MY2020_Rx" SG_ 1248 BalrLeft1CurntY_L_Actl 1;
BA_ "GenSigStartValueInteger" SG_ 1248 BalrLeft1CurntY_L_Actl 64;
BA_ "U_CD542_MY2021_Rx" SG_ 1248 BalrLeft1CurntX_L_Actl 1;
BA_ "U_T6_MCA_MY2020_Rx" SG_ 1248 BalrLeft1CurntX_L_Actl 1;
BA_ "GenSigStartValueInteger" SG_ 1248 BalrLeft1CurntX_L_Actl 64;
BA_ "U_T6_MCA_MY2020_Rx" SG_ 1256 StopLamp_B_RqTrlrAft_UB 1;
BA_ "U_T6_MCA_MY2020_Rx" SG_ 1256 StopLamp_B_RqTrlrAft 1;
BA_ "GenSigSendType" SG_ 1256 StopLamp_B_RqTrlrAft 3;
BA_ "U_CD542_MY2021_Rx" SG_ 1256 BalrMdeRight_D_Stat_UB 1;
BA_ "U_T6_MCA_MY2020_Rx" SG_ 1256 BalrMdeRight_D_Stat_UB 1;
BA_ "U_CD542_MY2021_Rx" SG_ 1256 BalrMdeSelRight_B_Stat_UB 1;
BA_ "U_T6_MCA_MY2020_Rx" SG_ 1256 BalrMdeSelRight_B_Stat_UB 1;
BA_ "U_CD542_MY2021_Rx" SG_ 1256 BalrRight_D_Stat_UB 1;
BA_ "U_T6_MCA_MY2020_Rx" SG_ 1256 BalrRight_D_Stat_UB 1;
BA_ "U_CD542_MY2021_Rx" SG_ 1256 BalrLckRight_B_Stat_UB 1;
BA_ "U_T6_MCA_MY2020_Rx" SG_ 1256 BalrLckRight_B_Stat_UB 1;
BA_ "U_CD542_MY2021_Rx" SG_ 1256 BalrChimeRight_D_Rq_UB 1;
BA_ "U_T6_MCA_MY2020_Rx" SG_ 1256 BalrChimeRight_D_Rq_UB 1;
BA_ "U_CD542_MY2021_Rx" SG_ 1256 BalrSnsRight_D_Falt_UB 1;
BA_ "U_T6_MCA_MY2020_Rx" SG_ 1256 BalrSnsRight_D_Falt_UB 1;
BA_ "U_CD542_MY2021_Rx" SG_ 1256 BalrWndwRight_B_Stat_UB 1;
BA_ "U_T6_MCA_MY2020_Rx" SG_ 1256 BalrWndwRight_B_Stat_UB 1;
BA_ "U_CD542_MY2021_Rx" SG_ 1256 BalrLckRight_B_Stat 1;
BA_ "U_T6_MCA_MY2020_Rx" SG_ 1256 BalrLckRight_B_Stat 1;
BA_ "GenSigSendType" SG_ 1256 BalrLckRight_B_Stat 3;
BA_ "U_CD542_MY2021_Rx" SG_ 1256 BalrWndwRight_B_Stat 1;
BA_ "U_T6_MCA_MY2020_Rx" SG_ 1256 BalrWndwRight_B_Stat 1;
BA_ "GenSigSendType" SG_ 1256 BalrWndwRight_B_Stat 3;
BA_ "U_CD542_MY2021_Rx" SG_ 1256 BalrMdeSelRight_B_Stat 1;
BA_ "U_T6_MCA_MY2020_Rx" SG_ 1256 BalrMdeSelRight_B_Stat 1;
BA_ "GenSigSendType" SG_ 1256 BalrMdeSelRight_B_Stat 3;
BA_ "U_CD542_MY2021_Rx" SG_ 1256 BalrSnsRight_D_Falt 1;
BA_ "U_T6_MCA_MY2020_Rx" SG_ 1256 BalrSnsRight_D_Falt 1;
BA_ "GenSigSendType" SG_ 1256 BalrSnsRight_D_Falt 3;
BA_ "U_CD542_MY2021_Rx" SG_ 1256 BalrChimeRight_D_Rq 1;
BA_ "U_T6_MCA_MY2020_Rx" SG_ 1256 BalrChimeRight_D_Rq 1;
BA_ "GenSigSendType" SG_ 1256 BalrChimeRight_D_Rq 3;
BA_ "U_CD542_MY2021_Rx" SG_ 1256 BalrMdeRight_D_Stat 1;
BA_ "U_T6_MCA_MY2020_Rx" SG_ 1256 BalrMdeRight_D_Stat 1;
BA_ "GenSigSendType" SG_ 1256 BalrMdeRight_D_Stat 3;
BA_ "GenSigStartValue" SG_ 1256 BalrMdeRight_D_Stat 1;
BA_ "GenSigStartValueInteger" SG_ 1256 BalrMdeRight_D_Stat 1;
BA_ "U_CD542_MY2021_Rx" SG_ 1256 BalrRight_D_Stat 1;
BA_ "U_T6_MCA_MY2020_Rx" SG_ 1256 BalrRight_D_Stat 1;
BA_ "GenSigSendType" SG_ 1256 BalrRight_D_Stat 3;
BA_ "GenSigStartValue" SG_ 1256 BalrRight_D_Stat 2;
BA_ "GenSigStartValueInteger" SG_ 1256 BalrRight_D_Stat 2;
BA_ "U_CD542_MY2021_Rx" SG_ 1256 BalrWndwLeft_B_Stat_UB 1;
BA_ "U_T6_MCA_MY2020_Rx" SG_ 1256 BalrWndwLeft_B_Stat_UB 1;
BA_ "U_CD542_MY2021_Rx" SG_ 1256 BalrSnsLeft_D_Falt_UB 1;
BA_ "U_T6_MCA_MY2020_Rx" SG_ 1256 BalrSnsLeft_D_Falt_UB 1;
BA_ "U_CD542_MY2021_Rx" SG_ 1256 BalrMdeSelLeft_B_Stat_UB 1;
BA_ "U_T6_MCA_MY2020_Rx" SG_ 1256 BalrMdeSelLeft_B_Stat_UB 1;
BA_ "U_CD542_MY2021_Rx" SG_ 1256 BalrMdeLeft_D_Stat_UB 1;
BA_ "U_T6_MCA_MY2020_Rx" SG_ 1256 BalrMdeLeft_D_Stat_UB 1;
BA_ "U_CD542_MY2021_Rx" SG_ 1256 BalrLeft_D_Stat_UB 1;
BA_ "U_T6_MCA_MY2020_Rx" SG_ 1256 BalrLeft_D_Stat_UB 1;
BA_ "U_CD542_MY2021_Rx" SG_ 1256 BalrLckLeft_B_Stat_UB 1;
BA_ "U_T6_MCA_MY2020_Rx" SG_ 1256 BalrLckLeft_B_Stat_UB 1;
BA_ "U_CD542_MY2021_Rx" SG_ 1256 BalrChimeLeft_D_Rq_UB 1;
BA_ "U_T6_MCA_MY2020_Rx" SG_ 1256 BalrChimeLeft_D_Rq_UB 1;
BA_ "U_CD542_MY2021_Rx" SG_ 1256 BalrLeft_D_Stat 1;
BA_ "U_T6_MCA_MY2020_Rx" SG_ 1256 BalrLeft_D_Stat 1;
BA_ "GenSigSendType" SG_ 1256 BalrLeft_D_Stat 3;
BA_ "GenSigStartValue" SG_ 1256 BalrLeft_D_Stat 2;
BA_ "GenSigStartValueInteger" SG_ 1256 BalrLeft_D_Stat 2;
BA_ "U_CD542_MY2021_Rx" SG_ 1256 BalrMdeSelLeft_B_Stat 1;
BA_ "U_T6_MCA_MY2020_Rx" SG_ 1256 BalrMdeSelLeft_B_Stat 1;
BA_ "GenSigSendType" SG_ 1256 BalrMdeSelLeft_B_Stat 3;
BA_ "U_CD542_MY2021_Rx" SG_ 1256 BalrLckLeft_B_Stat 1;
BA_ "U_T6_MCA_MY2020_Rx" SG_ 1256 BalrLckLeft_B_Stat 1;
BA_ "GenSigSendType" SG_ 1256 BalrLckLeft_B_Stat 3;
BA_ "U_CD542_MY2021_Rx" SG_ 1256 BalrWndwLeft_B_Stat 1;
BA_ "U_T6_MCA_MY2020_Rx" SG_ 1256 BalrWndwLeft_B_Stat 1;
BA_ "GenSigSendType" SG_ 1256 BalrWndwLeft_B_Stat 3;
BA_ "U_CD542_MY2021_Rx" SG_ 1256 BalrMdeLeft_D_Stat 1;
BA_ "U_T6_MCA_MY2020_Rx" SG_ 1256 BalrMdeLeft_D_Stat 1;
BA_ "GenSigSendType" SG_ 1256 BalrMdeLeft_D_Stat 3;
BA_ "GenSigStartValue" SG_ 1256 BalrMdeLeft_D_Stat 1;
BA_ "GenSigStartValueInteger" SG_ 1256 BalrMdeLeft_D_Stat 1;
BA_ "U_CD542_MY2021_Rx" SG_ 1256 BalrSnsLeft_D_Falt 1;
BA_ "U_T6_MCA_MY2020_Rx" SG_ 1256 BalrSnsLeft_D_Falt 1;
BA_ "GenSigSendType" SG_ 1256 BalrSnsLeft_D_Falt 3;
BA_ "U_CD542_MY2021_Rx" SG_ 1256 BalrChimeLeft_D_Rq 1;
BA_ "U_T6_MCA_MY2020_Rx" SG_ 1256 BalrChimeLeft_D_Rq 1;
BA_ "GenSigSendType" SG_ 1256 BalrChimeLeft_D_Rq 3;
BA_ "U_U55X_MY2022_Rx" SG_ 1256 WakeAlarm2_D_Stat_UB 1;
BA_ "U_T6_MCA_MY2020_Rx" SG_ 1256 WakeAlarm2_D_Stat_UB 1;
BA_ "U_U55X_MY2022_Rx" SG_ 1256 WakeAlarm2_D_Stat 1;
BA_ "U_T6_MCA_MY2020_Rx" SG_ 1256 WakeAlarm2_D_Stat 1;
BA_ "GenSigSendType" SG_ 1256 WakeAlarm2_D_Stat 3;
BA_ "GenSigStartValue" SG_ 1256 WakeAlarm2_D_Stat 3;
BA_ "GenSigStartValueInteger" SG_ 1256 WakeAlarm2_D_Stat 3;
BA_ "U_T6_MCA_MY2020_Tx" SG_ 529 OnbChrgToPcWknd_D_Actl 1;
BA_ "U_P702_MY2021_Tx" SG_ 529 OnbChrgToPcWknd_D_Actl 1;
BA_ "U_U55X_MY2022_Tx" SG_ 529 OnbChrgToPcWknd_D_Actl 1;
BA_ "U_CD542_MY2021_Tx" SG_ 529 OnbChrgToPcWknd_D_Actl 1;
BA_ "U_T6_MCA_MY2020_Tx" SG_ 529 OnbChrgToPcWkdy_D_Actl 1;
BA_ "U_P702_MY2021_Tx" SG_ 529 OnbChrgToPcWkdy_D_Actl 1;
BA_ "U_U55X_MY2022_Tx" SG_ 529 OnbChrgToPcWkdy_D_Actl 1;
BA_ "U_CD542_MY2021_Tx" SG_ 529 OnbChrgToPcWkdy_D_Actl 1;
BA_ "U_T6_MCA_MY2020_Tx" SG_ 529 OnbChrgSetNow_D_Rq 1;
BA_ "U_P702_MY2021_Tx" SG_ 529 OnbChrgSetNow_D_Rq 1;
BA_ "U_U55X_MY2022_Tx" SG_ 529 OnbChrgSetNow_D_Rq 1;
BA_ "U_CD542_MY2021_Tx" SG_ 529 OnbChrgSetNow_D_Rq 1;
BA_ "U_T6_MCA_MY2020_Tx" SG_ 529 OnbChrgSetDelete_B_Rq 1;
BA_ "U_P702_MY2021_Tx" SG_ 529 OnbChrgSetDelete_B_Rq 1;
BA_ "U_U55X_MY2022_Tx" SG_ 529 OnbChrgSetDelete_B_Rq 1;
BA_ "U_CD542_MY2021_Tx" SG_ 529 OnbChrgSetDelete_B_Rq 1;
BA_ "U_T6_MCA_MY2020_Tx" SG_ 529 OnbChrgPrflWknd_No_Rq 1;
BA_ "U_P702_MY2021_Tx" SG_ 529 OnbChrgPrflWknd_No_Rq 1;
BA_ "U_U55X_MY2022_Tx" SG_ 529 OnbChrgPrflWknd_No_Rq 1;
BA_ "U_CD542_MY2021_Tx" SG_ 529 OnbChrgPrflWknd_No_Rq 1;
BA_ "U_T6_MCA_MY2020_Tx" SG_ 529 OnbChrgPrflWkdy_No_Rq 1;
BA_ "U_P702_MY2021_Tx" SG_ 529 OnbChrgPrflWkdy_No_Rq 1;
BA_ "U_U55X_MY2022_Tx" SG_ 529 OnbChrgPrflWkdy_No_Rq 1;
BA_ "U_CD542_MY2021_Tx" SG_ 529 OnbChrgPrflWkdy_No_Rq 1;
BA_ "U_T6_MCA_MY2020_Tx" SG_ 529 OnbChrgPrflUpdate_B_Rq 1;
BA_ "U_P702_MY2021_Tx" SG_ 529 OnbChrgPrflUpdate_B_Rq 1;
BA_ "U_U55X_MY2022_Tx" SG_ 529 OnbChrgPrflUpdate_B_Rq 1;
BA_ "U_CD542_MY2021_Tx" SG_ 529 OnbChrgPrflUpdate_B_Rq 1;
BA_ "U_U55X_MY2022_Rx" SG_ 529 OnbChrgPrflUpdate_B_Rq 1;
BA_ "U_CD542_MY2021_Rx" SG_ 529 OnbChrgPrflUpdate_B_Rq 1;
BA_ "ECGUsedRxSignal" SG_ 529 OnbChrgPrflUpdate_B_Rq 1;
BA_ "U_T6_MCA_MY2020_Rx" SG_ 529 OnbChrgPrflUpdate_B_Rq 1;
BA_ "GenSigSendType" SG_ 529 OnbChrgPrflUpdate_B_Rq 3;
BA_ "U_T6_MCA_MY2020_Tx" SG_ 529 OnbChrgLocIdUns_B_Rq 1;
BA_ "U_P702_MY2021_Tx" SG_ 529 OnbChrgLocIdUns_B_Rq 1;
BA_ "U_U55X_MY2022_Tx" SG_ 529 OnbChrgLocIdUns_B_Rq 1;
BA_ "U_CD542_MY2021_Tx" SG_ 529 OnbChrgLocIdUns_B_Rq 1;
BA_ "U_U55X_MY2022_Tx" SG_ 529 OnbChrgLocIdTrgt_No_Rq 1;
BA_ "U_CD542_MY2021_Tx" SG_ 529 OnbChrgLocIdTrgt_No_Rq 1;
BA_ "U_T6_MCA_MY2020_Tx" SG_ 529 OnbChrgLocIdTrgt_No_Rq 1;
BA_ "U_P702_MY2021_Tx" SG_ 529 OnbChrgLocIdTrgt_No_Rq 1;
BA_ "GenSigSendType" SG_ 529 OnbChrgLocIdTrgt_No_Rq 3;
BA_ "U_CD542_MY2021_Rx" SG_ 642 SldrrMsgTxt_D2_Rq_UB 1;
BA_ "U_T6_MCA_MY2020_Rx" SG_ 642 SldrrMsgTxt_D2_Rq_UB 1;
BA_ "U_CD542_MY2021_Rx" SG_ 642 SldrrMsgTxt_D2_Rq 1;
BA_ "U_T6_MCA_MY2020_Rx" SG_ 642 SldrrMsgTxt_D2_Rq 1;
BA_ "GenSigSendType" SG_ 642 SldrrMsgTxt_D2_Rq 3;
BA_ "WakeupSignal" SG_ 642 SldrrMsgTxt_D2_Rq 1;
BA_ "U_CD542_MY2021_Rx" SG_ 642 SldrrChime_D_Rq_UB 1;
BA_ "U_T6_MCA_MY2020_Rx" SG_ 642 SldrrChime_D_Rq_UB 1;
BA_ "U_CD542_MY2021_Rx" SG_ 642 SldrrChime_D_Rq 1;
BA_ "U_T6_MCA_MY2020_Rx" SG_ 642 SldrrChime_D_Rq 1;
BA_ "GenSigSendType" SG_ 642 SldrrChime_D_Rq 3;
BA_ "WakeupSignal" SG_ 642 SldrrChime_D_Rq 1;
BA_ "U_CD542_MY2021_Rx" SG_ 642 SldrlMsgTxt_D2_Rq_UB 1;
BA_ "U_T6_MCA_MY2020_Rx" SG_ 642 SldrlMsgTxt_D2_Rq_UB 1;
BA_ "U_CD542_MY2021_Rx" SG_ 642 SldrlMsgTxt_D2_Rq 1;
BA_ "U_T6_MCA_MY2020_Rx" SG_ 642 SldrlMsgTxt_D2_Rq 1;
BA_ "GenSigSendType" SG_ 642 SldrlMsgTxt_D2_Rq 3;
BA_ "WakeupSignal" SG_ 642 SldrlMsgTxt_D2_Rq 1;
BA_ "U_CD542_MY2021_Rx" SG_ 642 SldrlChime_D_Rq_UB 1;
BA_ "U_T6_MCA_MY2020_Rx" SG_ 642 SldrlChime_D_Rq_UB 1;
BA_ "U_CD542_MY2021_Rx" SG_ 642 SldrlChime_D_Rq 1;
BA_ "U_T6_MCA_MY2020_Rx" SG_ 642 SldrlChime_D_Rq 1;
BA_ "GenSigSendType" SG_ 642 SldrlChime_D_Rq 3;
BA_ "WakeupSignal" SG_ 642 SldrlChime_D_Rq 1;
BA_ "U_CD542_MY2021_Rx" SG_ 642 PaakMyKeySearch_D_Stat_UB 1;
BA_ "U_U55X_MY2022_Rx" SG_ 642 PaakMyKeySearch_D_Stat_UB 1;
BA_ "U_T6_MCA_MY2020_Rx" SG_ 642 PaakMyKeySearch_D_Stat_UB 1;
BA_ "U_P702_MY2021_Rx" SG_ 642 PaakMyKeySearch_D_Stat_UB 1;
BA_ "U_CD542_MY2021_Rx" SG_ 642 UreaLvlQlty_D_RqDsply_UB 1;
BA_ "U_T6_MCA_MY2020_Rx" SG_ 642 UreaLvlQlty_D_RqDsply_UB 1;
BA_ "U_P702_MY2021_Rx" SG_ 642 UreaLvlQlty_D_RqDsply_UB 1;
BA_ "U_CD542_MY2021_Rx" SG_ 642 DieslPrtcWarn_D_Rq_UB 1;
BA_ "U_T6_MCA_MY2020_Rx" SG_ 642 DieslPrtcWarn_D_Rq_UB 1;
BA_ "U_CD542_MY2021_Rx" SG_ 642 UreaQltySysWarn_D_Rq_UB 1;
BA_ "U_T6_MCA_MY2020_Rx" SG_ 642 UreaQltySysWarn_D_Rq_UB 1;
BA_ "U_P702_MY2021_Rx" SG_ 642 UreaQltySysWarn_D_Rq_UB 1;
BA_ "U_CD542_MY2021_Rx" SG_ 642 UreaLvlTxtWarn_D_Rq_UB 1;
BA_ "U_T6_MCA_MY2020_Rx" SG_ 642 UreaLvlTxtWarn_D_Rq_UB 1;
BA_ "U_P702_MY2021_Rx" SG_ 642 UreaLvlTxtWarn_D_Rq_UB 1;
BA_ "U_CD542_MY2021_Rx" SG_ 642 UreaLvlQlty_D_RqDsply 1;
BA_ "U_T6_MCA_MY2020_Rx" SG_ 642 UreaLvlQlty_D_RqDsply 1;
BA_ "U_P702_MY2021_Rx" SG_ 642 UreaLvlQlty_D_RqDsply 1;
BA_ "GenSigSendType" SG_ 642 UreaLvlQlty_D_RqDsply 3;
BA_ "U_CD542_MY2021_Rx" SG_ 642 UreaLvlTxtWarn_D_Rq 1;
BA_ "U_T6_MCA_MY2020_Rx" SG_ 642 UreaLvlTxtWarn_D_Rq 1;
BA_ "U_P702_MY2021_Rx" SG_ 642 UreaLvlTxtWarn_D_Rq 1;
BA_ "GenSigSendType" SG_ 642 UreaLvlTxtWarn_D_Rq 3;
BA_ "U_CD542_MY2021_Rx" SG_ 642 UreaQltySysWarn_D_Rq 1;
BA_ "U_T6_MCA_MY2020_Rx" SG_ 642 UreaQltySysWarn_D_Rq 1;
BA_ "U_P702_MY2021_Rx" SG_ 642 UreaQltySysWarn_D_Rq 1;
BA_ "GenSigSendType" SG_ 642 UreaQltySysWarn_D_Rq 3;
BA_ "U_CD542_MY2021_Rx" SG_ 642 DieslPrtcWarn_D_Rq 1;
BA_ "U_T6_MCA_MY2020_Rx" SG_ 642 DieslPrtcWarn_D_Rq 1;
BA_ "GenSigSendType" SG_ 642 DieslPrtcWarn_D_Rq 3;
BA_ "U_U55X_MY2022_Rx" SG_ 642 KeyMyKeyTot_No2_Cnt_UB 1;
BA_ "U_CD542_MY2021_Rx" SG_ 642 KeyMyKeyTot_No2_Cnt_UB 1;
BA_ "U_T6_MCA_MY2020_Rx" SG_ 642 KeyMyKeyTot_No2_Cnt_UB 1;
BA_ "U_P702_MY2021_Rx" SG_ 642 KeyMyKeyTot_No2_Cnt_UB 1;
BA_ "U_U55X_MY2022_Rx" SG_ 642 KeyAdmnTot_No2_Cnt_UB 1;
BA_ "U_CD542_MY2021_Rx" SG_ 642 KeyAdmnTot_No2_Cnt_UB 1;
BA_ "U_T6_MCA_MY2020_Rx" SG_ 642 KeyAdmnTot_No2_Cnt_UB 1;
BA_ "U_P702_MY2021_Rx" SG_ 642 KeyAdmnTot_No2_Cnt_UB 1;
BA_ "U_CD542_MY2021_Rx" SG_ 642 KeyMyKeyTot_No2_Cnt 1;
BA_ "U_U55X_MY2022_Rx" SG_ 642 KeyMyKeyTot_No2_Cnt 1;
BA_ "U_T6_MCA_MY2020_Rx" SG_ 642 KeyMyKeyTot_No2_Cnt 1;
BA_ "U_P702_MY2021_Rx" SG_ 642 KeyMyKeyTot_No2_Cnt 1;
BA_ "U_U55X_MY2022_Rx" SG_ 642 KeyAdmnTot_No2_Cnt 1;
BA_ "U_CD542_MY2021_Rx" SG_ 642 KeyAdmnTot_No2_Cnt 1;
BA_ "U_T6_MCA_MY2020_Rx" SG_ 642 KeyAdmnTot_No2_Cnt 1;
BA_ "U_P702_MY2021_Rx" SG_ 642 KeyAdmnTot_No2_Cnt 1;
BA_ "U_CD542_MY2021_Rx" SG_ 642 DcChrgSrvcRqd_B_Rq_UB 1;
BA_ "U_T6_MCA_MY2020_Rx" SG_ 642 DcChrgSrvcRqd_B_Rq_UB 1;
BA_ "U_CD542_MY2021_Rx" SG_ 642 DcChrgSrvcRqd_B_Rq 1;
BA_ "U_T6_MCA_MY2020_Rx" SG_ 642 DcChrgSrvcRqd_B_Rq 1;
BA_ "GenSigSendType" SG_ 642 DcChrgSrvcRqd_B_Rq 3;
BA_ "U_U55X_MY2022_Rx" SG_ 642 PaakMyKeySearch_D_Stat 1;
BA_ "U_CD542_MY2021_Rx" SG_ 642 PaakMyKeySearch_D_Stat 1;
BA_ "U_T6_MCA_MY2020_Rx" SG_ 642 PaakMyKeySearch_D_Stat 1;
BA_ "U_P702_MY2021_Rx" SG_ 642 PaakMyKeySearch_D_Stat 1;
BA_ "GenSigSendType" SG_ 642 PaakMyKeySearch_D_Stat 3;
BA_ "U_CD542_MY2021_Rx" SG_ 642 GrdAsstActv_B_Stat_UB 1;
BA_ "U_CD542_MY2021_Rx" SG_ 642 GrdAsstActv_B_Stat 1;
BA_ "GenSigSendType" SG_ 642 GrdAsstActv_B_Stat 3;
BA_ "U_CD542_MY2021_Rx" SG_ 642 TrlrAidTrlrId_No_Rq_UB 1;
BA_ "U_U55X_MY2022_Rx" SG_ 642 TrlrAidTrlrId_No_Rq_UB 1;
BA_ "U_T6_MCA_MY2020_Rx" SG_ 642 TrlrAidTrlrId_No_Rq_UB 1;
BA_ "U_CD542_MY2021_Rx" SG_ 642 TrlrAidTrlrId_No_Rq 1;
BA_ "U_U55X_MY2022_Rx" SG_ 642 TrlrAidTrlrId_No_Rq 1;
BA_ "U_T6_MCA_MY2020_Rx" SG_ 642 TrlrAidTrlrId_No_Rq 1;
BA_ "GenSigSendType" SG_ 642 TrlrAidTrlrId_No_Rq 3;
BA_ "U_U55X_MY2022_Rx" SG_ 893 RngPerChrgAvg_L2_Dsply_UB 1;
BA_ "U_CD542_MY2021_Rx" SG_ 893 RngPerChrgAvg_L2_Dsply_UB 1;
BA_ "U_CD542_MY2021_Rx" SG_ 893 RngImpctClim_L_Dsply_UB 1;
BA_ "U_T6_MCA_MY2020_Rx" SG_ 893 RngImpctClim_L_Dsply_UB 1;
BA_ "U_CD542_MY2021_Rx" SG_ 893 RngImpctDrv_L_Dsply_UB 1;
BA_ "U_T6_MCA_MY2020_Rx" SG_ 893 RngImpctDrv_L_Dsply_UB 1;
BA_ "U_CD542_MY2021_Rx" SG_ 893 RngImpctDrv_L_Dsply 1;
BA_ "U_T6_MCA_MY2020_Rx" SG_ 893 RngImpctDrv_L_Dsply 1;
BA_ "GenSigStartValueInteger" SG_ 893 RngImpctDrv_L_Dsply 255;
BA_ "U_CD542_MY2021_Rx" SG_ 893 RngImpctClim_L_Dsply 1;
BA_ "U_T6_MCA_MY2020_Rx" SG_ 893 RngImpctClim_L_Dsply 1;
BA_ "GenSigStartValueInteger" SG_ 893 RngImpctClim_L_Dsply 255;
BA_ "U_CD542_MY2021_Rx" SG_ 893 VehElEffAvg_No_Dsply_UB 1;
BA_ "U_U55X_MY2022_Rx" SG_ 893 VehElEffAvg_No_Dsply_UB 1;
BA_ "U_T6_MCA_MY2020_Rx" SG_ 893 VehElEffAvg_No_Dsply_UB 1;
BA_ "U_CD542_MY2021_Rx" SG_ 893 VehElEffAvg_No_Dsply 1;
BA_ "U_U55X_MY2022_Rx" SG_ 893 VehElEffAvg_No_Dsply 1;
BA_ "U_T6_MCA_MY2020_Rx" SG_ 893 VehElEffAvg_No_Dsply 1;
BA_ "GenSigStartValue" SG_ 893 VehElEffAvg_No_Dsply 126;
BA_ "GenSigStartValueInteger" SG_ 893 VehElEffAvg_No_Dsply 126;
BA_ "U_U55X_MY2022_Rx" SG_ 893 RngPerChrgAvg_L2_Dsply 1;
BA_ "U_CD542_MY2021_Rx" SG_ 893 RngPerChrgAvg_L2_Dsply 1;
BA_ "GenSigStartValue" SG_ 893 RngPerChrgAvg_L2_Dsply 8190;
BA_ "GenSigStartValueInteger" SG_ 893 RngPerChrgAvg_L2_Dsply 4094;
BA_ "GenSigStartValue" SG_ 893 TrnAout2_W_ActlUnfilt 65534;
BA_ "GenSigStartValueInteger" SG_ 893 TrnAout2_W_ActlUnfilt 65534;
BA_ "U_U55X_MY2022_Tx" SG_ 500 Dsp_SourceSetTrack_Rq 1;
BA_ "U_CD542_MY2021_Tx" SG_ 500 Dsp_SourceSetTrack_Rq 1;
BA_ "U_T6_MCA_MY2020_Tx" SG_ 500 Dsp_SourceSetTrack_Rq 1;
BA_ "U_P702_MY2021_Tx" SG_ 500 Dsp_SourceSetTrack_Rq 1;
BA_ "U_U55X_MY2022_Rx" SG_ 500 Dsp_SourceSetTrack_Rq 1;
BA_ "U_CD542_MY2021_Rx" SG_ 500 Dsp_SourceSetTrack_Rq 1;
BA_ "U_T6_MCA_MY2020_Rx" SG_ 500 Dsp_SourceSetTrack_Rq 1;
BA_ "U_P702_MY2021_Rx" SG_ 500 Dsp_SourceSetTrack_Rq 1;
BA_ "U_U55X_MY2022_Tx" SG_ 500 Dsp_ItemNameLength_Rq 1;
BA_ "U_CD542_MY2021_Tx" SG_ 500 Dsp_ItemNameLength_Rq 1;
BA_ "U_T6_MCA_MY2020_Tx" SG_ 500 Dsp_ItemNameLength_Rq 1;
BA_ "U_P702_MY2021_Tx" SG_ 500 Dsp_ItemNameLength_Rq 1;
BA_ "U_U55X_MY2022_Rx" SG_ 500 Dsp_ItemNameLength_Rq 1;
BA_ "U_CD542_MY2021_Rx" SG_ 500 Dsp_ItemNameLength_Rq 1;
BA_ "U_T6_MCA_MY2020_Rx" SG_ 500 Dsp_ItemNameLength_Rq 1;
BA_ "U_P702_MY2021_Rx" SG_ 500 Dsp_ItemNameLength_Rq 1;
BA_ "U_U55X_MY2022_Tx" SG_ 500 Dsp_GetCDTOCDData_Rq 1;
BA_ "U_CD542_MY2021_Tx" SG_ 500 Dsp_GetCDTOCDData_Rq 1;
BA_ "U_T6_MCA_MY2020_Tx" SG_ 500 Dsp_GetCDTOCDData_Rq 1;
BA_ "U_P702_MY2021_Tx" SG_ 500 Dsp_GetCDTOCDData_Rq 1;
BA_ "U_U55X_MY2022_Rx" SG_ 500 Dsp_GetCDTOCDData_Rq 1;
BA_ "U_CD542_MY2021_Rx" SG_ 500 Dsp_GetCDTOCDData_Rq 1;
BA_ "U_T6_MCA_MY2020_Rx" SG_ 500 Dsp_GetCDTOCDData_Rq 1;
BA_ "U_P702_MY2021_Rx" SG_ 500 Dsp_GetCDTOCDData_Rq 1;
BA_ "GenSigSendType" SG_ 500 Dsp_GetCDTOCDData_Rq 3;
BA_ "U_U55X_MY2022_Tx" SG_ 500 Dsp_FolderNumber_Rq 1;
BA_ "U_CD542_MY2021_Tx" SG_ 500 Dsp_FolderNumber_Rq 1;
BA_ "U_T6_MCA_MY2020_Tx" SG_ 500 Dsp_FolderNumber_Rq 1;
BA_ "U_P702_MY2021_Tx" SG_ 500 Dsp_FolderNumber_Rq 1;
BA_ "U_U55X_MY2022_Rx" SG_ 500 Dsp_FolderNumber_Rq 1;
BA_ "U_CD542_MY2021_Rx" SG_ 500 Dsp_FolderNumber_Rq 1;
BA_ "U_T6_MCA_MY2020_Rx" SG_ 500 Dsp_FolderNumber_Rq 1;
BA_ "U_P702_MY2021_Rx" SG_ 500 Dsp_FolderNumber_Rq 1;
BA_ "U_U55X_MY2022_Tx" SG_ 500 Dsp_CutItem_Rq 1;
BA_ "U_CD542_MY2021_Tx" SG_ 500 Dsp_CutItem_Rq 1;
BA_ "U_T6_MCA_MY2020_Tx" SG_ 500 Dsp_CutItem_Rq 1;
BA_ "U_P702_MY2021_Tx" SG_ 500 Dsp_CutItem_Rq 1;
BA_ "U_U55X_MY2022_Rx" SG_ 500 Dsp_CutItem_Rq 1;
BA_ "U_CD542_MY2021_Rx" SG_ 500 Dsp_CutItem_Rq 1;
BA_ "U_T6_MCA_MY2020_Rx" SG_ 500 Dsp_CutItem_Rq 1;
BA_ "U_P702_MY2021_Rx" SG_ 500 Dsp_CutItem_Rq 1;
BA_ "U_U55X_MY2022_Tx" SG_ 500 Dsp_AudioSourceSel_Rq 1;
BA_ "U_CD542_MY2021_Tx" SG_ 500 Dsp_AudioSourceSel_Rq 1;
BA_ "U_T6_MCA_MY2020_Tx" SG_ 500 Dsp_AudioSourceSel_Rq 1;
BA_ "U_P702_MY2021_Tx" SG_ 500 Dsp_AudioSourceSel_Rq 1;
BA_ "U_U55X_MY2022_Rx" SG_ 500 Dsp_AudioSourceSel_Rq 1;
BA_ "U_CD542_MY2021_Rx" SG_ 500 Dsp_AudioSourceSel_Rq 1;
BA_ "U_T6_MCA_MY2020_Rx" SG_ 500 Dsp_AudioSourceSel_Rq 1;
BA_ "U_P702_MY2021_Rx" SG_ 500 Dsp_AudioSourceSel_Rq 1;
BA_ "GenSigSendType" SG_ 500 Dsp_AudioSourceSel_Rq 3;
BA_ "U_U55X_MY2022_Tx" SG_ 503 Dsp_PlayFrstTrInFldr_Rq 1;
BA_ "U_CD542_MY2021_Tx" SG_ 503 Dsp_PlayFrstTrInFldr_Rq 1;
BA_ "U_T6_MCA_MY2020_Tx" SG_ 503 Dsp_PlayFrstTrInFldr_Rq 1;
BA_ "U_P702_MY2021_Tx" SG_ 503 Dsp_PlayFrstTrInFldr_Rq 1;
BA_ "U_U55X_MY2022_Rx" SG_ 503 Dsp_PlayFrstTrInFldr_Rq 1;
BA_ "U_CD542_MY2021_Rx" SG_ 503 Dsp_PlayFrstTrInFldr_Rq 1;
BA_ "U_T6_MCA_MY2020_Rx" SG_ 503 Dsp_PlayFrstTrInFldr_Rq 1;
BA_ "U_P702_MY2021_Rx" SG_ 503 Dsp_PlayFrstTrInFldr_Rq 1;
BA_ "U_U55X_MY2022_Tx" SG_ 503 Dsp_ItemIndex_Rq 1;
BA_ "U_CD542_MY2021_Tx" SG_ 503 Dsp_ItemIndex_Rq 1;
BA_ "U_T6_MCA_MY2020_Tx" SG_ 503 Dsp_ItemIndex_Rq 1;
BA_ "U_P702_MY2021_Tx" SG_ 503 Dsp_ItemIndex_Rq 1;
BA_ "U_U55X_MY2022_Rx" SG_ 503 Dsp_ItemIndex_Rq 1;
BA_ "U_CD542_MY2021_Rx" SG_ 503 Dsp_ItemIndex_Rq 1;
BA_ "U_T6_MCA_MY2020_Rx" SG_ 503 Dsp_ItemIndex_Rq 1;
BA_ "U_P702_MY2021_Rx" SG_ 503 Dsp_ItemIndex_Rq 1;
BA_ "U_U55X_MY2022_Tx" SG_ 503 Dsp_FolderNumber3_Rq 1;
BA_ "U_CD542_MY2021_Tx" SG_ 503 Dsp_FolderNumber3_Rq 1;
BA_ "U_T6_MCA_MY2020_Tx" SG_ 503 Dsp_FolderNumber3_Rq 1;
BA_ "U_P702_MY2021_Tx" SG_ 503 Dsp_FolderNumber3_Rq 1;
BA_ "U_U55X_MY2022_Rx" SG_ 503 Dsp_FolderNumber3_Rq 1;
BA_ "U_CD542_MY2021_Rx" SG_ 503 Dsp_FolderNumber3_Rq 1;
BA_ "U_T6_MCA_MY2020_Rx" SG_ 503 Dsp_FolderNumber3_Rq 1;
BA_ "U_P702_MY2021_Rx" SG_ 503 Dsp_FolderNumber3_Rq 1;
BA_ "U_U55X_MY2022_Tx" SG_ 503 Dsp_AudioSourceSel3_Rq 1;
BA_ "U_CD542_MY2021_Tx" SG_ 503 Dsp_AudioSourceSel3_Rq 1;
BA_ "U_T6_MCA_MY2020_Tx" SG_ 503 Dsp_AudioSourceSel3_Rq 1;
BA_ "U_P702_MY2021_Tx" SG_ 503 Dsp_AudioSourceSel3_Rq 1;
BA_ "U_U55X_MY2022_Rx" SG_ 503 Dsp_AudioSourceSel3_Rq 1;
BA_ "U_CD542_MY2021_Rx" SG_ 503 Dsp_AudioSourceSel3_Rq 1;
BA_ "U_T6_MCA_MY2020_Rx" SG_ 503 Dsp_AudioSourceSel3_Rq 1;
BA_ "U_P702_MY2021_Rx" SG_ 503 Dsp_AudioSourceSel3_Rq 1;
BA_ "GenSigSendType" SG_ 503 Dsp_AudioSourceSel3_Rq 3;
BA_ "U_U55X_MY2022_Tx" SG_ 412 LBC2_StartItemInd 1;
BA_ "U_CD542_MY2021_Tx" SG_ 412 LBC2_StartItemInd 1;
BA_ "U_T6_MCA_MY2020_Tx" SG_ 412 LBC2_StartItemInd 1;
BA_ "U_P702_MY2021_Tx" SG_ 412 LBC2_StartItemInd 1;
BA_ "U_U55X_MY2022_Rx" SG_ 412 LBC2_StartItemInd 1;
BA_ "U_CD542_MY2021_Rx" SG_ 412 LBC2_StartItemInd 1;
BA_ "U_T6_MCA_MY2020_Rx" SG_ 412 LBC2_StartItemInd 1;
BA_ "U_P702_MY2021_Rx" SG_ 412 LBC2_StartItemInd 1;
BA_ "U_U55X_MY2022_Tx" SG_ 412 LBC2_SetListServ 1;
BA_ "U_CD542_MY2021_Tx" SG_ 412 LBC2_SetListServ 1;
BA_ "U_T6_MCA_MY2020_Tx" SG_ 412 LBC2_SetListServ 1;
BA_ "U_P702_MY2021_Tx" SG_ 412 LBC2_SetListServ 1;
BA_ "U_U55X_MY2022_Rx" SG_ 412 LBC2_SetListServ 1;
BA_ "U_CD542_MY2021_Rx" SG_ 412 LBC2_SetListServ 1;
BA_ "U_T6_MCA_MY2020_Rx" SG_ 412 LBC2_SetListServ 1;
BA_ "U_P702_MY2021_Rx" SG_ 412 LBC2_SetListServ 1;
BA_ "U_U55X_MY2022_Tx" SG_ 412 LBC2_Opcode 1;
BA_ "U_CD542_MY2021_Tx" SG_ 412 LBC2_Opcode 1;
BA_ "U_T6_MCA_MY2020_Tx" SG_ 412 LBC2_Opcode 1;
BA_ "U_P702_MY2021_Tx" SG_ 412 LBC2_Opcode 1;
BA_ "U_U55X_MY2022_Rx" SG_ 412 LBC2_Opcode 1;
BA_ "U_CD542_MY2021_Rx" SG_ 412 LBC2_Opcode 1;
BA_ "U_T6_MCA_MY2020_Rx" SG_ 412 LBC2_Opcode 1;
BA_ "U_P702_MY2021_Rx" SG_ 412 LBC2_Opcode 1;
BA_ "GenSigSendType" SG_ 412 LBC2_Opcode 3;
BA_ "U_U55X_MY2022_Tx" SG_ 412 LBC2_NbrOfItems 1;
BA_ "U_CD542_MY2021_Tx" SG_ 412 LBC2_NbrOfItems 1;
BA_ "U_T6_MCA_MY2020_Tx" SG_ 412 LBC2_NbrOfItems 1;
BA_ "U_P702_MY2021_Tx" SG_ 412 LBC2_NbrOfItems 1;
BA_ "U_U55X_MY2022_Rx" SG_ 412 LBC2_NbrOfItems 1;
BA_ "U_CD542_MY2021_Rx" SG_ 412 LBC2_NbrOfItems 1;
BA_ "U_T6_MCA_MY2020_Rx" SG_ 412 LBC2_NbrOfItems 1;
BA_ "U_P702_MY2021_Rx" SG_ 412 LBC2_NbrOfItems 1;
BA_ "U_U55X_MY2022_Tx" SG_ 412 LBC2_ItemIndex 1;
BA_ "U_CD542_MY2021_Tx" SG_ 412 LBC2_ItemIndex 1;
BA_ "U_T6_MCA_MY2020_Tx" SG_ 412 LBC2_ItemIndex 1;
BA_ "U_P702_MY2021_Tx" SG_ 412 LBC2_ItemIndex 1;
BA_ "U_U55X_MY2022_Rx" SG_ 412 LBC2_ItemIndex 1;
BA_ "U_CD542_MY2021_Rx" SG_ 412 LBC2_ItemIndex 1;
BA_ "U_T6_MCA_MY2020_Rx" SG_ 412 LBC2_ItemIndex 1;
BA_ "U_U55X_MY2022_Tx" SG_ 412 LBC2_ActiveListID 1;
BA_ "U_CD542_MY2021_Tx" SG_ 412 LBC2_ActiveListID 1;
BA_ "U_T6_MCA_MY2020_Tx" SG_ 412 LBC2_ActiveListID 1;
BA_ "U_P702_MY2021_Tx" SG_ 412 LBC2_ActiveListID 1;
BA_ "U_U55X_MY2022_Rx" SG_ 412 LBC2_ActiveListID 1;
BA_ "U_CD542_MY2021_Rx" SG_ 412 LBC2_ActiveListID 1;
BA_ "U_T6_MCA_MY2020_Rx" SG_ 412 LBC2_ActiveListID 1;
BA_ "U_P702_MY2021_Rx" SG_ 412 LBC2_ActiveListID 1;
BA_ "U_U55X_MY2022_Tx" SG_ 493 Dsp_StatLiScanCancel_Rq 1;
BA_ "U_CD542_MY2021_Tx" SG_ 493 Dsp_StatLiScanCancel_Rq 1;
BA_ "U_T6_MCA_MY2020_Tx" SG_ 493 Dsp_StatLiScanCancel_Rq 1;
BA_ "U_P702_MY2021_Tx" SG_ 493 Dsp_StatLiScanCancel_Rq 1;
BA_ "U_U55X_MY2022_Rx" SG_ 493 Dsp_StatLiScanCancel_Rq 1;
BA_ "U_CD542_MY2021_Rx" SG_ 493 Dsp_StatLiScanCancel_Rq 1;
BA_ "U_T6_MCA_MY2020_Rx" SG_ 493 Dsp_StatLiScanCancel_Rq 1;
BA_ "U_P702_MY2021_Rx" SG_ 493 Dsp_StatLiScanCancel_Rq 1;
BA_ "GenSigSendType" SG_ 493 Dsp_StatLiScanCancel_Rq 3;
BA_ "U_U55X_MY2022_Tx" SG_ 493 Dsp_StationList_Rq 1;
BA_ "U_CD542_MY2021_Tx" SG_ 493 Dsp_StationList_Rq 1;
BA_ "U_T6_MCA_MY2020_Tx" SG_ 493 Dsp_StationList_Rq 1;
BA_ "U_P702_MY2021_Tx" SG_ 493 Dsp_StationList_Rq 1;
BA_ "U_U55X_MY2022_Rx" SG_ 493 Dsp_StationList_Rq 1;
BA_ "U_CD542_MY2021_Rx" SG_ 493 Dsp_StationList_Rq 1;
BA_ "U_T6_MCA_MY2020_Rx" SG_ 493 Dsp_StationList_Rq 1;
BA_ "U_P702_MY2021_Rx" SG_ 493 Dsp_StationList_Rq 1;
BA_ "GenSigSendType" SG_ 493 Dsp_StationList_Rq 3;
BA_ "U_U55X_MY2022_Tx" SG_ 493 Dsp_StartIndex3_Rq 1;
BA_ "U_CD542_MY2021_Tx" SG_ 493 Dsp_StartIndex3_Rq 1;
BA_ "U_T6_MCA_MY2020_Tx" SG_ 493 Dsp_StartIndex3_Rq 1;
BA_ "U_P702_MY2021_Tx" SG_ 493 Dsp_StartIndex3_Rq 1;
BA_ "U_U55X_MY2022_Rx" SG_ 493 Dsp_StartIndex3_Rq 1;
BA_ "U_CD542_MY2021_Rx" SG_ 493 Dsp_StartIndex3_Rq 1;
BA_ "U_T6_MCA_MY2020_Rx" SG_ 493 Dsp_StartIndex3_Rq 1;
BA_ "U_P702_MY2021_Rx" SG_ 493 Dsp_StartIndex3_Rq 1;
BA_ "U_U55X_MY2022_Tx" SG_ 493 Dsp_RefreshFlag 1;
BA_ "U_CD542_MY2021_Tx" SG_ 493 Dsp_RefreshFlag 1;
BA_ "U_T6_MCA_MY2020_Tx" SG_ 493 Dsp_RefreshFlag 1;
BA_ "U_P702_MY2021_Tx" SG_ 493 Dsp_RefreshFlag 1;
BA_ "U_U55X_MY2022_Rx" SG_ 493 Dsp_RefreshFlag 1;
BA_ "U_CD542_MY2021_Rx" SG_ 493 Dsp_RefreshFlag 1;
BA_ "U_T6_MCA_MY2020_Rx" SG_ 493 Dsp_RefreshFlag 1;
BA_ "U_P702_MY2021_Rx" SG_ 493 Dsp_RefreshFlag 1;
BA_ "U_U55X_MY2022_Tx" SG_ 493 Dsp_PTYCode_Rq 1;
BA_ "U_CD542_MY2021_Tx" SG_ 493 Dsp_PTYCode_Rq 1;
BA_ "U_T6_MCA_MY2020_Tx" SG_ 493 Dsp_PTYCode_Rq 1;
BA_ "U_P702_MY2021_Tx" SG_ 493 Dsp_PTYCode_Rq 1;
BA_ "U_U55X_MY2022_Rx" SG_ 493 Dsp_PTYCode_Rq 1;
BA_ "U_CD542_MY2021_Rx" SG_ 493 Dsp_PTYCode_Rq 1;
BA_ "U_T6_MCA_MY2020_Rx" SG_ 493 Dsp_PTYCode_Rq 1;
BA_ "U_P702_MY2021_Rx" SG_ 493 Dsp_PTYCode_Rq 1;
BA_ "U_U55X_MY2022_Tx" SG_ 493 Dsp_ListSize_Rq 1;
BA_ "U_CD542_MY2021_Tx" SG_ 493 Dsp_ListSize_Rq 1;
BA_ "U_T6_MCA_MY2020_Tx" SG_ 493 Dsp_ListSize_Rq 1;
BA_ "U_P702_MY2021_Tx" SG_ 493 Dsp_ListSize_Rq 1;
BA_ "U_U55X_MY2022_Rx" SG_ 493 Dsp_ListSize_Rq 1;
BA_ "U_CD542_MY2021_Rx" SG_ 493 Dsp_ListSize_Rq 1;
BA_ "U_T6_MCA_MY2020_Rx" SG_ 493 Dsp_ListSize_Rq 1;
BA_ "U_P702_MY2021_Rx" SG_ 493 Dsp_ListSize_Rq 1;
BA_ "U_U55X_MY2022_Tx" SG_ 493 Dsp_AFJump_Rq 1;
BA_ "U_CD542_MY2021_Tx" SG_ 493 Dsp_AFJump_Rq 1;
BA_ "U_T6_MCA_MY2020_Tx" SG_ 493 Dsp_AFJump_Rq 1;
BA_ "U_P702_MY2021_Tx" SG_ 493 Dsp_AFJump_Rq 1;
BA_ "U_U55X_MY2022_Rx" SG_ 493 Dsp_AFJump_Rq 1;
BA_ "U_CD542_MY2021_Rx" SG_ 493 Dsp_AFJump_Rq 1;
BA_ "U_T6_MCA_MY2020_Rx" SG_ 493 Dsp_AFJump_Rq 1;
BA_ "U_P702_MY2021_Rx" SG_ 493 Dsp_AFJump_Rq 1;
BA_ "GenSigSendType" SG_ 493 Dsp_AFJump_Rq 3;
BA_ "U_U55X_MY2022_Tx" SG_ 511 SdarsAudioRtng_D_Rq 1;
BA_ "U_CD542_MY2021_Tx" SG_ 511 SdarsAudioRtng_D_Rq 1;
BA_ "U_U55X_MY2022_Rx" SG_ 511 SdarsAudioRtng_D_Rq 1;
BA_ "U_T6_MCA_MY2020_Rx" SG_ 511 SdarsAudioRtng_D_Rq 1;
BA_ "GenSigSendType" SG_ 511 SdarsAudioRtng_D_Rq 3;
BA_ "U_U55X_MY2022_Tx" SG_ 511 Dsp_TUStartIndex2_Rq 1;
BA_ "U_CD542_MY2021_Tx" SG_ 511 Dsp_TUStartIndex2_Rq 1;
BA_ "U_T6_MCA_MY2020_Tx" SG_ 511 Dsp_TUStartIndex2_Rq 1;
BA_ "U_P702_MY2021_Tx" SG_ 511 Dsp_TUStartIndex2_Rq 1;
BA_ "U_U55X_MY2022_Rx" SG_ 511 Dsp_TUStartIndex2_Rq 1;
BA_ "U_CD542_MY2021_Rx" SG_ 511 Dsp_TUStartIndex2_Rq 1;
BA_ "U_T6_MCA_MY2020_Rx" SG_ 511 Dsp_TUStartIndex2_Rq 1;
BA_ "U_P702_MY2021_Rx" SG_ 511 Dsp_TUStartIndex2_Rq 1;
BA_ "U_U55X_MY2022_Tx" SG_ 511 Dsp_TUPresetArea_Rq 1;
BA_ "U_CD542_MY2021_Tx" SG_ 511 Dsp_TUPresetArea_Rq 1;
BA_ "U_T6_MCA_MY2020_Tx" SG_ 511 Dsp_TUPresetArea_Rq 1;
BA_ "U_P702_MY2021_Tx" SG_ 511 Dsp_TUPresetArea_Rq 1;
BA_ "U_U55X_MY2022_Rx" SG_ 511 Dsp_TUPresetArea_Rq 1;
BA_ "U_CD542_MY2021_Rx" SG_ 511 Dsp_TUPresetArea_Rq 1;
BA_ "U_T6_MCA_MY2020_Rx" SG_ 511 Dsp_TUPresetArea_Rq 1;
BA_ "U_P702_MY2021_Rx" SG_ 511 Dsp_TUPresetArea_Rq 1;
BA_ "GenSigSendType" SG_ 511 Dsp_TUPresetArea_Rq 3;
BA_ "U_U55X_MY2022_Tx" SG_ 511 Dsp_TUNbrOfPresets_Rq 1;
BA_ "U_CD542_MY2021_Tx" SG_ 511 Dsp_TUNbrOfPresets_Rq 1;
BA_ "U_T6_MCA_MY2020_Tx" SG_ 511 Dsp_TUNbrOfPresets_Rq 1;
BA_ "U_P702_MY2021_Tx" SG_ 511 Dsp_TUNbrOfPresets_Rq 1;
BA_ "U_U55X_MY2022_Rx" SG_ 511 Dsp_TUNbrOfPresets_Rq 1;
BA_ "U_CD542_MY2021_Rx" SG_ 511 Dsp_TUNbrOfPresets_Rq 1;
BA_ "U_T6_MCA_MY2020_Rx" SG_ 511 Dsp_TUNbrOfPresets_Rq 1;
BA_ "U_P702_MY2021_Rx" SG_ 511 Dsp_TUNbrOfPresets_Rq 1;
BA_ "U_U55X_MY2022_Tx" SG_ 511 Dsp_SetCurrTUPreset_Rq 1;
BA_ "U_CD542_MY2021_Tx" SG_ 511 Dsp_SetCurrTUPreset_Rq 1;
BA_ "U_T6_MCA_MY2020_Tx" SG_ 511 Dsp_SetCurrTUPreset_Rq 1;
BA_ "U_P702_MY2021_Tx" SG_ 511 Dsp_SetCurrTUPreset_Rq 1;
BA_ "U_U55X_MY2022_Rx" SG_ 511 Dsp_SetCurrTUPreset_Rq 1;
BA_ "U_CD542_MY2021_Rx" SG_ 511 Dsp_SetCurrTUPreset_Rq 1;
BA_ "U_T6_MCA_MY2020_Rx" SG_ 511 Dsp_SetCurrTUPreset_Rq 1;
BA_ "U_P702_MY2021_Rx" SG_ 511 Dsp_SetCurrTUPreset_Rq 1;
BA_ "GenSigSendType" SG_ 511 Dsp_SetCurrTUPreset_Rq 3;
BA_ "U_U55X_MY2022_Tx" SG_ 511 Dsp_SetCurrTUBand_Rq 1;
BA_ "U_CD542_MY2021_Tx" SG_ 511 Dsp_SetCurrTUBand_Rq 1;
BA_ "U_T6_MCA_MY2020_Tx" SG_ 511 Dsp_SetCurrTUBand_Rq 1;
BA_ "U_P702_MY2021_Tx" SG_ 511 Dsp_SetCurrTUBand_Rq 1;
BA_ "U_U55X_MY2022_Rx" SG_ 511 Dsp_SetCurrTUBand_Rq 1;
BA_ "U_CD542_MY2021_Rx" SG_ 511 Dsp_SetCurrTUBand_Rq 1;
BA_ "U_T6_MCA_MY2020_Rx" SG_ 511 Dsp_SetCurrTUBand_Rq 1;
BA_ "U_P702_MY2021_Rx" SG_ 511 Dsp_SetCurrTUBand_Rq 1;
BA_ "GenSigSendType" SG_ 511 Dsp_SetCurrTUBand_Rq 3;
BA_ "U_U55X_MY2022_Tx" SG_ 257 MFD_SetTagMode 1;
BA_ "U_CD542_MY2021_Tx" SG_ 257 MFD_SetTagMode 1;
BA_ "U_T6_MCA_MY2020_Tx" SG_ 257 MFD_SetTagMode 1;
BA_ "U_P702_MY2021_Tx" SG_ 257 MFD_SetTagMode 1;
BA_ "U_U55X_MY2022_Rx" SG_ 257 MFD_SetTagMode 1;
BA_ "U_CD542_MY2021_Rx" SG_ 257 MFD_SetTagMode 1;
BA_ "U_T6_MCA_MY2020_Rx" SG_ 257 MFD_SetTagMode 1;
BA_ "U_P702_MY2021_Rx" SG_ 257 MFD_SetTagMode 1;
BA_ "GenSigSendType" SG_ 257 MFD_SetTagMode 3;
BA_ "U_U55X_MY2022_Tx" SG_ 257 MFD_SetRBDSMode 1;
BA_ "U_CD542_MY2021_Tx" SG_ 257 MFD_SetRBDSMode 1;
BA_ "U_T6_MCA_MY2020_Tx" SG_ 257 MFD_SetRBDSMode 1;
BA_ "U_P702_MY2021_Tx" SG_ 257 MFD_SetRBDSMode 1;
BA_ "U_U55X_MY2022_Rx" SG_ 257 MFD_SetRBDSMode 1;
BA_ "U_CD542_MY2021_Rx" SG_ 257 MFD_SetRBDSMode 1;
BA_ "U_T6_MCA_MY2020_Rx" SG_ 257 MFD_SetRBDSMode 1;
BA_ "U_P702_MY2021_Rx" SG_ 257 MFD_SetRBDSMode 1;
BA_ "GenSigSendType" SG_ 257 MFD_SetRBDSMode 3;
BA_ "U_U55X_MY2022_Tx" SG_ 257 MFD_SetHDModeRq 1;
BA_ "U_CD542_MY2021_Tx" SG_ 257 MFD_SetHDModeRq 1;
BA_ "U_T6_MCA_MY2020_Tx" SG_ 257 MFD_SetHDModeRq 1;
BA_ "U_P702_MY2021_Tx" SG_ 257 MFD_SetHDModeRq 1;
BA_ "U_U55X_MY2022_Rx" SG_ 257 MFD_SetHDModeRq 1;
BA_ "U_CD542_MY2021_Rx" SG_ 257 MFD_SetHDModeRq 1;
BA_ "U_T6_MCA_MY2020_Rx" SG_ 257 MFD_SetHDModeRq 1;
BA_ "U_P702_MY2021_Rx" SG_ 257 MFD_SetHDModeRq 1;
BA_ "GenSigSendType" SG_ 257 MFD_SetHDModeRq 3;
BA_ "U_U55X_MY2022_Tx" SG_ 257 MFD_GetTagInfo 1;
BA_ "U_CD542_MY2021_Tx" SG_ 257 MFD_GetTagInfo 1;
BA_ "U_T6_MCA_MY2020_Tx" SG_ 257 MFD_GetTagInfo 1;
BA_ "U_P702_MY2021_Tx" SG_ 257 MFD_GetTagInfo 1;
BA_ "U_U55X_MY2022_Rx" SG_ 257 MFD_GetTagInfo 1;
BA_ "U_CD542_MY2021_Rx" SG_ 257 MFD_GetTagInfo 1;
BA_ "U_T6_MCA_MY2020_Rx" SG_ 257 MFD_GetTagInfo 1;
BA_ "U_P702_MY2021_Rx" SG_ 257 MFD_GetTagInfo 1;
BA_ "GenSigSendType" SG_ 257 MFD_GetTagInfo 3;
BA_ "U_U55X_MY2022_Tx" SG_ 713 SDARS_RDISP_WORD_Rx 1;
BA_ "U_CD542_MY2021_Tx" SG_ 713 SDARS_RDISP_WORD_Rx 1;
BA_ "U_T6_MCA_MY2020_Tx" SG_ 713 SDARS_RDISP_WORD_Rx 1;
BA_ "U_P702_MY2021_Tx" SG_ 713 SDARS_RDISP_WORD_Rx 1;
BA_ "U_U55X_MY2022_Rx" SG_ 713 SDARS_RDISP_WORD_Rx 1;
BA_ "U_CD542_MY2021_Rx" SG_ 713 SDARS_RDISP_WORD_Rx 1;
BA_ "U_T6_MCA_MY2020_Rx" SG_ 713 SDARS_RDISP_WORD_Rx 1;
BA_ "U_P702_MY2021_Rx" SG_ 713 SDARS_RDISP_WORD_Rx 1;
BA_ "U_CD542_MY2021_Rx" SG_ 382 EngMnfldChrg_Te_Actl 1;
BA_ "U_T6_MCA_MY2020_Rx" SG_ 382 EngMnfldChrg_Te_Actl 1;
BA_ "GenSigStartValue" SG_ 382 EngMnfldChrg_Te_Actl 126;
BA_ "GenSigStartValueInteger" SG_ 382 EngMnfldChrg_Te_Actl 126;
BA_ "U_CD542_MY2021_Rx" SG_ 382 EngInnrClnt_Te_Actl 1;
BA_ "GenSigStartValue" SG_ 382 EngInnrClnt_Te_Actl 126;
BA_ "GenSigStartValueInteger" SG_ 382 EngInnrClnt_Te_Actl 56;
BA_ "U_U55X_MY2022_Rx" SG_ 382 DcacOut2_Pw2_Dsply 1;
BA_ "U_U55X_MY2022_Rx" SG_ 382 DcacOut1_Pw2_Dsply 1;
BA_ "U_CD542_MY2021_Rx" SG_ 877 Rr_Third_Power_Btn_Stt 1;
BA_ "U_T6_MCA_MY2020_Rx" SG_ 877 Rr_Third_Power_Btn_Stt 1;
BA_ "U_P702_MY2021_Rx" SG_ 877 Rr_Third_Power_Btn_Stt 1;
BA_ "U_U55X_MY2022_Rx" SG_ 877 Rr_Third_Power_Btn_Stt 1;
BA_ "GenSigStartValue" SG_ 877 Rr_Third_Power_Btn_Stt 2;
BA_ "GenSigStartValueInteger" SG_ 877 Rr_Third_Power_Btn_Stt 2;
BA_ "U_U55X_MY2022_Rx" SG_ 877 Rr_Third_Floor_Btn_Stt 1;
BA_ "U_CD542_MY2021_Rx" SG_ 877 Rr_Third_Floor_Btn_Stt 1;
BA_ "U_T6_MCA_MY2020_Rx" SG_ 877 Rr_Third_Floor_Btn_Stt 1;
BA_ "U_P702_MY2021_Rx" SG_ 877 Rr_Third_Floor_Btn_Stt 1;
BA_ "GenSigStartValue" SG_ 877 Rr_Third_Floor_Btn_Stt 2;
BA_ "GenSigStartValueInteger" SG_ 877 Rr_Third_Floor_Btn_Stt 2;
BA_ "U_U55X_MY2022_Rx" SG_ 877 Rr_Third_Auto_Btn_Stt 1;
BA_ "U_CD542_MY2021_Rx" SG_ 877 Rr_Third_Auto_Btn_Stt 1;
BA_ "U_T6_MCA_MY2020_Rx" SG_ 877 Rr_Third_Auto_Btn_Stt 1;
BA_ "U_P702_MY2021_Rx" SG_ 877 Rr_Third_Auto_Btn_Stt 1;
BA_ "GenSigStartValue" SG_ 877 Rr_Third_Auto_Btn_Stt 2;
BA_ "GenSigStartValueInteger" SG_ 877 Rr_Third_Auto_Btn_Stt 2;
BA_ "U_U55X_MY2022_Rx" SG_ 877 Rr_Lock_Btn_Stt 1;
BA_ "U_CD542_MY2021_Rx" SG_ 877 Rr_Lock_Btn_Stt 1;
BA_ "U_T6_MCA_MY2020_Rx" SG_ 877 Rr_Lock_Btn_Stt 1;
BA_ "U_P702_MY2021_Rx" SG_ 877 Rr_Lock_Btn_Stt 1;
BA_ "GenSigStartValue" SG_ 877 Rr_Lock_Btn_Stt 2;
BA_ "GenSigStartValueInteger" SG_ 877 Rr_Lock_Btn_Stt 2;
BA_ "U_U55X_MY2022_Rx" SG_ 877 Rr_RHS_Blower_Indicate 1;
BA_ "U_CD542_MY2021_Rx" SG_ 877 Rr_RHS_Blower_Indicate 1;
BA_ "U_T6_MCA_MY2020_Rx" SG_ 877 Rr_RHS_Blower_Indicate 1;
BA_ "GenSigStartValue" SG_ 877 Rr_RHS_Blower_Indicate 15;
BA_ "GenSigStartValueInteger" SG_ 877 Rr_RHS_Blower_Indicate 15;
BA_ "U_U55X_MY2022_Rx" SG_ 877 Rr_Third_Panel_Btn_Stt 1;
BA_ "U_CD542_MY2021_Rx" SG_ 877 Rr_Third_Panel_Btn_Stt 1;
BA_ "U_T6_MCA_MY2020_Rx" SG_ 877 Rr_Third_Panel_Btn_Stt 1;
BA_ "U_P702_MY2021_Rx" SG_ 877 Rr_Third_Panel_Btn_Stt 1;
BA_ "GenSigStartValue" SG_ 877 Rr_Third_Panel_Btn_Stt 2;
BA_ "GenSigStartValueInteger" SG_ 877 Rr_Third_Panel_Btn_Stt 2;
BA_ "U_U55X_MY2022_Rx" SG_ 877 Rr_Synch_Btn_Stt 1;
BA_ "U_CD542_MY2021_Rx" SG_ 877 Rr_Synch_Btn_Stt 1;
BA_ "U_T6_MCA_MY2020_Rx" SG_ 877 Rr_Synch_Btn_Stt 1;
BA_ "U_P702_MY2021_Rx" SG_ 877 Rr_Synch_Btn_Stt 1;
BA_ "GenSigStartValue" SG_ 877 Rr_Synch_Btn_Stt 2;
BA_ "GenSigStartValueInteger" SG_ 877 Rr_Synch_Btn_Stt 2;
BA_ "U_CD542_MY2021_Rx" SG_ 877 AAR_Btn_Stt 1;
BA_ "U_U55X_MY2022_Rx" SG_ 877 AAR_Btn_Stt 1;
BA_ "U_T6_MCA_MY2020_Rx" SG_ 877 AAR_Btn_Stt 1;
BA_ "U_P702_MY2021_Rx" SG_ 877 AAR_Btn_Stt 1;
BA_ "GenSigStartValue" SG_ 877 AAR_Btn_Stt 2;
BA_ "GenSigStartValueInteger" SG_ 877 AAR_Btn_Stt 2;
BA_ "U_U55X_MY2022_Rx" SG_ 877 Heat_Btn_Stt 1;
BA_ "U_CD542_MY2021_Rx" SG_ 877 Heat_Btn_Stt 1;
BA_ "U_T6_MCA_MY2020_Rx" SG_ 877 Heat_Btn_Stt 1;
BA_ "U_P702_MY2021_Rx" SG_ 877 Heat_Btn_Stt 1;
BA_ "GenSigStartValue" SG_ 877 Heat_Btn_Stt 2;
BA_ "GenSigStartValueInteger" SG_ 877 Heat_Btn_Stt 2;
BA_ "U_U55X_MY2022_Rx" SG_ 592 RFA_BLEM_APIM_Tx 1;
BA_ "U_CD542_MY2021_Rx" SG_ 592 RFA_BLEM_APIM_Tx 1;
BA_ "U_T6_MCA_MY2020_Rx" SG_ 592 RFA_BLEM_APIM_Tx 1;
BA_ "U_P702_MY2021_Rx" SG_ 592 RFA_BLEM_APIM_Tx 1;
BA_ "U_T6_MCA_MY2020_Tx" SG_ 600 APIM_RFA_BLEM_Tx 1;
BA_ "U_P702_MY2021_Tx" SG_ 600 APIM_RFA_BLEM_Tx 1;
BA_ "U_U55X_MY2022_Tx" SG_ 600 APIM_RFA_BLEM_Tx 1;
BA_ "U_CD542_MY2021_Tx" SG_ 600 APIM_RFA_BLEM_Tx 1;
BA_ "U_U55X_MY2022_Tx" SG_ 708 TMCSrvr_TMCClnt_WORD_Tx 1;
BA_ "U_CD542_MY2021_Tx" SG_ 708 TMCSrvr_TMCClnt_WORD_Tx 1;
BA_ "U_T6_MCA_MY2020_Tx" SG_ 708 TMCSrvr_TMCClnt_WORD_Tx 1;
BA_ "U_P702_MY2021_Tx" SG_ 708 TMCSrvr_TMCClnt_WORD_Tx 1;
BA_ "U_U55X_MY2022_Rx" SG_ 708 TMCSrvr_TMCClnt_WORD_Tx 1;
BA_ "U_CD542_MY2021_Rx" SG_ 708 TMCSrvr_TMCClnt_WORD_Tx 1;
BA_ "U_T6_MCA_MY2020_Rx" SG_ 708 TMCSrvr_TMCClnt_WORD_Tx 1;
BA_ "U_P702_MY2021_Rx" SG_ 708 TMCSrvr_TMCClnt_WORD_Tx 1;
BA_ "U_U55X_MY2022_Tx" SG_ 414 LBS2_ListStatus 1;
BA_ "U_CD542_MY2021_Tx" SG_ 414 LBS2_ListStatus 1;
BA_ "U_T6_MCA_MY2020_Tx" SG_ 414 LBS2_ListStatus 1;
BA_ "U_P702_MY2021_Tx" SG_ 414 LBS2_ListStatus 1;
BA_ "U_P702_MY2021_Rx" SG_ 414 LBS2_ListStatus 1;
BA_ "U_CD542_MY2021_Rx" SG_ 414 LBS2_ListStatus 1;
BA_ "U_T6_MCA_MY2020_Rx" SG_ 414 LBS2_ListStatus 1;
BA_ "U_U55X_MY2022_Rx" SG_ 414 LBS2_ListStatus 1;
BA_ "GenSigSendType" SG_ 414 LBS2_ListStatus 3;
BA_ "U_U55X_MY2022_Tx" SG_ 414 LBS2_ParentID 1;
BA_ "U_CD542_MY2021_Tx" SG_ 414 LBS2_ParentID 1;
BA_ "U_T6_MCA_MY2020_Tx" SG_ 414 LBS2_ParentID 1;
BA_ "U_P702_MY2021_Tx" SG_ 414 LBS2_ParentID 1;
BA_ "U_P702_MY2021_Rx" SG_ 414 LBS2_ParentID 1;
BA_ "U_CD542_MY2021_Rx" SG_ 414 LBS2_ParentID 1;
BA_ "U_T6_MCA_MY2020_Rx" SG_ 414 LBS2_ParentID 1;
BA_ "U_U55X_MY2022_Rx" SG_ 414 LBS2_ParentID 1;
BA_ "U_U55X_MY2022_Tx" SG_ 414 LBS2_ListServer 1;
BA_ "U_CD542_MY2021_Tx" SG_ 414 LBS2_ListServer 1;
BA_ "U_T6_MCA_MY2020_Tx" SG_ 414 LBS2_ListServer 1;
BA_ "U_P702_MY2021_Tx" SG_ 414 LBS2_ListServer 1;
BA_ "U_P702_MY2021_Rx" SG_ 414 LBS2_ListServer 1;
BA_ "U_CD542_MY2021_Rx" SG_ 414 LBS2_ListServer 1;
BA_ "U_T6_MCA_MY2020_Rx" SG_ 414 LBS2_ListServer 1;
BA_ "U_U55X_MY2022_Rx" SG_ 414 LBS2_ListServer 1;
BA_ "U_U55X_MY2022_Tx" SG_ 414 LBS2_ListID 1;
BA_ "U_CD542_MY2021_Tx" SG_ 414 LBS2_ListID 1;
BA_ "U_T6_MCA_MY2020_Tx" SG_ 414 LBS2_ListID 1;
BA_ "U_P702_MY2021_Tx" SG_ 414 LBS2_ListID 1;
BA_ "U_P702_MY2021_Rx" SG_ 414 LBS2_ListID 1;
BA_ "U_CD542_MY2021_Rx" SG_ 414 LBS2_ListID 1;
BA_ "U_T6_MCA_MY2020_Rx" SG_ 414 LBS2_ListID 1;
BA_ "U_U55X_MY2022_Rx" SG_ 414 LBS2_ListID 1;
BA_ "U_U55X_MY2022_Tx" SG_ 414 LBS2_EntryIndex 1;
BA_ "U_CD542_MY2021_Tx" SG_ 414 LBS2_EntryIndex 1;
BA_ "U_T6_MCA_MY2020_Tx" SG_ 414 LBS2_EntryIndex 1;
BA_ "U_P702_MY2021_Tx" SG_ 414 LBS2_EntryIndex 1;
BA_ "U_P702_MY2021_Rx" SG_ 414 LBS2_EntryIndex 1;
BA_ "U_CD542_MY2021_Rx" SG_ 414 LBS2_EntryIndex 1;
BA_ "U_T6_MCA_MY2020_Rx" SG_ 414 LBS2_EntryIndex 1;
BA_ "U_U55X_MY2022_Rx" SG_ 414 LBS2_EntryIndex 1;
BA_ "U_CD542_MY2021_Tx" SG_ 1239 StabBarCnnctLamp_D_Cstm 1;
BA_ "ECGUsedTxSignal" SG_ 1239 StabBarCnnctLamp_D_Cstm 1;
BA_ "GenSigSendType" SG_ 1239 StabBarCnnctLamp_D_Cstm 3;
BA_ "U_CD542_MY2021_Tx" SG_ 1239 SelDrvMdeCstmLamp_D_Rq 1;
BA_ "ECGUsedTxSignal" SG_ 1239 SelDrvMdeCstmLamp_D_Rq 1;
BA_ "GenSigSendType" SG_ 1239 SelDrvMdeCstmLamp_D_Rq 3;
BA_ "U_CD542_MY2021_Tx" SG_ 1239 SelDrvMdeCstm_D_RqDrv 1;
BA_ "ECGUsedTxSignal" SG_ 1239 SelDrvMdeCstm_D_RqDrv 1;
BA_ "GenSigSendType" SG_ 1239 SelDrvMdeCstm_D_RqDrv 3;
BA_ "U_CD542_MY2021_Tx" SG_ 1239 IndvMdeSuspCstm_No_Rq 1;
BA_ "ECGUsedTxSignal" SG_ 1239 IndvMdeSuspCstm_No_Rq 1;
BA_ "GenSigSendType" SG_ 1239 IndvMdeSuspCstm_No_Rq 3;
BA_ "GenSigStartValue" SG_ 1239 IndvMdeSuspCstm_No_Rq 15;
BA_ "U_CD542_MY2021_Tx" SG_ 1239 IndvMdeSteCstm_No_Rq 1;
BA_ "ECGUsedTxSignal" SG_ 1239 IndvMdeSteCstm_No_Rq 1;
BA_ "GenSigSendType" SG_ 1239 IndvMdeSteCstm_No_Rq 3;
BA_ "GenSigStartValue" SG_ 1239 IndvMdeSteCstm_No_Rq 15;
BA_ "U_CD542_MY2021_Tx" SG_ 1239 CstmDrvMdeMsgTxt_D_Rq 1;
BA_ "ECGUsedTxSignal" SG_ 1239 CstmDrvMdeMsgTxt_D_Rq 1;
BA_ "GenSigSendType" SG_ 1239 CstmDrvMdeMsgTxt_D_Rq 3;
BA_ "U_CD542_MY2021_Tx" SG_ 1239 ActvDrvMdeCstm_D2_Rq 1;
BA_ "ECGUsedTxSignal" SG_ 1239 ActvDrvMdeCstm_D2_Rq 1;
BA_ "GenSigSendType" SG_ 1239 ActvDrvMdeCstm_D2_Rq 3;
BA_ "GenSigStartValue" SG_ 1239 ActvDrvMdeCstm_D2_Rq 31;
BA_ "U_U55X_MY2022_Tx" SG_ 716 TMCSrvr_TMCClnt_WORD_Rx 1;
BA_ "U_CD542_MY2021_Tx" SG_ 716 TMCSrvr_TMCClnt_WORD_Rx 1;
BA_ "U_T6_MCA_MY2020_Tx" SG_ 716 TMCSrvr_TMCClnt_WORD_Rx 1;
BA_ "U_P702_MY2021_Tx" SG_ 716 TMCSrvr_TMCClnt_WORD_Rx 1;
BA_ "U_U55X_MY2022_Rx" SG_ 716 TMCSrvr_TMCClnt_WORD_Rx 1;
BA_ "U_CD542_MY2021_Rx" SG_ 716 TMCSrvr_TMCClnt_WORD_Rx 1;
BA_ "U_T6_MCA_MY2020_Rx" SG_ 716 TMCSrvr_TMCClnt_WORD_Rx 1;
BA_ "U_P702_MY2021_Rx" SG_ 716 TMCSrvr_TMCClnt_WORD_Rx 1;
BA_ "U_U55X_MY2022_Rx" SG_ 1013 ChrgToPcWkndSav_D_Stat 1;
BA_ "U_T6_MCA_MY2020_Rx" SG_ 1013 ChrgToPcWkndSav_D_Stat 1;
BA_ "U_P702_MY2021_Rx" SG_ 1013 ChrgToPcWkndSav_D_Stat 1;
BA_ "U_U55X_MY2022_Rx" SG_ 1013 ChrgToPcWkdySav_D_Stat 1;
BA_ "U_T6_MCA_MY2020_Rx" SG_ 1013 ChrgToPcWkdySav_D_Stat 1;
BA_ "U_P702_MY2021_Rx" SG_ 1013 ChrgToPcWkdySav_D_Stat 1;
BA_ "U_U55X_MY2022_Rx" SG_ 1013 ChrgProgIdSaved_D_Stat 1;
BA_ "U_T6_MCA_MY2020_Rx" SG_ 1013 ChrgProgIdSaved_D_Stat 1;
BA_ "U_P702_MY2021_Rx" SG_ 1013 ChrgProgIdSaved_D_Stat 1;
BA_ "U_U55X_MY2022_Rx" SG_ 1013 ChrgNowEnbl_B_Saved 1;
BA_ "U_T6_MCA_MY2020_Rx" SG_ 1013 ChrgNowEnbl_B_Saved 1;
BA_ "U_P702_MY2021_Rx" SG_ 1013 ChrgNowEnbl_B_Saved 1;
BA_ "U_U55X_MY2022_Rx" SG_ 1013 ChrgLocIdUnsAck_B_Stat 1;
BA_ "U_T6_MCA_MY2020_Rx" SG_ 1013 ChrgLocIdUnsAck_B_Stat 1;
BA_ "U_P702_MY2021_Rx" SG_ 1013 ChrgLocIdUnsAck_B_Stat 1;
BA_ "U_CD542_MY2021_Rx" SG_ 1013 ChrgLocIdCurnt_D_Sav 1;
BA_ "U_U55X_MY2022_Rx" SG_ 1013 ChrgLocIdCurnt_D_Sav 1;
BA_ "U_T6_MCA_MY2020_Rx" SG_ 1013 ChrgLocIdCurnt_D_Sav 1;
BA_ "U_P702_MY2021_Rx" SG_ 1013 ChrgLocIdCurnt_D_Sav 1;
BA_ "U_U55X_MY2022_Rx" SG_ 1013 ChrgPrflWknd_No_Actl 1;
BA_ "U_T6_MCA_MY2020_Rx" SG_ 1013 ChrgPrflWknd_No_Actl 1;
BA_ "U_P702_MY2021_Rx" SG_ 1013 ChrgPrflWknd_No_Actl 1;
BA_ "U_U55X_MY2022_Rx" SG_ 1013 ChrgPrflWkdy_No_Actl 1;
BA_ "U_T6_MCA_MY2020_Rx" SG_ 1013 ChrgPrflWkdy_No_Actl 1;
BA_ "U_P702_MY2021_Rx" SG_ 1013 ChrgPrflWkdy_No_Actl 1;
BA_ "U_U55X_MY2022_Rx" SG_ 641 ChrgGoTElement_B_Dsply_UB 1;
BA_ "U_T6_MCA_MY2020_Rx" SG_ 641 ChrgGoTElement_B_Dsply_UB 1;
BA_ "U_P702_MY2021_Rx" SG_ 641 ChrgGoTElement_B_Dsply_UB 1;
BA_ "U_CD542_MY2021_Rx" SG_ 641 ChrgGoTElement_B_Dsply_UB 1;
BA_ "U_U55X_MY2022_Rx" SG_ 641 ChrgGoTElement_B_Dsply 1;
BA_ "U_T6_MCA_MY2020_Rx" SG_ 641 ChrgGoTElement_B_Dsply 1;
BA_ "U_P702_MY2021_Rx" SG_ 641 ChrgGoTElement_B_Dsply 1;
BA_ "U_CD542_MY2021_Rx" SG_ 641 ChrgGoTElement_B_Dsply 1;
BA_ "GenSigSendType" SG_ 641 ChrgGoTElement_B_Dsply 3;
BA_ "U_CD542_MY2021_Rx" SG_ 641 BattChrgTrgtSoC_D_Rq 1;
BA_ "U_T6_MCA_MY2020_Rx" SG_ 641 BattChrgTrgtSoC_D_Rq 1;
BA_ "U_CD542_MY2021_Rx" SG_ 641 BattChrgTrgtSoC_D_Rq_UB 1;
BA_ "U_T6_MCA_MY2020_Rx" SG_ 641 BattChrgTrgtSoC_D_Rq_UB 1;
BA_ "U_CD542_MY2021_Rx" SG_ 641 ChrgLocIdCurnt_D_Uns_UB 1;
BA_ "U_U55X_MY2022_Rx" SG_ 641 ChrgLocIdCurnt_D_Uns_UB 1;
BA_ "U_T6_MCA_MY2020_Rx" SG_ 641 ChrgLocIdCurnt_D_Uns_UB 1;
BA_ "U_P702_MY2021_Rx" SG_ 641 ChrgLocIdCurnt_D_Uns_UB 1;
BA_ "U_CD542_MY2021_Rx" SG_ 641 ChrgLocIdCurnt_D_Uns 1;
BA_ "U_U55X_MY2022_Rx" SG_ 641 ChrgLocIdCurnt_D_Uns 1;
BA_ "U_T6_MCA_MY2020_Rx" SG_ 641 ChrgLocIdCurnt_D_Uns 1;
BA_ "U_P702_MY2021_Rx" SG_ 641 ChrgLocIdCurnt_D_Uns 1;
BA_ "GenSigSendType" SG_ 641 ChrgLocIdCurnt_D_Uns 3;
BA_ "U_CD542_MY2021_Rx" SG_ 641 IgnPsswrdActv_B_Stat_UB 1;
BA_ "U_U55X_MY2022_Rx" SG_ 641 IgnPsswrdActv_B_Stat_UB 1;
BA_ "U_T6_MCA_MY2020_Rx" SG_ 641 IgnPsswrdActv_B_Stat_UB 1;
BA_ "U_P702_MY2021_Rx" SG_ 641 IgnPsswrdActv_B_Stat_UB 1;
BA_ "U_CD542_MY2021_Rx" SG_ 641 IgnPsswrdSetup_B_Rq_UB 1;
BA_ "U_U55X_MY2022_Rx" SG_ 641 IgnPsswrdSetup_B_Rq_UB 1;
BA_ "U_T6_MCA_MY2020_Rx" SG_ 641 IgnPsswrdSetup_B_Rq_UB 1;
BA_ "U_P702_MY2021_Rx" SG_ 641 IgnPsswrdSetup_B_Rq_UB 1;
BA_ "U_CD542_MY2021_Rx" SG_ 641 IgnPsswrdLckout_B_Stat_UB 1;
BA_ "U_U55X_MY2022_Rx" SG_ 641 IgnPsswrdLckout_B_Stat_UB 1;
BA_ "U_T6_MCA_MY2020_Rx" SG_ 641 IgnPsswrdLckout_B_Stat_UB 1;
BA_ "U_P702_MY2021_Rx" SG_ 641 IgnPsswrdLckout_B_Stat_UB 1;
BA_ "U_CD542_MY2021_Rx" SG_ 641 IgnPsswrdSetup_B_Rq 1;
BA_ "U_U55X_MY2022_Rx" SG_ 641 IgnPsswrdSetup_B_Rq 1;
BA_ "U_T6_MCA_MY2020_Rx" SG_ 641 IgnPsswrdSetup_B_Rq 1;
BA_ "U_P702_MY2021_Rx" SG_ 641 IgnPsswrdSetup_B_Rq 1;
BA_ "GenSigSendType" SG_ 641 IgnPsswrdSetup_B_Rq 3;
BA_ "U_CD542_MY2021_Rx" SG_ 641 IgnPsswrdLckout_B_Stat 1;
BA_ "U_U55X_MY2022_Rx" SG_ 641 IgnPsswrdLckout_B_Stat 1;
BA_ "U_T6_MCA_MY2020_Rx" SG_ 641 IgnPsswrdLckout_B_Stat 1;
BA_ "U_P702_MY2021_Rx" SG_ 641 IgnPsswrdLckout_B_Stat 1;
BA_ "GenSigSendType" SG_ 641 IgnPsswrdLckout_B_Stat 3;
BA_ "U_CD542_MY2021_Rx" SG_ 641 PaakCnnct_D_Stat_UB 1;
BA_ "U_U55X_MY2022_Rx" SG_ 641 PaakCnnct_D_Stat_UB 1;
BA_ "U_T6_MCA_MY2020_Rx" SG_ 641 PaakCnnct_D_Stat_UB 1;
BA_ "U_P702_MY2021_Rx" SG_ 641 PaakCnnct_D_Stat_UB 1;
BA_ "U_CD542_MY2021_Rx" SG_ 641 PaakCnnct_D_Stat 1;
BA_ "U_U55X_MY2022_Rx" SG_ 641 PaakCnnct_D_Stat 1;
BA_ "U_T6_MCA_MY2020_Rx" SG_ 641 PaakCnnct_D_Stat 1;
BA_ "U_P702_MY2021_Rx" SG_ 641 PaakCnnct_D_Stat 1;
BA_ "GenSigSendType" SG_ 641 PaakCnnct_D_Stat 3;
BA_ "U_CD542_MY2021_Rx" SG_ 641 IgnPsswrdActv_B_Stat 1;
BA_ "U_U55X_MY2022_Rx" SG_ 641 IgnPsswrdActv_B_Stat 1;
BA_ "U_T6_MCA_MY2020_Rx" SG_ 641 IgnPsswrdActv_B_Stat 1;
BA_ "U_P702_MY2021_Rx" SG_ 641 IgnPsswrdActv_B_Stat 1;
BA_ "GenSigSendType" SG_ 641 IgnPsswrdActv_B_Stat 3;
BA_ "U_CD542_MY2021_Rx" SG_ 641 ChrgGoTTouch_B_Stat_UB 1;
BA_ "U_U55X_MY2022_Rx" SG_ 641 ChrgGoTTouch_B_Stat_UB 1;
BA_ "U_T6_MCA_MY2020_Rx" SG_ 641 ChrgGoTTouch_B_Stat_UB 1;
BA_ "U_P702_MY2021_Rx" SG_ 641 ChrgGoTTouch_B_Stat_UB 1;
BA_ "U_CD542_MY2021_Rx" SG_ 641 ChrgGoTTouch_B_Stat 1;
BA_ "U_U55X_MY2022_Rx" SG_ 641 ChrgGoTTouch_B_Stat 1;
BA_ "U_T6_MCA_MY2020_Rx" SG_ 641 ChrgGoTTouch_B_Stat 1;
BA_ "U_P702_MY2021_Rx" SG_ 641 ChrgGoTTouch_B_Stat 1;
BA_ "GenSigSendType" SG_ 641 ChrgGoTTouch_B_Stat 3;
BA_ "U_CD542_MY2021_Rx" SG_ 641 ChrgGoTPrcond_D_Stat_UB 1;
BA_ "U_U55X_MY2022_Rx" SG_ 641 ChrgGoTPrcond_D_Stat_UB 1;
BA_ "U_T6_MCA_MY2020_Rx" SG_ 641 ChrgGoTPrcond_D_Stat_UB 1;
BA_ "U_P702_MY2021_Rx" SG_ 641 ChrgGoTPrcond_D_Stat_UB 1;
BA_ "U_CD542_MY2021_Rx" SG_ 641 ChrgGoTPrcond_D_Stat 1;
BA_ "U_U55X_MY2022_Rx" SG_ 641 ChrgGoTPrcond_D_Stat 1;
BA_ "U_T6_MCA_MY2020_Rx" SG_ 641 ChrgGoTPrcond_D_Stat 1;
BA_ "U_P702_MY2021_Rx" SG_ 641 ChrgGoTPrcond_D_Stat 1;
BA_ "U_CD542_MY2021_Rx" SG_ 641 ChrgGoTNext_D_Stat_UB 1;
BA_ "U_U55X_MY2022_Rx" SG_ 641 ChrgGoTNext_D_Stat_UB 1;
BA_ "U_T6_MCA_MY2020_Rx" SG_ 641 ChrgGoTNext_D_Stat_UB 1;
BA_ "U_P702_MY2021_Rx" SG_ 641 ChrgGoTNext_D_Stat_UB 1;
BA_ "U_CD542_MY2021_Rx" SG_ 641 ChrgGoTNext_D_Stat 1;
BA_ "U_U55X_MY2022_Rx" SG_ 641 ChrgGoTNext_D_Stat 1;
BA_ "U_T6_MCA_MY2020_Rx" SG_ 641 ChrgGoTNext_D_Stat 1;
BA_ "U_P702_MY2021_Rx" SG_ 641 ChrgGoTNext_D_Stat 1;
BA_ "GenSigSendType" SG_ 641 ChrgGoTNext_D_Stat 3;
BA_ "U_CD542_MY2021_Rx" SG_ 641 ChrgGoTMnte_D_Stat_UB 1;
BA_ "U_U55X_MY2022_Rx" SG_ 641 ChrgGoTMnte_D_Stat_UB 1;
BA_ "U_T6_MCA_MY2020_Rx" SG_ 641 ChrgGoTMnte_D_Stat_UB 1;
BA_ "U_P702_MY2021_Rx" SG_ 641 ChrgGoTMnte_D_Stat_UB 1;
BA_ "U_CD542_MY2021_Rx" SG_ 641 ChrgGoTMnte_D_Stat 1;
BA_ "U_U55X_MY2022_Rx" SG_ 641 ChrgGoTMnte_D_Stat 1;
BA_ "U_T6_MCA_MY2020_Rx" SG_ 641 ChrgGoTMnte_D_Stat 1;
BA_ "U_P702_MY2021_Rx" SG_ 641 ChrgGoTMnte_D_Stat 1;
BA_ "U_CD542_MY2021_Rx" SG_ 641 ChrgGoTHr_T_Stat_UB 1;
BA_ "U_U55X_MY2022_Rx" SG_ 641 ChrgGoTHr_T_Stat_UB 1;
BA_ "U_T6_MCA_MY2020_Rx" SG_ 641 ChrgGoTHr_T_Stat_UB 1;
BA_ "U_P702_MY2021_Rx" SG_ 641 ChrgGoTHr_T_Stat_UB 1;
BA_ "U_CD542_MY2021_Rx" SG_ 641 ChrgGoTHr_T_Stat 1;
BA_ "U_U55X_MY2022_Rx" SG_ 641 ChrgGoTHr_T_Stat 1;
BA_ "U_T6_MCA_MY2020_Rx" SG_ 641 ChrgGoTHr_T_Stat 1;
BA_ "U_P702_MY2021_Rx" SG_ 641 ChrgGoTHr_T_Stat 1;
BA_ "GenSigStartValue" SG_ 641 ChrgGoTHr_T_Stat 30;
BA_ "GenSigStartValueInteger" SG_ 641 ChrgGoTHr_T_Stat 30;
BA_ "U_CD542_MY2021_Rx" SG_ 641 ChrgGoTExtHtr_B_Stat_UB 1;
BA_ "U_U55X_MY2022_Rx" SG_ 641 ChrgGoTExtHtr_B_Stat_UB 1;
BA_ "U_T6_MCA_MY2020_Rx" SG_ 641 ChrgGoTExtHtr_B_Stat_UB 1;
BA_ "U_P702_MY2021_Rx" SG_ 641 ChrgGoTExtHtr_B_Stat_UB 1;
BA_ "U_CD542_MY2021_Rx" SG_ 641 ChrgGoTExtHtr_B_Stat 1;
BA_ "U_U55X_MY2022_Rx" SG_ 641 ChrgGoTExtHtr_B_Stat 1;
BA_ "U_T6_MCA_MY2020_Rx" SG_ 641 ChrgGoTExtHtr_B_Stat 1;
BA_ "U_P702_MY2021_Rx" SG_ 641 ChrgGoTExtHtr_B_Stat 1;
BA_ "GenSigSendType" SG_ 641 ChrgGoTExtHtr_B_Stat 3;
BA_ "U_CD542_MY2021_Rx" SG_ 641 ChrgGoTElement_D_Stat_UB 1;
BA_ "U_U55X_MY2022_Rx" SG_ 641 ChrgGoTElement_D_Stat_UB 1;
BA_ "U_T6_MCA_MY2020_Rx" SG_ 641 ChrgGoTElement_D_Stat_UB 1;
BA_ "U_P702_MY2021_Rx" SG_ 641 ChrgGoTElement_D_Stat_UB 1;
BA_ "U_CD542_MY2021_Rx" SG_ 641 ChrgGoTElement_D_Stat 1;
BA_ "U_U55X_MY2022_Rx" SG_ 641 ChrgGoTElement_D_Stat 1;
BA_ "U_T6_MCA_MY2020_Rx" SG_ 641 ChrgGoTElement_D_Stat 1;
BA_ "U_P702_MY2021_Rx" SG_ 641 ChrgGoTElement_D_Stat 1;
BA_ "GenSigSendType" SG_ 641 ChrgGoTElement_D_Stat 3;
BA_ "U_CD542_MY2021_Rx" SG_ 641 ChrgGoTAllOn_B_Stat_UB 1;
BA_ "U_U55X_MY2022_Rx" SG_ 641 ChrgGoTAllOn_B_Stat_UB 1;
BA_ "U_T6_MCA_MY2020_Rx" SG_ 641 ChrgGoTAllOn_B_Stat_UB 1;
BA_ "U_P702_MY2021_Rx" SG_ 641 ChrgGoTAllOn_B_Stat_UB 1;
BA_ "U_CD542_MY2021_Rx" SG_ 641 ChrgGoTAllOn_B_Stat 1;
BA_ "U_U55X_MY2022_Rx" SG_ 641 ChrgGoTAllOn_B_Stat 1;
BA_ "U_T6_MCA_MY2020_Rx" SG_ 641 ChrgGoTAllOn_B_Stat 1;
BA_ "U_P702_MY2021_Rx" SG_ 641 ChrgGoTAllOn_B_Stat 1;
BA_ "GenSigSendType" SG_ 641 ChrgGoTAllOn_B_Stat 3;
BA_ "U_U55X_MY2022_Rx" SG_ 641 TrlrAidMsgTxt_D2_Rq 1;
BA_ "U_CD542_MY2021_Rx" SG_ 641 TrlrAidMsgTxt_D2_Rq 1;
BA_ "U_T6_MCA_MY2020_Rx" SG_ 641 TrlrAidMsgTxt_D2_Rq 1;
BA_ "U_P702_MY2021_Rx" SG_ 641 TrlrAidMsgTxt_D2_Rq 1;
BA_ "GenSigSendType" SG_ 641 TrlrAidMsgTxt_D2_Rq 3;
BA_ "U_P702_MY2021_Rx" SG_ 641 TrlrAidEnbl_D2_Stat 1;
BA_ "U_U55X_MY2022_Rx" SG_ 641 TrlrAidEnbl_D2_Stat 1;
BA_ "U_CD542_MY2021_Rx" SG_ 641 TrlrAidEnbl_D2_Stat 1;
BA_ "U_T6_MCA_MY2020_Rx" SG_ 641 TrlrAidEnbl_D2_Stat 1;
BA_ "GenSigSendType" SG_ 641 TrlrAidEnbl_D2_Stat 3;
BA_ "U_U55X_MY2022_Rx" SG_ 641 TrlrAidMsgTxt_D2_Rq_UB 1;
BA_ "U_CD542_MY2021_Rx" SG_ 641 TrlrAidMsgTxt_D2_Rq_UB 1;
BA_ "U_T6_MCA_MY2020_Rx" SG_ 641 TrlrAidMsgTxt_D2_Rq_UB 1;
BA_ "U_P702_MY2021_Rx" SG_ 641 TrlrAidMsgTxt_D2_Rq_UB 1;
BA_ "U_P702_MY2021_Rx" SG_ 641 TrlrAidEnbl_D2_Stat_UB 1;
BA_ "U_U55X_MY2022_Rx" SG_ 641 TrlrAidEnbl_D2_Stat_UB 1;
BA_ "U_CD542_MY2021_Rx" SG_ 641 TrlrAidEnbl_D2_Stat_UB 1;
BA_ "U_T6_MCA_MY2020_Rx" SG_ 641 TrlrAidEnbl_D2_Stat_UB 1;
BA_ "U_U55X_MY2022_Rx" SG_ 1012 ChrgLocSaved_B_Dsply 1;
BA_ "U_CD542_MY2021_Rx" SG_ 1012 ChrgLocSaved_B_Dsply 1;
BA_ "U_T6_MCA_MY2020_Rx" SG_ 1012 ChrgLocSaved_B_Dsply 1;
BA_ "U_P702_MY2021_Rx" SG_ 1012 ChrgLocSaved_B_Dsply 1;
BA_ "U_CD542_MY2021_Rx" SG_ 1012 ChrgLocLongPostv_B_Sav 1;
BA_ "U_U55X_MY2022_Rx" SG_ 1012 ChrgLocLongPostv_B_Sav 1;
BA_ "U_T6_MCA_MY2020_Rx" SG_ 1012 ChrgLocLongPostv_B_Sav 1;
BA_ "U_P702_MY2021_Rx" SG_ 1012 ChrgLocLongPostv_B_Sav 1;
BA_ "U_CD542_MY2021_Rx" SG_ 1012 ChrgLocLongFrct_An_Sav 1;
BA_ "U_U55X_MY2022_Rx" SG_ 1012 ChrgLocLongFrct_An_Sav 1;
BA_ "U_T6_MCA_MY2020_Rx" SG_ 1012 ChrgLocLongFrct_An_Sav 1;
BA_ "U_P702_MY2021_Rx" SG_ 1012 ChrgLocLongFrct_An_Sav 1;
BA_ "GenSigStartValue" SG_ 1012 ChrgLocLongFrct_An_Sav 1048575;
BA_ "GenSigStartValueInteger" SG_ 1012 ChrgLocLongFrct_An_Sav 1048575;
BA_ "U_CD542_MY2021_Rx" SG_ 1012 ChrgLocLongDeg_An_Sav 1;
BA_ "U_U55X_MY2022_Rx" SG_ 1012 ChrgLocLongDeg_An_Sav 1;
BA_ "U_T6_MCA_MY2020_Rx" SG_ 1012 ChrgLocLongDeg_An_Sav 1;
BA_ "U_P702_MY2021_Rx" SG_ 1012 ChrgLocLongDeg_An_Sav 1;
BA_ "U_CD542_MY2021_Rx" SG_ 1012 ChrgLocLattPostv_B_Sav 1;
BA_ "U_U55X_MY2022_Rx" SG_ 1012 ChrgLocLattPostv_B_Sav 1;
BA_ "U_T6_MCA_MY2020_Rx" SG_ 1012 ChrgLocLattPostv_B_Sav 1;
BA_ "U_P702_MY2021_Rx" SG_ 1012 ChrgLocLattPostv_B_Sav 1;
BA_ "U_CD542_MY2021_Rx" SG_ 1012 ChrgLocLattFrct_An_Sav 1;
BA_ "U_U55X_MY2022_Rx" SG_ 1012 ChrgLocLattFrct_An_Sav 1;
BA_ "U_T6_MCA_MY2020_Rx" SG_ 1012 ChrgLocLattFrct_An_Sav 1;
BA_ "U_P702_MY2021_Rx" SG_ 1012 ChrgLocLattFrct_An_Sav 1;
BA_ "GenSigStartValue" SG_ 1012 ChrgLocLattFrct_An_Sav 1048575;
BA_ "GenSigStartValueInteger" SG_ 1012 ChrgLocLattFrct_An_Sav 1048575;
BA_ "U_CD542_MY2021_Rx" SG_ 1012 ChrgLocLattDeg_An_Sav 1;
BA_ "U_U55X_MY2022_Rx" SG_ 1012 ChrgLocLattDeg_An_Sav 1;
BA_ "U_T6_MCA_MY2020_Rx" SG_ 1012 ChrgLocLattDeg_An_Sav 1;
BA_ "U_P702_MY2021_Rx" SG_ 1012 ChrgLocLattDeg_An_Sav 1;
BA_ "U_CD542_MY2021_Rx" SG_ 1012 ChrgLocId_D_Sav 1;
BA_ "U_U55X_MY2022_Rx" SG_ 1012 ChrgLocId_D_Sav 1;
BA_ "U_T6_MCA_MY2020_Rx" SG_ 1012 ChrgLocId_D_Sav 1;
BA_ "U_P702_MY2021_Rx" SG_ 1012 ChrgLocId_D_Sav 1;
BA_ "U_CD542_MY2021_Rx" SG_ 1012 ChrgNowCurnt_B_Dsply 1;
BA_ "U_U55X_MY2022_Rx" SG_ 1012 ChrgNowCurnt_B_Dsply 1;
BA_ "U_T6_MCA_MY2020_Rx" SG_ 1012 ChrgNowCurnt_B_Dsply 1;
BA_ "U_P702_MY2021_Rx" SG_ 1012 ChrgNowCurnt_B_Dsply 1;
BA_ "U_U55X_MY2022_Rx" SG_ 1011 ChrgLocLongPostv_B_Uns 1;
BA_ "U_CD542_MY2021_Rx" SG_ 1011 ChrgLocLongPostv_B_Uns 1;
BA_ "U_T6_MCA_MY2020_Rx" SG_ 1011 ChrgLocLongPostv_B_Uns 1;
BA_ "U_P702_MY2021_Rx" SG_ 1011 ChrgLocLongPostv_B_Uns 1;
BA_ "U_U55X_MY2022_Rx" SG_ 1011 ChrgLocLongFrct_An_Uns 1;
BA_ "U_CD542_MY2021_Rx" SG_ 1011 ChrgLocLongFrct_An_Uns 1;
BA_ "U_T6_MCA_MY2020_Rx" SG_ 1011 ChrgLocLongFrct_An_Uns 1;
BA_ "U_P702_MY2021_Rx" SG_ 1011 ChrgLocLongFrct_An_Uns 1;
BA_ "GenSigStartValue" SG_ 1011 ChrgLocLongFrct_An_Uns 1048575;
BA_ "GenSigStartValueInteger" SG_ 1011 ChrgLocLongFrct_An_Uns 1048575;
BA_ "U_U55X_MY2022_Rx" SG_ 1011 ChrgLocLongDeg_An_Uns 1;
BA_ "U_CD542_MY2021_Rx" SG_ 1011 ChrgLocLongDeg_An_Uns 1;
BA_ "U_T6_MCA_MY2020_Rx" SG_ 1011 ChrgLocLongDeg_An_Uns 1;
BA_ "U_P702_MY2021_Rx" SG_ 1011 ChrgLocLongDeg_An_Uns 1;
BA_ "U_U55X_MY2022_Rx" SG_ 1011 ChrgLocLattPostv_B_Uns 1;
BA_ "U_CD542_MY2021_Rx" SG_ 1011 ChrgLocLattPostv_B_Uns 1;
BA_ "U_T6_MCA_MY2020_Rx" SG_ 1011 ChrgLocLattPostv_B_Uns 1;
BA_ "U_P702_MY2021_Rx" SG_ 1011 ChrgLocLattPostv_B_Uns 1;
BA_ "U_U55X_MY2022_Rx" SG_ 1011 ChrgLocLattFrct_An_Uns 1;
BA_ "U_CD542_MY2021_Rx" SG_ 1011 ChrgLocLattFrct_An_Uns 1;
BA_ "U_T6_MCA_MY2020_Rx" SG_ 1011 ChrgLocLattFrct_An_Uns 1;
BA_ "U_P702_MY2021_Rx" SG_ 1011 ChrgLocLattFrct_An_Uns 1;
BA_ "GenSigStartValue" SG_ 1011 ChrgLocLattFrct_An_Uns 1048575;
BA_ "GenSigStartValueInteger" SG_ 1011 ChrgLocLattFrct_An_Uns 1048575;
BA_ "U_U55X_MY2022_Rx" SG_ 1011 ChrgLocLattDeg_An_Uns 1;
BA_ "U_CD542_MY2021_Rx" SG_ 1011 ChrgLocLattDeg_An_Uns 1;
BA_ "U_T6_MCA_MY2020_Rx" SG_ 1011 ChrgLocLattDeg_An_Uns 1;
BA_ "U_P702_MY2021_Rx" SG_ 1011 ChrgLocLattDeg_An_Uns 1;
BA_ "U_U55X_MY2022_Rx" SG_ 1011 ChrgLocId_D_Uns 1;
BA_ "U_CD542_MY2021_Rx" SG_ 1011 ChrgLocId_D_Uns 1;
BA_ "U_T6_MCA_MY2020_Rx" SG_ 1011 ChrgLocId_D_Uns 1;
BA_ "U_P702_MY2021_Rx" SG_ 1011 ChrgLocId_D_Uns 1;
BA_ "U_U55X_MY2022_Tx" SG_ 533 AutoEpbZoomView_B_Stat 1;
BA_ "U_CD542_MY2021_Tx" SG_ 533 AutoEpbZoomView_B_Stat 1;
BA_ "U_T6_MCA_MY2020_Tx" SG_ 533 AutoEpbZoomView_B_Stat 1;
BA_ "GenSigSendType" SG_ 533 AutoEpbZoomView_B_Stat 3;
BA_ "U_CD542_MY2021_Tx" SG_ 533 ClrExitAsstEnbl_D_RqMnu 1;
BA_ "U_U55X_MY2022_Tx" SG_ 533 ClrExitAsstEnbl_D_RqMnu 1;
BA_ "GenSigSendType" SG_ 533 ClrExitAsstEnbl_D_RqMnu 3;
BA_ "U_T6_MCA_MY2020_Tx" SG_ 533 PaakMyKey_D_Rq 1;
BA_ "U_P702_MY2021_Tx" SG_ 533 PaakMyKey_D_Rq 1;
BA_ "U_U55X_MY2022_Tx" SG_ 533 PaakMyKey_D_Rq 1;
BA_ "U_CD542_MY2021_Tx" SG_ 533 PaakMyKey_D_Rq 1;
BA_ "GenSigSendType" SG_ 533 PaakMyKey_D_Rq 3;
BA_ "U_U55X_MY2022_Tx" SG_ 533 AutoEpbButtn_B_Stat 1;
BA_ "U_CD542_MY2021_Tx" SG_ 533 AutoEpbButtn_B_Stat 1;
BA_ "U_T6_MCA_MY2020_Tx" SG_ 533 AutoEpbButtn_B_Stat 1;
BA_ "GenSigSendType" SG_ 533 AutoEpbButtn_B_Stat 3;
BA_ "U_T6_MCA_MY2020_Tx" SG_ 533 TrlrAidMde_D_Rq 1;
BA_ "U_P702_MY2021_Tx" SG_ 533 TrlrAidMde_D_Rq 1;
BA_ "U_U55X_MY2022_Tx" SG_ 533 TrlrAidMde_D_Rq 1;
BA_ "U_CD542_MY2021_Tx" SG_ 533 TrlrAidMde_D_Rq 1;
BA_ "GenSigSendType" SG_ 533 TrlrAidMde_D_Rq 3;
BA_ "U_T6_MCA_MY2020_Tx" SG_ 533 TCU_Init_Actvtn_St 1;
BA_ "U_P702_MY2021_Tx" SG_ 533 TCU_Init_Actvtn_St 1;
BA_ "U_U55X_MY2022_Tx" SG_ 533 TCU_Init_Actvtn_St 1;
BA_ "U_CD542_MY2021_Tx" SG_ 533 TCU_Init_Actvtn_St 1;
BA_ "GenSigSendType" SG_ 533 TCU_Init_Actvtn_St 3;
BA_ "U_T6_MCA_MY2020_Tx" SG_ 533 TCU_Final_Actvtn_St 1;
BA_ "U_P702_MY2021_Tx" SG_ 533 TCU_Final_Actvtn_St 1;
BA_ "U_U55X_MY2022_Tx" SG_ 533 TCU_Final_Actvtn_St 1;
BA_ "U_CD542_MY2021_Tx" SG_ 533 TCU_Final_Actvtn_St 1;
BA_ "GenSigSendType" SG_ 533 TCU_Final_Actvtn_St 3;
BA_ "U_U55X_MY2022_Tx" SG_ 533 DcacPw_D_Rq 1;
BA_ "U_CD542_MY2021_Tx" SG_ 533 DcacPw_D_Rq 1;
BA_ "GenSigSendType" SG_ 533 DcacPw_D_Rq 3;
BA_ "U_U55X_MY2022_Tx" SG_ 533 DcacPwReset_B_Rq 1;
BA_ "U_CD542_MY2021_Tx" SG_ 533 DcacPwReset_B_Rq 1;
BA_ "GenSigSendType" SG_ 533 DcacPwReset_B_Rq 3;
BA_ "U_U55X_MY2022_Tx" SG_ 533 LghtAmbDrvMde_D_Rq 1;
BA_ "U_CD542_MY2021_Tx" SG_ 533 LghtAmbDrvMde_D_Rq 1;
BA_ "U_T6_MCA_MY2020_Tx" SG_ 533 LghtAmbDrvMde_D_Rq 1;
BA_ "GenSigSendType" SG_ 533 LghtAmbDrvMde_D_Rq 3;
BA_ "WakeupSignal" SG_ 533 LghtAmbDrvMde_D_Rq 1;
BA_ "U_T6_MCA_MY2020_Tx" SG_ 533 OtaTrg_D_Stat 1;
BA_ "U_P702_MY2021_Tx" SG_ 533 OtaTrg_D_Stat 1;
BA_ "U_U55X_MY2022_Tx" SG_ 533 OtaTrg_D_Stat 1;
BA_ "U_CD542_MY2021_Tx" SG_ 533 OtaTrg_D_Stat 1;
BA_ "GenSigSendType" SG_ 533 OtaTrg_D_Stat 3;
BA_ "U_U55X_MY2022_Tx" SG_ 533 DcacPwLoButtn_B_Stat 1;
BA_ "U_CD542_MY2021_Tx" SG_ 533 DcacPwLoButtn_B_Stat 1;
BA_ "GenSigSendType" SG_ 533 DcacPwLoButtn_B_Stat 3;
BA_ "U_U55X_MY2022_Tx" SG_ 533 DcacPwOffButtn_B_Stat 1;
BA_ "U_CD542_MY2021_Tx" SG_ 533 DcacPwOffButtn_B_Stat 1;
BA_ "GenSigSendType" SG_ 533 DcacPwOffButtn_B_Stat 3;
BA_ "U_U55X_MY2022_Tx" SG_ 533 DcacPwHiButtn_B_Stat 1;
BA_ "U_CD542_MY2021_Tx" SG_ 533 DcacPwHiButtn_B_Stat 1;
BA_ "GenSigSendType" SG_ 533 DcacPwHiButtn_B_Stat 3;
BA_ "U_U55X_MY2022_Tx" SG_ 533 DcacPwResetButtn_B_Stat 1;
BA_ "U_CD542_MY2021_Tx" SG_ 533 DcacPwResetButtn_B_Stat 1;
BA_ "GenSigSendType" SG_ 533 DcacPwResetButtn_B_Stat 3;
BA_ "U_U55X_MY2022_Tx" SG_ 533 DcacPwButtn_B_Falt 1;
BA_ "U_CD542_MY2021_Tx" SG_ 533 DcacPwButtn_B_Falt 1;
BA_ "GenSigSendType" SG_ 533 DcacPwButtn_B_Falt 3;
BA_ "U_T6_MCA_MY2020_Tx" SG_ 533 OnbChrgGoTTouch_D_Rq 1;
BA_ "U_P702_MY2021_Tx" SG_ 533 OnbChrgGoTTouch_D_Rq 1;
BA_ "U_U55X_MY2022_Tx" SG_ 533 OnbChrgGoTTouch_D_Rq 1;
BA_ "U_CD542_MY2021_Tx" SG_ 533 OnbChrgGoTTouch_D_Rq 1;
BA_ "GenSigSendType" SG_ 533 OnbChrgGoTTouch_D_Rq 3;
BA_ "U_U55X_MY2022_Tx" SG_ 533 OnbChrgGoTPrcond_D_Rq 1;
BA_ "U_CD542_MY2021_Tx" SG_ 533 OnbChrgGoTPrcond_D_Rq 1;
BA_ "U_T6_MCA_MY2020_Tx" SG_ 533 OnbChrgGoTPrcond_D_Rq 1;
BA_ "U_P702_MY2021_Tx" SG_ 533 OnbChrgGoTPrcond_D_Rq 1;
BA_ "GenSigSendType" SG_ 533 OnbChrgGoTPrcond_D_Rq 3;
BA_ "U_U55X_MY2022_Tx" SG_ 533 OnbChrgGoTOn_D_Rq 1;
BA_ "U_CD542_MY2021_Tx" SG_ 533 OnbChrgGoTOn_D_Rq 1;
BA_ "U_T6_MCA_MY2020_Tx" SG_ 533 OnbChrgGoTOn_D_Rq 1;
BA_ "U_P702_MY2021_Tx" SG_ 533 OnbChrgGoTOn_D_Rq 1;
BA_ "GenSigSendType" SG_ 533 OnbChrgGoTOn_D_Rq 3;
BA_ "GenSigStartValue" SG_ 533 OnbChrgGoTOn_D_Rq 2;
BA_ "GenSigStartValueInteger" SG_ 533 OnbChrgGoTOn_D_Rq 2;
BA_ "U_U55X_MY2022_Tx" SG_ 533 OnbChrgGoTMnte_D_Rq 1;
BA_ "U_CD542_MY2021_Tx" SG_ 533 OnbChrgGoTMnte_D_Rq 1;
BA_ "U_T6_MCA_MY2020_Tx" SG_ 533 OnbChrgGoTMnte_D_Rq 1;
BA_ "U_P702_MY2021_Tx" SG_ 533 OnbChrgGoTMnte_D_Rq 1;
BA_ "U_U55X_MY2022_Tx" SG_ 533 OnbChrgGoTHr_T_Rq 1;
BA_ "U_CD542_MY2021_Tx" SG_ 533 OnbChrgGoTHr_T_Rq 1;
BA_ "U_T6_MCA_MY2020_Tx" SG_ 533 OnbChrgGoTHr_T_Rq 1;
BA_ "U_P702_MY2021_Tx" SG_ 533 OnbChrgGoTHr_T_Rq 1;
BA_ "GenSigStartValue" SG_ 533 OnbChrgGoTHr_T_Rq 30;
BA_ "GenSigStartValueInteger" SG_ 533 OnbChrgGoTHr_T_Rq 30;
BA_ "U_U55X_MY2022_Tx" SG_ 533 OnbChrgGoTExtHtr_D_Rq 1;
BA_ "U_CD542_MY2021_Tx" SG_ 533 OnbChrgGoTExtHtr_D_Rq 1;
BA_ "U_T6_MCA_MY2020_Tx" SG_ 533 OnbChrgGoTExtHtr_D_Rq 1;
BA_ "U_P702_MY2021_Tx" SG_ 533 OnbChrgGoTExtHtr_D_Rq 1;
BA_ "GenSigSendType" SG_ 533 OnbChrgGoTExtHtr_D_Rq 3;
BA_ "U_U55X_MY2022_Tx" SG_ 533 OnbChrgGoTElement_D_Rq 1;
BA_ "U_CD542_MY2021_Tx" SG_ 533 OnbChrgGoTElement_D_Rq 1;
BA_ "U_T6_MCA_MY2020_Tx" SG_ 533 OnbChrgGoTElement_D_Rq 1;
BA_ "U_P702_MY2021_Tx" SG_ 533 OnbChrgGoTElement_D_Rq 1;
BA_ "GenSigSendType" SG_ 533 OnbChrgGoTElement_D_Rq 3;
BA_ "U_U55X_MY2022_Tx" SG_ 533 OnbChrgGoTDelete_B_Rq 1;
BA_ "U_CD542_MY2021_Tx" SG_ 533 OnbChrgGoTDelete_B_Rq 1;
BA_ "U_T6_MCA_MY2020_Tx" SG_ 533 OnbChrgGoTDelete_B_Rq 1;
BA_ "U_P702_MY2021_Tx" SG_ 533 OnbChrgGoTDelete_B_Rq 1;
BA_ "GenSigSendType" SG_ 533 OnbChrgGoTDelete_B_Rq 3;
BA_ "U_U55X_MY2022_Tx" SG_ 533 OnbChrgClearAll_B_Rq 1;
BA_ "U_CD542_MY2021_Tx" SG_ 533 OnbChrgClearAll_B_Rq 1;
BA_ "U_T6_MCA_MY2020_Tx" SG_ 533 OnbChrgClearAll_B_Rq 1;
BA_ "U_P702_MY2021_Tx" SG_ 533 OnbChrgClearAll_B_Rq 1;
BA_ "GenSigSendType" SG_ 533 OnbChrgClearAll_B_Rq 3;
BA_ "U_U55X_MY2022_Tx" SG_ 533 OnbChrgGoTUpdate_B_Rq 1;
BA_ "U_CD542_MY2021_Tx" SG_ 533 OnbChrgGoTUpdate_B_Rq 1;
BA_ "U_T6_MCA_MY2020_Tx" SG_ 533 OnbChrgGoTUpdate_B_Rq 1;
BA_ "U_P702_MY2021_Tx" SG_ 533 OnbChrgGoTUpdate_B_Rq 1;
BA_ "U_U55X_MY2022_Rx" SG_ 533 OnbChrgGoTUpdate_B_Rq 1;
BA_ "U_CD542_MY2021_Rx" SG_ 533 OnbChrgGoTUpdate_B_Rq 1;
BA_ "ECGUsedRxSignal" SG_ 533 OnbChrgGoTUpdate_B_Rq 1;
BA_ "U_T6_MCA_MY2020_Rx" SG_ 533 OnbChrgGoTUpdate_B_Rq 1;
BA_ "GenSigSendType" SG_ 533 OnbChrgGoTUpdate_B_Rq 3;
BA_ "U_U55X_MY2022_Tx" SG_ 533 TrlrAlarmButtn_B_Stat 1;
BA_ "U_CD542_MY2021_Tx" SG_ 533 TrlrAlarmButtn_B_Stat 1;
BA_ "U_T6_MCA_MY2020_Tx" SG_ 533 TrlrAlarmButtn_B_Stat 1;
BA_ "U_U55X_MY2022_Rx" SG_ 533 TrlrAlarmButtn_B_Stat 1;
BA_ "U_T6_MCA_MY2020_Rx" SG_ 533 TrlrAlarmButtn_B_Stat 1;
BA_ "GenSigSendType" SG_ 533 TrlrAlarmButtn_B_Stat 3;
BA_ "U_U55X_MY2022_Tx" SG_ 533 DcacMdeButtn_B_Stat 1;
BA_ "U_CD542_MY2021_Tx" SG_ 533 DcacMdeButtn_B_Stat 1;
BA_ "GenSigSendType" SG_ 533 DcacMdeButtn_B_Stat 3;
BA_ "U_U55X_MY2022_Tx" SG_ 533 DcacGfciTestBttn_B_Stat 1;
BA_ "U_CD542_MY2021_Tx" SG_ 533 DcacGfciTestBttn_B_Stat 1;
BA_ "GenSigSendType" SG_ 533 DcacGfciTestBttn_B_Stat 3;
BA_ "U_U55X_MY2022_Tx" SG_ 533 TrlrBrkGain_No_Rq 1;
BA_ "U_CD542_MY2021_Tx" SG_ 533 TrlrBrkGain_No_Rq 1;
BA_ "U_T6_MCA_MY2020_Tx" SG_ 533 TrlrBrkGain_No_Rq 1;
BA_ "U_U55X_MY2022_Rx" SG_ 533 TrlrBrkGain_No_Rq 1;
BA_ "U_T6_MCA_MY2020_Rx" SG_ 533 TrlrBrkGain_No_Rq 1;
BA_ "GenSigSendType" SG_ 533 TrlrBrkGain_No_Rq 3;
BA_ "U_U55X_MY2022_Tx" SG_ 533 TrlrHitch_D_RqMnu 1;
BA_ "U_CD542_MY2021_Tx" SG_ 533 TrlrHitch_D_RqMnu 1;
BA_ "U_T6_MCA_MY2020_Tx" SG_ 533 TrlrHitch_D_RqMnu 1;
BA_ "GenSigSendType" SG_ 533 TrlrHitch_D_RqMnu 3;
BA_ "U_U55X_MY2022_Tx" SG_ 533 DcacPwButtn_B_Stat 1;
BA_ "U_CD542_MY2021_Tx" SG_ 533 DcacPwButtn_B_Stat 1;
BA_ "GenSigSendType" SG_ 533 DcacPwButtn_B_Stat 3;
BA_ "U_U55X_MY2022_Rx" SG_ 1184 APIM_TCU_Word_Rx 1;
BA_ "U_CD542_MY2021_Rx" SG_ 1184 APIM_TCU_Word_Rx 1;
BA_ "U_T6_MCA_MY2020_Rx" SG_ 1184 APIM_TCU_Word_Rx 1;
BA_ "U_P702_MY2021_Rx" SG_ 1184 APIM_TCU_Word_Rx 1;
BA_ "U_U55X_MY2022_Tx" SG_ 801 CDWarnChime_St 1;
BA_ "U_CD542_MY2021_Tx" SG_ 801 CDWarnChime_St 1;
BA_ "U_T6_MCA_MY2020_Tx" SG_ 801 CDWarnChime_St 1;
BA_ "U_P702_MY2021_Tx" SG_ 801 CDWarnChime_St 1;
BA_ "U_T6_MCA_MY2020_Rx" SG_ 801 CDWarnChime_St 1;
BA_ "GenSigSendType" SG_ 801 CDWarnChime_St 3;
BA_ "U_U55X_MY2022_Tx" SG_ 801 SoftWarning 1;
BA_ "U_CD542_MY2021_Tx" SG_ 801 SoftWarning 1;
BA_ "U_T6_MCA_MY2020_Tx" SG_ 801 SoftWarning 1;
BA_ "U_P702_MY2021_Tx" SG_ 801 SoftWarning 1;
BA_ "U_T6_MCA_MY2020_Rx" SG_ 801 SoftWarning 1;
BA_ "GenSigSendType" SG_ 801 SoftWarning 3;
BA_ "U_U55X_MY2022_Tx" SG_ 801 HardWarning 1;
BA_ "U_CD542_MY2021_Tx" SG_ 801 HardWarning 1;
BA_ "U_T6_MCA_MY2020_Tx" SG_ 801 HardWarning 1;
BA_ "U_P702_MY2021_Tx" SG_ 801 HardWarning 1;
BA_ "U_T6_MCA_MY2020_Rx" SG_ 801 HardWarning 1;
BA_ "GenSigSendType" SG_ 801 HardWarning 3;
BA_ "U_U55X_MY2022_Tx" SG_ 801 InfoWarning 1;
BA_ "U_CD542_MY2021_Tx" SG_ 801 InfoWarning 1;
BA_ "U_T6_MCA_MY2020_Tx" SG_ 801 InfoWarning 1;
BA_ "U_P702_MY2021_Tx" SG_ 801 InfoWarning 1;
BA_ "U_T6_MCA_MY2020_Rx" SG_ 801 InfoWarning 1;
BA_ "GenSigSendType" SG_ 801 InfoWarning 3;
BA_ "U_U55X_MY2022_Tx" SG_ 801 DrvDsplyPalette_D_Stat 1;
BA_ "U_CD542_MY2021_Tx" SG_ 801 DrvDsplyPalette_D_Stat 1;
BA_ "U_T6_MCA_MY2020_Tx" SG_ 801 DrvDsplyPalette_D_Stat 1;
BA_ "U_T6_MCA_MY2020_Rx" SG_ 801 DrvDsplyPalette_D_Stat 1;
BA_ "GenSigSendType" SG_ 801 DrvDsplyPalette_D_Stat 3;
BA_ "U_U55X_MY2022_Tx" SG_ 878 ClimtSyncRear2_B_Stat 1;
BA_ "GenSigSendType" SG_ 878 ClimtSyncRear2_B_Stat 3;
BA_ "U_U55X_MY2022_Tx" SG_ 878 ClimtStHeatRr2_B_Stat 1;
BA_ "GenSigSendType" SG_ 878 ClimtStHeatRr2_B_Stat 3;
BA_ "U_U55X_MY2022_Tx" SG_ 878 ClimtStHeatRl2_B_Stat 1;
BA_ "GenSigSendType" SG_ 878 ClimtStHeatRl2_B_Stat 3;
BA_ "U_U55X_MY2022_Tx" SG_ 878 ClimtStCoolRr2_B_Stat 1;
BA_ "GenSigSendType" SG_ 878 ClimtStCoolRr2_B_Stat 3;
BA_ "U_U55X_MY2022_Tx" SG_ 878 ClimtStCoolRl2_B_Stat 1;
BA_ "GenSigSendType" SG_ 878 ClimtStCoolRl2_B_Stat 3;
BA_ "U_U55X_MY2022_Tx" SG_ 878 ClimtSeatRr2_D_Rq 1;
BA_ "GenSigSendType" SG_ 878 ClimtSeatRr2_D_Rq 3;
BA_ "U_U55X_MY2022_Tx" SG_ 878 ClimtSeatRl2_D_Rq 1;
BA_ "GenSigSendType" SG_ 878 ClimtSeatRl2_D_Rq 3;
BA_ "U_U55X_MY2022_Tx" SG_ 878 ClimtRrTe3rd2_D_Stat 1;
BA_ "GenSigSendType" SG_ 878 ClimtRrTe3rd2_D_Stat 3;
BA_ "U_U55X_MY2022_Tx" SG_ 878 ClimtRrPw3rd2_B_Stat 1;
BA_ "GenSigSendType" SG_ 878 ClimtRrPw3rd2_B_Stat 3;
BA_ "U_U55X_MY2022_Tx" SG_ 878 ClimtRrPnl3rd2_B_Stat 1;
BA_ "GenSigSendType" SG_ 878 ClimtRrPnl3rd2_B_Stat 3;
BA_ "U_U55X_MY2022_Tx" SG_ 878 ClimtRrPf3rd2_B_Stat 1;
BA_ "GenSigSendType" SG_ 878 ClimtRrPf3rd2_B_Stat 3;
BA_ "U_U55X_MY2022_Tx" SG_ 878 ClimtRrFlr3rd2_B_Stat 1;
BA_ "GenSigSendType" SG_ 878 ClimtRrFlr3rd2_B_Stat 3;
BA_ "U_U55X_MY2022_Tx" SG_ 878 ClimtRrBlwr3rd2_D_Stat 1;
BA_ "GenSigSendType" SG_ 878 ClimtRrBlwr3rd2_D_Stat 3;
BA_ "U_U55X_MY2022_Tx" SG_ 878 ClimtRrAuto3rd2_B_Stat 1;
BA_ "GenSigSendType" SG_ 878 ClimtRrAuto3rd2_B_Stat 3;
BA_ "U_U55X_MY2022_Tx" SG_ 878 ClimtRearView2_D_Stat 1;
BA_ "GenSigSendType" SG_ 878 ClimtRearView2_D_Stat 3;
BA_ "U_U55X_MY2022_Tx" SG_ 878 ClimtRearTe2_D_Stat 1;
BA_ "GenSigSendType" SG_ 878 ClimtRearTe2_D_Stat 3;
BA_ "U_U55X_MY2022_Tx" SG_ 878 ClimtRearTe2_An_Actl 1;
BA_ "GenSigSendType" SG_ 878 ClimtRearTe2_An_Actl 3;
BA_ "GenSigStartValue" SG_ 878 ClimtRearTe2_An_Actl 511;
BA_ "GenSigStartValueInteger" SG_ 878 ClimtRearTe2_An_Actl 511;
BA_ "U_U55X_MY2022_Tx" SG_ 878 ClimtRearPw2_B_Stat 1;
BA_ "GenSigSendType" SG_ 878 ClimtRearPw2_B_Stat 3;
BA_ "U_U55X_MY2022_Tx" SG_ 878 ClimtRearPnlFlr2_B_Stat 1;
BA_ "GenSigSendType" SG_ 878 ClimtRearPnlFlr2_B_Stat 3;
BA_ "U_U55X_MY2022_Tx" SG_ 878 ClimtRearPnl2_B_Stat 1;
BA_ "GenSigSendType" SG_ 878 ClimtRearPnl2_B_Stat 3;
BA_ "U_U55X_MY2022_Tx" SG_ 878 ClimtRearFlr2_B_Stat 1;
BA_ "GenSigSendType" SG_ 878 ClimtRearFlr2_B_Stat 3;
BA_ "U_U55X_MY2022_Tx" SG_ 878 ClimtRearBlwr2_D_Stat 1;
BA_ "GenSigSendType" SG_ 878 ClimtRearBlwr2_D_Stat 3;
BA_ "U_U55X_MY2022_Tx" SG_ 878 ClimtRearBlwr2_An_Actl 1;
BA_ "GenSigSendType" SG_ 878 ClimtRearBlwr2_An_Actl 3;
BA_ "GenSigStartValue" SG_ 878 ClimtRearBlwr2_An_Actl 511;
BA_ "GenSigStartValueInteger" SG_ 878 ClimtRearBlwr2_An_Actl 511;
BA_ "U_U55X_MY2022_Tx" SG_ 878 ClimtRearAuto2_B_Stat 1;
BA_ "GenSigSendType" SG_ 878 ClimtRearAuto2_B_Stat 3;
BA_ "U_U55X_MY2022_Rx" SG_ 258 GPS_Track_D_Rq 1;
BA_ "U_CD542_MY2021_Rx" SG_ 258 GPS_Track_D_Rq 1;
BA_ "U_P702_MY2021_Rx" SG_ 258 GPS_Track_D_Rq 1;
BA_ "U_U55X_MY2022_Rx" SG_ 258 APIM_SwPartNo_D_Rq 1;
BA_ "U_CD542_MY2021_Rx" SG_ 258 APIM_SwPartNo_D_Rq 1;
BA_ "U_T6_MCA_MY2020_Rx" SG_ 258 APIM_SwPartNo_D_Rq 1;
BA_ "U_P702_MY2021_Rx" SG_ 258 APIM_SwPartNo_D_Rq 1;
BA_ "U_U55X_MY2022_Rx" SG_ 258 TCU_Init_Actvtn_Rq 1;
BA_ "U_CD542_MY2021_Rx" SG_ 258 TCU_Init_Actvtn_Rq 1;
BA_ "U_P702_MY2021_Rx" SG_ 258 TCU_Init_Actvtn_Rq 1;
BA_ "U_U55X_MY2022_Rx" SG_ 258 TCU_Final_Actvtn_Rq 1;
BA_ "U_CD542_MY2021_Rx" SG_ 258 TCU_Final_Actvtn_Rq 1;
BA_ "U_P702_MY2021_Rx" SG_ 258 TCU_Final_Actvtn_Rq 1;
BA_ "U_U55X_MY2022_Tx" SG_ 1192 APIM_TCU_Word_Tx 1;
BA_ "U_CD542_MY2021_Tx" SG_ 1192 APIM_TCU_Word_Tx 1;
BA_ "U_T6_MCA_MY2020_Tx" SG_ 1192 APIM_TCU_Word_Tx 1;
BA_ "U_P702_MY2021_Tx" SG_ 1192 APIM_TCU_Word_Tx 1;
BA_ "U_U55X_MY2022_Tx" SG_ 413 LBS1_ParentID 1;
BA_ "U_CD542_MY2021_Tx" SG_ 413 LBS1_ParentID 1;
BA_ "U_U55X_MY2022_Rx" SG_ 413 LBS1_ParentID 1;
BA_ "U_CD542_MY2021_Rx" SG_ 413 LBS1_ParentID 1;
BA_ "U_U55X_MY2022_Tx" SG_ 413 LBS1_ListStatus 1;
BA_ "U_CD542_MY2021_Tx" SG_ 413 LBS1_ListStatus 1;
BA_ "U_CD542_MY2021_Rx" SG_ 413 LBS1_ListStatus 1;
BA_ "U_U55X_MY2022_Rx" SG_ 413 LBS1_ListStatus 1;
BA_ "GenSigSendType" SG_ 413 LBS1_ListStatus 3;
BA_ "U_U55X_MY2022_Tx" SG_ 413 LBS1_ListServer 1;
BA_ "U_CD542_MY2021_Tx" SG_ 413 LBS1_ListServer 1;
BA_ "U_CD542_MY2021_Rx" SG_ 413 LBS1_ListServer 1;
BA_ "U_U55X_MY2022_Rx" SG_ 413 LBS1_ListServer 1;
BA_ "U_U55X_MY2022_Tx" SG_ 413 LBS1_ListID 1;
BA_ "U_CD542_MY2021_Tx" SG_ 413 LBS1_ListID 1;
BA_ "U_CD542_MY2021_Rx" SG_ 413 LBS1_ListID 1;
BA_ "U_U55X_MY2022_Rx" SG_ 413 LBS1_ListID 1;
BA_ "U_U55X_MY2022_Tx" SG_ 413 LBS1_EntryIndex 1;
BA_ "U_CD542_MY2021_Tx" SG_ 413 LBS1_EntryIndex 1;
BA_ "U_CD542_MY2021_Rx" SG_ 413 LBS1_EntryIndex 1;
BA_ "U_U55X_MY2022_Rx" SG_ 413 LBS1_EntryIndex 1;
BA_ "GenSigSendType" SG_ 556 DrvAsstMnuButtn_B_Stat 3;
BA_ "U_CD542_MY2021_Rx" SG_ 556 Manual_Temp_Setting 1;
BA_ "GenSigSendType" SG_ 556 Manual_Temp_Setting 3;
BA_ "U_U55X_MY2022_Rx" SG_ 556 EFP_Bezel_Diag_St 1;
BA_ "GenSigSendType" SG_ 556 EFP_Bezel_Diag_St 3;
BA_ "U_U55X_MY2022_Rx" SG_ 556 Bezel_Beep_St 1;
BA_ "GenSigSendType" SG_ 556 Bezel_Beep_St 3;
BA_ "U_U55X_MY2022_Rx" SG_ 556 Bezel_Beeps_Supported 1;
BA_ "GenSigSendType" SG_ 556 Bezel_Beeps_Supported 3;
BA_ "GenSigSendType" SG_ 556 PassRstrnInd_Stat 3;
BA_ "U_U55X_MY2022_Tx" SG_ 259 SDARS_CurrCATlstSize_Rq 1;
BA_ "U_CD542_MY2021_Tx" SG_ 259 SDARS_CurrCATlstSize_Rq 1;
BA_ "U_T6_MCA_MY2020_Tx" SG_ 259 SDARS_CurrCATlstSize_Rq 1;
BA_ "U_P702_MY2021_Tx" SG_ 259 SDARS_CurrCATlstSize_Rq 1;
BA_ "U_CD542_MY2021_Rx" SG_ 259 SDARS_CurrCATlstSize_Rq 1;
BA_ "U_T6_MCA_MY2020_Rx" SG_ 259 SDARS_CurrCATlstSize_Rq 1;
BA_ "U_P702_MY2021_Rx" SG_ 259 SDARS_CurrCATlstSize_Rq 1;
BA_ "U_U55X_MY2022_Tx" SG_ 259 SDARS_CurrCATlistInd_Rq 1;
BA_ "U_CD542_MY2021_Tx" SG_ 259 SDARS_CurrCATlistInd_Rq 1;
BA_ "U_T6_MCA_MY2020_Tx" SG_ 259 SDARS_CurrCATlistInd_Rq 1;
BA_ "U_P702_MY2021_Tx" SG_ 259 SDARS_CurrCATlistInd_Rq 1;
BA_ "U_CD542_MY2021_Rx" SG_ 259 SDARS_CurrCATlistInd_Rq 1;
BA_ "U_T6_MCA_MY2020_Rx" SG_ 259 SDARS_CurrCATlistInd_Rq 1;
BA_ "U_P702_MY2021_Rx" SG_ 259 SDARS_CurrCATlistInd_Rq 1;
BA_ "GenSigSendType" SG_ 259 SDARS_CurrCATlistInd_Rq 3;
BA_ "U_U55X_MY2022_Tx" SG_ 259 SDARS_ChipControl_Rq 1;
BA_ "U_CD542_MY2021_Tx" SG_ 259 SDARS_ChipControl_Rq 1;
BA_ "U_T6_MCA_MY2020_Tx" SG_ 259 SDARS_ChipControl_Rq 1;
BA_ "U_P702_MY2021_Tx" SG_ 259 SDARS_ChipControl_Rq 1;
BA_ "U_U55X_MY2022_Rx" SG_ 259 SDARS_ChipControl_Rq 1;
BA_ "U_CD542_MY2021_Rx" SG_ 259 SDARS_ChipControl_Rq 1;
BA_ "U_T6_MCA_MY2020_Rx" SG_ 259 SDARS_ChipControl_Rq 1;
BA_ "U_P702_MY2021_Rx" SG_ 259 SDARS_ChipControl_Rq 1;
BA_ "GenSigSendType" SG_ 259 SDARS_ChipControl_Rq 3;
BA_ "U_U55X_MY2022_Tx" SG_ 259 SDARS_AlertStatus_Rq 1;
BA_ "U_CD542_MY2021_Tx" SG_ 259 SDARS_AlertStatus_Rq 1;
BA_ "U_T6_MCA_MY2020_Tx" SG_ 259 SDARS_AlertStatus_Rq 1;
BA_ "U_P702_MY2021_Tx" SG_ 259 SDARS_AlertStatus_Rq 1;
BA_ "U_CD542_MY2021_Rx" SG_ 259 SDARS_AlertStatus_Rq 1;
BA_ "U_T6_MCA_MY2020_Rx" SG_ 259 SDARS_AlertStatus_Rq 1;
BA_ "U_P702_MY2021_Rx" SG_ 259 SDARS_AlertStatus_Rq 1;
BA_ "GenSigSendType" SG_ 259 SDARS_AlertStatus_Rq 3;
BA_ "U_U55X_MY2022_Tx" SG_ 538 MK_UserMyKeyCount_St 1;
BA_ "U_CD542_MY2021_Tx" SG_ 538 MK_UserMyKeyCount_St 1;
BA_ "U_T6_MCA_MY2020_Tx" SG_ 538 MK_UserMyKeyCount_St 1;
BA_ "U_CD542_MY2021_Rx" SG_ 538 MK_UserMyKeyCount_St 1;
BA_ "U_U55X_MY2022_Rx" SG_ 538 MK_UserMyKeyCount_St 1;
BA_ "U_T6_MCA_MY2020_Rx" SG_ 538 MK_UserMyKeyCount_St 1;
BA_ "U_P702_MY2021_Rx" SG_ 538 MK_UserMyKeyCount_St 1;
BA_ "GenSigSendType" SG_ 538 MK_UserMyKeyCount_St 3;
BA_ "U_U55X_MY2022_Tx" SG_ 538 MK_SpeedMinderConf_St 1;
BA_ "U_CD542_MY2021_Tx" SG_ 538 MK_SpeedMinderConf_St 1;
BA_ "U_T6_MCA_MY2020_Tx" SG_ 538 MK_SpeedMinderConf_St 1;
BA_ "U_CD542_MY2021_Rx" SG_ 538 MK_SpeedMinderConf_St 1;
BA_ "U_U55X_MY2022_Rx" SG_ 538 MK_SpeedMinderConf_St 1;
BA_ "U_T6_MCA_MY2020_Rx" SG_ 538 MK_SpeedMinderConf_St 1;
BA_ "U_P702_MY2021_Rx" SG_ 538 MK_SpeedMinderConf_St 1;
BA_ "GenSigSendType" SG_ 538 MK_SpeedMinderConf_St 3;
BA_ "U_U55X_MY2022_Tx" SG_ 538 MK_SpeedLimitConf_St 1;
BA_ "U_CD542_MY2021_Tx" SG_ 538 MK_SpeedLimitConf_St 1;
BA_ "U_T6_MCA_MY2020_Tx" SG_ 538 MK_SpeedLimitConf_St 1;
BA_ "U_CD542_MY2021_Rx" SG_ 538 MK_SpeedLimitConf_St 1;
BA_ "U_U55X_MY2022_Rx" SG_ 538 MK_SpeedLimitConf_St 1;
BA_ "U_T6_MCA_MY2020_Rx" SG_ 538 MK_SpeedLimitConf_St 1;
BA_ "U_P702_MY2021_Rx" SG_ 538 MK_SpeedLimitConf_St 1;
BA_ "GenSigSendType" SG_ 538 MK_SpeedLimitConf_St 3;
BA_ "U_U55X_MY2022_Tx" SG_ 538 MK_ESCRestrictConf_St 1;
BA_ "U_CD542_MY2021_Tx" SG_ 538 MK_ESCRestrictConf_St 1;
BA_ "U_T6_MCA_MY2020_Tx" SG_ 538 MK_ESCRestrictConf_St 1;
BA_ "GenSigSendType" SG_ 538 MK_ESCRestrictConf_St 3;
BA_ "U_U55X_MY2022_Tx" SG_ 538 MK_ECalRestrictConf_St 1;
BA_ "U_CD542_MY2021_Tx" SG_ 538 MK_ECalRestrictConf_St 1;
BA_ "U_T6_MCA_MY2020_Tx" SG_ 538 MK_ECalRestrictConf_St 1;
BA_ "U_CD542_MY2021_Rx" SG_ 538 MK_ECalRestrictConf_St 1;
BA_ "U_U55X_MY2022_Rx" SG_ 538 MK_ECalRestrictConf_St 1;
BA_ "U_T6_MCA_MY2020_Rx" SG_ 538 MK_ECalRestrictConf_St 1;
BA_ "U_P702_MY2021_Rx" SG_ 538 MK_ECalRestrictConf_St 1;
BA_ "GenSigSendType" SG_ 538 MK_ECalRestrictConf_St 3;
BA_ "U_U55X_MY2022_Tx" SG_ 538 MK_DNDRestrictConf_St 1;
BA_ "U_CD542_MY2021_Tx" SG_ 538 MK_DNDRestrictConf_St 1;
BA_ "U_T6_MCA_MY2020_Tx" SG_ 538 MK_DNDRestrictConf_St 1;
BA_ "U_CD542_MY2021_Rx" SG_ 538 MK_DNDRestrictConf_St 1;
BA_ "U_U55X_MY2022_Rx" SG_ 538 MK_DNDRestrictConf_St 1;
BA_ "U_T6_MCA_MY2020_Rx" SG_ 538 MK_DNDRestrictConf_St 1;
BA_ "U_P702_MY2021_Rx" SG_ 538 MK_DNDRestrictConf_St 1;
BA_ "GenSigSendType" SG_ 538 MK_DNDRestrictConf_St 3;
BA_ "U_U55X_MY2022_Tx" SG_ 538 MK_AudioLimitConfig_St 1;
BA_ "U_CD542_MY2021_Tx" SG_ 538 MK_AudioLimitConfig_St 1;
BA_ "U_T6_MCA_MY2020_Tx" SG_ 538 MK_AudioLimitConfig_St 1;
BA_ "U_CD542_MY2021_Rx" SG_ 538 MK_AudioLimitConfig_St 1;
BA_ "U_U55X_MY2022_Rx" SG_ 538 MK_AudioLimitConfig_St 1;
BA_ "U_T6_MCA_MY2020_Rx" SG_ 538 MK_AudioLimitConfig_St 1;
BA_ "U_P702_MY2021_Rx" SG_ 538 MK_AudioLimitConfig_St 1;
BA_ "GenSigSendType" SG_ 538 MK_AudioLimitConfig_St 3;
BA_ "U_U55X_MY2022_Tx" SG_ 538 MK_AdminMyKeyCount_St 1;
BA_ "U_CD542_MY2021_Tx" SG_ 538 MK_AdminMyKeyCount_St 1;
BA_ "U_T6_MCA_MY2020_Tx" SG_ 538 MK_AdminMyKeyCount_St 1;
BA_ "U_CD542_MY2021_Rx" SG_ 538 MK_AdminMyKeyCount_St 1;
BA_ "U_U55X_MY2022_Rx" SG_ 538 MK_AdminMyKeyCount_St 1;
BA_ "U_T6_MCA_MY2020_Rx" SG_ 538 MK_AdminMyKeyCount_St 1;
BA_ "U_P702_MY2021_Rx" SG_ 538 MK_AdminMyKeyCount_St 1;
BA_ "GenSigSendType" SG_ 538 MK_AdminMyKeyCount_St 3;
BA_ "U_U55X_MY2022_Tx" SG_ 422 MK_UserMyKeyCount_Rsp 1;
BA_ "U_CD542_MY2021_Tx" SG_ 422 MK_UserMyKeyCount_Rsp 1;
BA_ "U_T6_MCA_MY2020_Tx" SG_ 422 MK_UserMyKeyCount_Rsp 1;
BA_ "U_CD542_MY2021_Rx" SG_ 422 MK_UserMyKeyCount_Rsp 1;
BA_ "U_U55X_MY2022_Rx" SG_ 422 MK_UserMyKeyCount_Rsp 1;
BA_ "U_T6_MCA_MY2020_Rx" SG_ 422 MK_UserMyKeyCount_Rsp 1;
BA_ "U_P702_MY2021_Rx" SG_ 422 MK_UserMyKeyCount_Rsp 1;
BA_ "GenSigSendType" SG_ 422 MK_UserMyKeyCount_Rsp 3;
BA_ "U_U55X_MY2022_Tx" SG_ 422 MK_MyKeyDrivenKm_Rsp 1;
BA_ "U_CD542_MY2021_Tx" SG_ 422 MK_MyKeyDrivenKm_Rsp 1;
BA_ "U_T6_MCA_MY2020_Tx" SG_ 422 MK_MyKeyDrivenKm_Rsp 1;
BA_ "U_CD542_MY2021_Rx" SG_ 422 MK_MyKeyDrivenKm_Rsp 1;
BA_ "U_U55X_MY2022_Rx" SG_ 422 MK_MyKeyDrivenKm_Rsp 1;
BA_ "U_T6_MCA_MY2020_Rx" SG_ 422 MK_MyKeyDrivenKm_Rsp 1;
BA_ "U_P702_MY2021_Rx" SG_ 422 MK_MyKeyDrivenKm_Rsp 1;
BA_ "GenSigSendType" SG_ 422 MK_MyKeyDrivenKm_Rsp 3;
BA_ "U_U55X_MY2022_Tx" SG_ 422 MK_CreateMyKey_Rsp 1;
BA_ "U_CD542_MY2021_Tx" SG_ 422 MK_CreateMyKey_Rsp 1;
BA_ "U_T6_MCA_MY2020_Tx" SG_ 422 MK_CreateMyKey_Rsp 1;
BA_ "U_CD542_MY2021_Rx" SG_ 422 MK_CreateMyKey_Rsp 1;
BA_ "U_U55X_MY2022_Rx" SG_ 422 MK_CreateMyKey_Rsp 1;
BA_ "U_T6_MCA_MY2020_Rx" SG_ 422 MK_CreateMyKey_Rsp 1;
BA_ "U_P702_MY2021_Rx" SG_ 422 MK_CreateMyKey_Rsp 1;
BA_ "GenSigSendType" SG_ 422 MK_CreateMyKey_Rsp 3;
BA_ "U_U55X_MY2022_Tx" SG_ 422 MK_AdminMyKeyCount_Rsp 1;
BA_ "U_CD542_MY2021_Tx" SG_ 422 MK_AdminMyKeyCount_Rsp 1;
BA_ "U_T6_MCA_MY2020_Tx" SG_ 422 MK_AdminMyKeyCount_Rsp 1;
BA_ "U_CD542_MY2021_Rx" SG_ 422 MK_AdminMyKeyCount_Rsp 1;
BA_ "U_U55X_MY2022_Rx" SG_ 422 MK_AdminMyKeyCount_Rsp 1;
BA_ "U_T6_MCA_MY2020_Rx" SG_ 422 MK_AdminMyKeyCount_Rsp 1;
BA_ "U_P702_MY2021_Rx" SG_ 422 MK_AdminMyKeyCount_Rsp 1;
BA_ "GenSigSendType" SG_ 422 MK_AdminMyKeyCount_Rsp 3;
BA_ "U_U55X_MY2022_Tx" SG_ 1020 CtrStkPersIndex2_D_Actl 1;
BA_ "U_CD542_MY2021_Tx" SG_ 1020 CtrStkPersIndex2_D_Actl 1;
BA_ "U_CD542_MY2021_Rx" SG_ 1020 CtrStkPersIndex2_D_Actl 1;
BA_ "GenSigSendType" SG_ 1020 CtrStkPersIndex2_D_Actl 3;
BA_ "GenSigStartValue" SG_ 1020 CtrStkPersIndex2_D_Actl 4;
BA_ "GenSigStartValueInteger" SG_ 1020 CtrStkPersIndex2_D_Actl 4;
BA_ "U_U55X_MY2022_Tx" SG_ 1020 CtrStkFeatConfig2Actl 1;
BA_ "U_CD542_MY2021_Tx" SG_ 1020 CtrStkFeatConfig2Actl 1;
BA_ "U_CD542_MY2021_Rx" SG_ 1020 CtrStkFeatConfig2Actl 1;
BA_ "GenSigSendType" SG_ 1020 CtrStkFeatConfig2Actl 3;
BA_ "U_U55X_MY2022_Tx" SG_ 1020 CtrStkFeat2NoActl 1;
BA_ "U_CD542_MY2021_Tx" SG_ 1020 CtrStkFeat2NoActl 1;
BA_ "U_CD542_MY2021_Rx" SG_ 1020 CtrStkFeat2NoActl 1;
BA_ "GenSigSendType" SG_ 1020 CtrStkFeat2NoActl 3;
BA_ "U_U55X_MY2022_Tx" SG_ 1020 CtrStkDsplyOp2_D_Rq 1;
BA_ "U_CD542_MY2021_Tx" SG_ 1020 CtrStkDsplyOp2_D_Rq 1;
BA_ "U_CD542_MY2021_Rx" SG_ 1020 CtrStkDsplyOp2_D_Rq 1;
BA_ "GenSigSendType" SG_ 1020 CtrStkDsplyOp2_D_Rq 3;
BA_ "U_CD542_MY2021_Tx" SG_ 1007 PersIndexIpc2_D_Actl 1;
BA_ "U_U55X_MY2022_Rx" SG_ 1007 PersIndexIpc2_D_Actl 1;
BA_ "GenSigSendType" SG_ 1007 PersIndexIpc2_D_Actl 3;
BA_ "GenSigStartValue" SG_ 1007 PersIndexIpc2_D_Actl 4;
BA_ "GenSigStartValueInteger" SG_ 1007 PersIndexIpc2_D_Actl 4;
BA_ "U_CD542_MY2021_Tx" SG_ 1007 FeatNoIpc2Actl 1;
BA_ "U_U55X_MY2022_Rx" SG_ 1007 FeatNoIpc2Actl 1;
BA_ "GenSigSendType" SG_ 1007 FeatNoIpc2Actl 3;
BA_ "U_CD542_MY2021_Tx" SG_ 1007 FeatConfigIpc2Actl 1;
BA_ "U_U55X_MY2022_Rx" SG_ 1007 FeatConfigIpc2Actl 1;
BA_ "GenSigSendType" SG_ 1007 FeatConfigIpc2Actl 3;
VAL_ 1001 AirSuspMsgTxt_D_Rq2 3 "NotUsed" 2 "Faulty" 1 "Override" 0 "NoMessage" ;
VAL_ 1001 PersIndexSuma_D_Actl 7 "Unused_3" 6 "Unused_2" 5 "Unused_1" 4 "Vehicle" 3 "PERS_4" 2 "PERS_3" 1 "PERS_2" 0 "PERS_1" ;
VAL_ 1245 RearDiffLckLamp_D_Cstm 3 "Not_Used" 2 "Flash" 1 "On" 0 "Off" ;
VAL_ 1245 FrontDiffLckLamp_D_Cstm 3 "Fast_Flash" 2 "Slow_Flash" 1 "On" 0 "Off" ;
VAL_ 1245 AwdMdeCstm_D_RqDrv 7 "Faulty" 6 "NotUsed_3" 5 "NotUsed_2" 4 "NotUsed_1" 3 "FourByFourLow" 2 "FourByFourHigh" 1 "FourByFourAuto" 0 "FourByTwo" ;
VAL_ 1245 SelDrvMdeAwd2_D_Cstm 31 "Faulty" 30 "NotUsed_17" 29 "NotUsed_16" 28 "NotUsed_15" 27 "NotUsed_14" 26 "NotUsed_13" 25 "NotUsed_12" 24 "NotUsed_11" 23 "NotUsed_10" 22 "NotUsed_9" 21 "NotUsed_8" 20 "CustomMode" 19 "OnePedalDrive" 18 "DragMode" 17 "EvLaterChargeMode" 16 "EvNowMode" 15 "TrackMode" 14 "RoughRoadMode" 13 "NotAvailable" 12 "HighSpeedDesertMode_Baja" 11 "SportAdaptiveMode" 10 "RockCrawlMode" 9 "MudRutsMode" 8 "SandMode" 7 "EconomyMode" 6 "GrassGravelSnow" 5 "TowHaulMode" 4 "SportMode" 3 "Normal_4L" 2 "Normal_4A" 1 "Normal_2H" 0 "NormalMode" ;
VAL_ 1242 EngExhMdeQuietCstm_D_Rq 7 "Faulty" 6 "NotUsed_2" 5 "NotUsed_1" 4 "Track" 3 "Sport" 2 "Normal" 1 "Stealth" 0 "Null" ;
VAL_ 1242 StopStrtCstm_D_Rq 3 "Faulty" 2 "On" 1 "Off" 0 "NotAvailable" ;
VAL_ 1242 SelDrvMdeCstmPt_D_Rq 31 "Faulty" 30 "NotUsed15" 29 "NotUsed14" 28 "NotUsed13" 27 "NotUsed12" 26 "NotUsed11" 25 "NotUsed10" 24 "NotUsed9" 23 "NotUsed8" 22 "NotUsed7" 21 "CustomMode" 20 "TrackMode" 19 "OnePedalDrive" 18 "EvLaterChargerMode" 17 "EvNowMode" 16 "DragMode" 15 "HighSpeedDesertMode_Baja" 14 "SportAdaptiveMode" 13 "NotAvailable_13" 12 "NotAvailable_12" 11 "NotAvailable_11" 10 "NotAvailable_10" 9 "RockCrawlMode" 8 "MudRutsMode" 7 "SandMode" 6 "EconomyMode" 5 "GrassGravelSnow" 4 "NotAvailable_04" 3 "TowHaulMode" 2 "NotAvailable_02" 1 "SportMode" 0 "NormalMode" ;
VAL_ 1022 TrlrTireTSensIRM_D_Stat 3 "Faulty" 2 "HighTempWarning" 1 "Normal" 0 "NotAvailable" ;
VAL_ 1022 TrlrTireTSensIRF_D_Stat 3 "Faulty" 2 "HighTempWarning" 1 "Normal" 0 "NotAvailable" ;
VAL_ 1022 TrlrTireIRR_T_Actl 255 "NotSupported" 254 "Invalid" ;
VAL_ 1022 TrlrTireIRM_T_Actl 255 "NotSupported" 254 "Invalid" ;
VAL_ 1022 TrlrTireILR_T_Actl 255 "NotSupported" 254 "Invalid" ;
VAL_ 1022 TrlrTireILM_T_Actl 255 "NotSupported" 254 "Invalid" ;
VAL_ 1022 TrlrTireILF_T_Actl 255 "NotSupported" 254 "Invalid" ;
VAL_ 1022 TrlrTireIRF_T_Actl 255 "NotSupported" 254 "Invalid" ;
VAL_ 1022 TrlrTireTSensIRR_D_Stat 3 "Faulty" 2 "HighTempWarning" 1 "Normal" 0 "NotAvailable" ;
VAL_ 1022 TrlrTireTSensILR_D_Stat 3 "Faulty" 2 "HighTempWarning" 1 "Normal" 0 "NotAvailable" ;
VAL_ 1022 TrlrTireTSensILM_D_Stat 3 "Faulty" 2 "HighTempWarning" 1 "Normal" 0 "NotAvailable" ;
VAL_ 1022 TrlrTireTSensILF_D_Stat 3 "Faulty" 2 "HighTempWarning" 1 "Normal" 0 "NotAvailable" ;
VAL_ 1021 TrlrTireSensIRR_D_Stat 15 "NotSupported" 14 "NotUsed10" 13 "NotUsed9" 12 "NotUsed8" 11 "NotUsed7" 10 "NotUsed6" 9 "NotUsed5" 8 "NotUsed4" 7 "NotUsed3" 6 "NotUsed2" 5 "NotUsed1" 4 "Alert" 3 "Fault" 2 "Low" 1 "Normal" 0 "Unknown" ;
VAL_ 1021 TrlrTireSensIRM_D_Stat 15 "NotSupported" 14 "NotUsed10" 13 "NotUsed9" 12 "NotUsed8" 11 "NotUsed7" 10 "NotUsed6" 9 "NotUsed5" 8 "NotUsed4" 7 "NotUsed3" 6 "NotUsed2" 5 "NotUsed1" 4 "Alert" 3 "Fault" 2 "Low" 1 "Normal" 0 "Unknown" ;
VAL_ 1021 TrlrTireSensIRF_D_Stat 15 "NotSupported" 14 "NotUsed10" 13 "NotUsed9" 12 "NotUsed8" 11 "NotUsed7" 10 "NotUsed6" 9 "NotUsed5" 8 "NotUsed4" 7 "NotUsed3" 6 "NotUsed2" 5 "NotUsed1" 4 "Alert" 3 "Fault" 2 "Low" 1 "Normal" 0 "Unknown" ;
VAL_ 1021 TrlrTireIRR_P_Actl 65534 "Invalid" 65535 "NotSupported" ;
VAL_ 1021 TrlrTireIRM_P_Actl 65534 "Invalid" 65535 "NotSupported" ;
VAL_ 1021 TrlrTireIRF_P_Actl 65534 "Invalid" 65535 "NotSupported" ;
VAL_ 1018 TrlrTireSensIRF_D_Stat 15 "NotSupported" 14 "NotUsed10" 13 "NotUsed9" 12 "NotUsed8" 11 "NotUsed7" 10 "NotUsed6" 9 "NotUsed5" 8 "NotUsed4" 7 "NotUsed3" 6 "NotUsed2" 5 "NotUsed1" 4 "Alert" 3 "Fault" 2 "Low" 1 "Normal" 0 "Unknown" ;
VAL_ 1018 TrlrTireSensILM_D_Stat 15 "NotSupported" 14 "NotUsed10" 13 "NotUsed9" 12 "NotUsed8" 11 "NotUsed7" 10 "NotUsed6" 9 "NotUsed5" 8 "NotUsed4" 7 "NotUsed3" 6 "NotUsed2" 5 "NotUsed1" 4 "Alert" 3 "Fault" 2 "Low" 1 "Normal" 0 "Unknown" ;
VAL_ 1018 TrlrTireSensILF_D_Stat 15 "NotSupported" 14 "NotUsed10" 13 "NotUsed9" 12 "NotUsed8" 11 "NotUsed7" 10 "NotUsed6" 9 "NotUsed5" 8 "NotUsed4" 7 "NotUsed3" 6 "NotUsed2" 5 "NotUsed1" 4 "Alert" 3 "Fault" 2 "Low" 1 "Normal" 0 "Unknown" ;
VAL_ 1018 TrlrTireILR_P_Actl 65534 "Invalid" 65535 "NotSupported" ;
VAL_ 1018 TrlrTireILM_P_Actl 65534 "Invalid" 65535 "NotSupported" ;
VAL_ 1018 TrlrTireILF_P_Actl 65534 "Invalid" 65535 "NotSupported" ;
VAL_ 502 Dsp_FolderContent_Rq 2 "Inactive" 1 "RequestContentFromParentFolderOf" 0 "RequestContentFromParameterFolde" ;
VAL_ 502 Dsp_CutItem2_Rq 3 "Inactive" 2 "ThreeQuarterFromTheBeginningOneQ" 1 "End" 0 "Beginning" ;
VAL_ 502 Dsp_AudioSourceSel2_Rq 4 "Reserved" 3 "USB" 2 "BTAudio" 1 "CD" 0 "Inactive" ;
VAL_ 955 Tire_Temp_RF_Data 255 "NotSupported" 254 "Invalid" ;
VAL_ 955 Tire_Temp_ORR_Data 255 "NotSupported" 254 "Invalid" ;
VAL_ 955 Tire_Temp_OLR_Data 255 "NotSupported" 254 "Invalid" ;
VAL_ 955 Tire_Temp_LF_Data 255 "NotSupported" 254 "Invalid" ;
VAL_ 955 Tire_Temp_IRR_Data 255 "NotSupported" 254 "Invalid" ;
VAL_ 955 Tire_Temp_ILR_Data 255 "NotSupported" 254 "Invalid" ;
VAL_ 1116 TrlrAidSetup_D2_Rq 15 "NotUsed_9" 14 "NotUsed_8" 13 "NotUsed_7" 12 "NotUsed_6" 11 "NotUsed_5" 10 "NotUsed_4" 9 "NotUsed_3" 8 "NotUsed_2" 7 "NotUsed_1" 6 "CompleteSetup" 5 "ReturnToSetup" 4 "StickerNotCircled" 3 "ConfirmSetup" 2 "EndSetup" 1 "BeginSetup" 0 "Inactive" ;
VAL_ 1116 TrlrAidEnbl_D2_Rq 7 "NotUsed_4" 6 "NotUsed_3" 5 "NotUsed_2" 4 "NotUsed_1" 3 "Deactivate" 2 "ActivateTrg" 1 "ActivateTba" 0 "Inactive" ;
VAL_ 1116 TlightTest_D_Mnu 3 "TestEndAcknowledge" 2 "StartTest" 1 "StopTest" 0 "Null" ;
VAL_ 1116 TrlrRvrseCancl_B_Rq 1 "Cancel" 0 "Null" ;
VAL_ 1116 TrlrIdType_D_Stat 3 "Gooseneck" 2 "FifthWheel" 1 "Conventional" 0 "Null" ;
VAL_ 1116 TrlrAnOffstDir_D_Mem 3 "NotUSed" 2 "Right" 1 "Left_or_Center" 0 "Null" ;
VAL_ 1113 TrlrAnOffstDir_D_Calc_UB 1 "Fresh_data" 0 "Unchanged_data" ;
VAL_ 1113 TrlrAnOffst_An_Calc_UB 1 "Fresh_data" 0 "Unchanged_data" ;
VAL_ 1113 TrlrAnCalib_B_Complt_UB 1 "Fresh_data" 0 "Unchanged_data" ;
VAL_ 1113 TrlrAidTrgtId_No_Actl_UB 1 "Fresh_data" 0 "Unchanged_data" ;
VAL_ 1113 TrlrAnCalib_B_Complt 1 "Yes" 0 "No" ;
VAL_ 1113 TrlrAnOffstDir_D_Calc 3 "NotUSed" 2 "Right" 1 "Left_or_Center" 0 "Null" ;
VAL_ 1113 immoSecureIdleMode_UB 1 "Fresh_data" 0 "Unchanged_data" ;
VAL_ 1113 immoSecureIdleMode 3 "NotUsed2" 2 "NotUsed1" 1 "Active" 0 "Inactive" ;
VAL_ 1255 BalrRight4Threat_D_Stat 1 "Yes" 0 "No" ;
VAL_ 1255 BalrRight4Fast_B_Stat 1 "Yes" 0 "No" ;
VAL_ 1255 BalrRight4Dsply_B_Stat 1 "Yes" 0 "No" ;
VAL_ 1254 BalrRight3Threat_D_Stat 1 "Yes" 0 "No" ;
VAL_ 1254 BalrRight3Fast_B_Stat 1 "Yes" 0 "No" ;
VAL_ 1254 BalrRight3Dsply_B_Stat 1 "Yes" 0 "No" ;
VAL_ 1253 BalrRight2Threat_D_Stat 1 "Yes" 0 "No" ;
VAL_ 1253 BalrRight2Fast_B_Stat 1 "Yes" 0 "No" ;
VAL_ 1253 BalrRight2Dsply_B_Stat 1 "Yes" 0 "No" ;
VAL_ 1252 BalrRight1Threat_D_Stat 1 "Yes" 0 "No" ;
VAL_ 1252 BalrRight1Fast_B_Stat 1 "Yes" 0 "No" ;
VAL_ 1252 BalrRight1Dsply_B_Stat 1 "Yes" 0 "No" ;
VAL_ 1251 BalrLeft4Threat_D_Stat 1 "Yes" 0 "No" ;
VAL_ 1251 BalrLeft4Fast_B_Stat 1 "Yes" 0 "No" ;
VAL_ 1251 BalrLeft4Dsply_B_Stat 1 "Yes" 0 "No" ;
VAL_ 1250 BalrLeft3Threat_D_Stat 1 "Yes" 0 "No" ;
VAL_ 1250 BalrLeft3Fast_B_Stat 1 "Yes" 0 "No" ;
VAL_ 1250 BalrLeft3Dsply_B_Stat 1 "Yes" 0 "No" ;
VAL_ 1249 BalrLeft2Threat_D_Stat 1 "Yes" 0 "No" ;
VAL_ 1249 BalrLeft2Fast_B_Stat 1 "Yes" 0 "No" ;
VAL_ 1249 BalrLeft2Dsply_B_Stat 1 "Yes" 0 "No" ;
VAL_ 1248 BalrLeft1Threat_D_Stat 1 "Yes" 0 "No" ;
VAL_ 1248 BalrLeft1Fast_B_Stat 1 "Yes" 0 "No" ;
VAL_ 1248 BalrLeft1Dsply_B_Stat 1 "Yes" 0 "No" ;
VAL_ 1256 StopLamp_B_RqTrlrAft_UB 1 "Fresh_data" 0 "Unchanged_data" ;
VAL_ 1256 StopLamp_B_RqTrlrAft 1 "True" 0 "False" ;
VAL_ 1256 BalrMdeRight_D_Stat_UB 1 "Fresh_data" 0 "Unchanged_data" ;
VAL_ 1256 BalrMdeSelRight_B_Stat_UB 1 "Fresh_data" 0 "Unchanged_data" ;
VAL_ 1256 BalrRight_D_Stat_UB 1 "Fresh_data" 0 "Unchanged_data" ;
VAL_ 1256 BalrLckRight_B_Stat_UB 1 "Fresh_data" 0 "Unchanged_data" ;
VAL_ 1256 BalrChimeRight_D_Rq_UB 1 "Fresh_data" 0 "Unchanged_data" ;
VAL_ 1256 BalrSnsRight_D_Falt_UB 1 "Fresh_data" 0 "Unchanged_data" ;
VAL_ 1256 BalrWndwRight_B_Stat_UB 1 "Fresh_data" 0 "Unchanged_data" ;
VAL_ 1256 BalrLckRight_B_Stat 1 "Enable" 0 "Disable" ;
VAL_ 1256 BalrWndwRight_B_Stat 1 "Enable" 0 "Disable" ;
VAL_ 1256 BalrMdeSelRight_B_Stat 1 "Enable" 0 "Disable" ;
VAL_ 1256 BalrSnsRight_D_Falt 3 "Invalid" 2 "SystemFailure" 1 "Blocked" 0 "Clear" ;
VAL_ 1256 BalrChimeRight_D_Rq 3 "NotUsed" 2 "Soft" 1 "Normal" 0 "Off" ;
VAL_ 1256 BalrMdeRight_D_Stat 3 "NotUsed" 2 "High" 1 "Medium" 0 "Low" ;
VAL_ 1256 BalrRight_D_Stat 3 "Inhibited" 2 "Disabled" 1 "On" 0 "Off" ;
VAL_ 1256 BalrWndwLeft_B_Stat_UB 1 "Fresh_data" 0 "Unchanged_data" ;
VAL_ 1256 BalrSnsLeft_D_Falt_UB 1 "Fresh_data" 0 "Unchanged_data" ;
VAL_ 1256 BalrMdeSelLeft_B_Stat_UB 1 "Fresh_data" 0 "Unchanged_data" ;
VAL_ 1256 BalrMdeLeft_D_Stat_UB 1 "Fresh_data" 0 "Unchanged_data" ;
VAL_ 1256 BalrLeft_D_Stat_UB 1 "Fresh_data" 0 "Unchanged_data" ;
VAL_ 1256 BalrLckLeft_B_Stat_UB 1 "Fresh_data" 0 "Unchanged_data" ;
VAL_ 1256 BalrChimeLeft_D_Rq_UB 1 "Fresh_data" 0 "Unchanged_data" ;
VAL_ 1256 BalrLeft_D_Stat 3 "Inhibited" 2 "Disabled" 1 "On" 0 "Off" ;
VAL_ 1256 BalrMdeSelLeft_B_Stat 1 "Enable" 0 "Disable" ;
VAL_ 1256 BalrLckLeft_B_Stat 1 "Enable" 0 "Disable" ;
VAL_ 1256 BalrWndwLeft_B_Stat 1 "Enable" 0 "Disable" ;
VAL_ 1256 BalrMdeLeft_D_Stat 3 "NotUsed" 2 "High" 1 "Medium" 0 "Low" ;
VAL_ 1256 BalrSnsLeft_D_Falt 3 "Invalid" 2 "SystemFailure" 1 "Blocked" 0 "Clear" ;
VAL_ 1256 BalrChimeLeft_D_Rq 3 "NotUsed" 2 "Soft" 1 "Normal" 0 "Off" ;
VAL_ 1256 WakeAlarm2_D_Stat_UB 1 "Fresh_data" 0 "Unchanged_data" ;
VAL_ 1256 WakeAlarm2_D_Stat 3 "PublisherReset" 2 "Wake" 1 "AlarmRunning" 0 "AlarmOff" ;
VAL_ 529 OnbChrgToPcWknd_D_Actl 7 "Percent_50" 6 "Percent_60" 5 "Percent_70" 4 "Percent_80" 3 "Percent_85" 2 "Percent_90" 1 "Percent_95" 0 "Percent_100" ;
VAL_ 529 OnbChrgToPcWkdy_D_Actl 7 "Percent_50" 6 "Percent_60" 5 "Percent_70" 4 "Percent_80" 3 "Percent_85" 2 "Percent_90" 1 "Percent_95" 0 "Percent_100" ;
VAL_ 529 OnbChrgSetNow_D_Rq 3 "NotUsed" 2 "On" 1 "Off" 0 "Null" ;
VAL_ 529 OnbChrgSetDelete_B_Rq 1 "Request" 0 "NoRequest" ;
VAL_ 529 OnbChrgPrflUpdate_B_Rq 1 "Request" 0 "NoRequest" ;
VAL_ 529 OnbChrgLocIdUns_B_Rq 1 "Request" 0 "NoRequest" ;
VAL_ 642 SldrrMsgTxt_D2_Rq_UB 1 "Fresh_data" 0 "Unchanged_data" ;
VAL_ 642 SldrrMsgTxt_D2_Rq 7 "NotUsed_3" 6 "NotUsed_2" 5 "NotUsed_1" 4 "SlidingDrCalibNeeded2" 3 "SlidingDrOpenCltchReleased" 2 "SlidingDrCalibNeeded" 1 "SlidingDrClutchReleased" 0 "Null" ;
VAL_ 642 SldrrChime_D_Rq_UB 1 "Fresh_data" 0 "Unchanged_data" ;
VAL_ 642 SldrrChime_D_Rq 7 "NotUsed3" 6 "NotUsed2" 5 "NotUsed1" 4 "Warning" 3 "WarningRepeated" 2 "Programming" 1 "Operation" 0 "Off" ;
VAL_ 642 SldrlMsgTxt_D2_Rq_UB 1 "Fresh_data" 0 "Unchanged_data" ;
VAL_ 642 SldrlMsgTxt_D2_Rq 7 "NotUsed_3" 6 "NotUsed_2" 5 "NotUsed_1" 4 "SlidingDrCalibNeeded2" 3 "SlidingDrOpenCltchReleased" 2 "SlidingDrCalibNeeded" 1 "SlidingDrClutchReleased" 0 "Null" ;
VAL_ 642 SldrlChime_D_Rq_UB 1 "Fresh_data" 0 "Unchanged_data" ;
VAL_ 642 SldrlChime_D_Rq 7 "NotUsed3" 6 "NotUsed2" 5 "NotUsed1" 4 "Warning" 3 "WarningRepeated" 2 "Programming" 1 "Operation" 0 "Off" ;
VAL_ 642 PaakMyKeySearch_D_Stat_UB 1 "Fresh_data" 0 "Unchanged_data" ;
VAL_ 642 UreaLvlQlty_D_RqDsply_UB 1 "Fresh_data" 0 "Unchanged_data" ;
VAL_ 642 DieslPrtcWarn_D_Rq_UB 1 "Fresh_data" 0 "Unchanged_data" ;
VAL_ 642 UreaQltySysWarn_D_Rq_UB 1 "Fresh_data" 0 "Unchanged_data" ;
VAL_ 642 UreaLvlTxtWarn_D_Rq_UB 1 "Fresh_data" 0 "Unchanged_data" ;
VAL_ 642 UreaLvlQlty_D_RqDsply 7 "NotUsed_5" 6 "NotUsed_4" 5 "NotUsed_3" 4 "NotUsed_2" 3 "NotUsed_1" 2 "FlashChime" 1 "On" 0 "Off" ;
VAL_ 642 UreaLvlTxtWarn_D_Rq 15 "NotUsed_4" 14 "NotUsed_3" 13 "NotUsed_2" 12 "NotUsed_1" 11 "System_Error" 10 "Engine_Idled_See_Manual" 9 "Engine_Idled_Upon_Refuel" 8 "Speed_Limited_To_XX_mph" 7 "XXmph_Max_Upon_Restart" 6 "Speed_Limited_To_YY_mph" 5 "YYmph_Max_Upon_Restart" 4 "SpdLimtd_YYmph_In_XXmiles" 3 "ExFlRange_XXMiles_ScndWarn" 2 "Exh_Fluid_Range_XX_Miles" 1 "Exh_Fluid_Under_Half_Full" 0 "Exh_Fluid_Over_Half_Full" ;
VAL_ 642 UreaQltySysWarn_D_Rq 7 "Undefined" 6 "ZZ_Overrides" 5 "EngineIdled" 4 "Engine_Idle_Upon_Refuel" 3 "SPEED_LIMITED_to_YY_mph" 2 "YY_MPH_MAX_UPON_Restart" 1 "CONTAMINATED_ExhFluid" 0 "NoQualityProblem" ;
VAL_ 642 DieslPrtcWarn_D_Rq 15 "NotUsed_4" 14 "NotUsed_3" 13 "NotUsed_2" 12 "NotUsed_1" 11 "OCR_ExhFilterClean_Stopped" 10 "OCR_ExhFilterCleaned" 9 "RgnOff_AtLimit" 8 "RgnOff_OverLoaded" 7 "RgnOff_Loaded" 6 "Exhaust_Filter_Full" 5 "DPF_OverLimit" 4 "DPF_AtLimit" 3 "ExhFilter_Drive_Completed" 2 "Cleaning_Exhaust_Filter" 1 "DPF_OverLoaded" 0 "DPF_Normal_Operation" ;
VAL_ 642 KeyMyKeyTot_No2_Cnt_UB 1 "Fresh_data" 0 "Unchanged_data" ;
VAL_ 642 KeyAdmnTot_No2_Cnt_UB 1 "Fresh_data" 0 "Unchanged_data" ;
VAL_ 642 DcChrgSrvcRqd_B_Rq_UB 1 "Fresh_data" 0 "Unchanged_data" ;
VAL_ 642 DcChrgSrvcRqd_B_Rq 1 "On" 0 "Off" ;
VAL_ 642 PaakMyKeySearch_D_Stat 7 "PhoneErased" 6 "LockButtonTimeOut" 5 "PressLockButton" 4 "ConfirmHmi" 3 "MyKeyPaakFound" 2 "StandardPaakFound" 1 "NoValidPaakFound" 0 "Null" ;
VAL_ 642 GrdAsstActv_B_Stat_UB 1 "Fresh_data" 0 "Unchanged_data" ;
VAL_ 642 GrdAsstActv_B_Stat 1 "On" 0 "Off" ;
VAL_ 642 TrlrAidTrlrId_No_Rq_UB 1 "Fresh_data" 0 "Unchanged_data" ;
VAL_ 893 RngPerChrgAvg_L2_Dsply_UB 1 "Fresh_data" 0 "Unchanged_data" ;
VAL_ 893 RngImpctClim_L_Dsply_UB 1 "Fresh_data" 0 "Unchanged_data" ;
VAL_ 893 RngImpctDrv_L_Dsply_UB 1 "Fresh_data" 0 "Unchanged_data" ;
VAL_ 893 VehElEffAvg_No_Dsply_UB 1 "Fresh_data" 0 "Unchanged_data" ;
VAL_ 893 VehElEffAvg_No_Dsply 127 "Faulty" 126 "NoDataExists" ;
VAL_ 893 RngPerChrgAvg_L2_Dsply 8191 "Faulty" 8190 "NoDataExists" ;
VAL_ 893 TrnAout2_W_ActlUnfilt_UB 1 "Fresh_data" 0 "Unchanged_data" ;
VAL_ 893 TrnAout2_W_ActlUnfilt 65535 "Fault" 65534 "NoDataExists" ;
VAL_ 500 Dsp_GetCDTOCDData_Rq 0 "Inactive" 2 "Off" 1 "TOC" ;
VAL_ 500 Dsp_CutItem_Rq 3 "Inactive" 2 "ThreeQuarterFromTheBeginningOneQ" 1 "End" 0 "Beginning" ;
VAL_ 500 Dsp_AudioSourceSel_Rq 5 "SDCard" 4 "Reserved" 3 "USB" 2 "BTAudio" 1 "CD" 0 "Inactive" ;
VAL_ 503 Dsp_AudioSourceSel3_Rq 3 "USB" 2 "BTAudio" 1 "CD" 0 "Inactive" ;
VAL_ 493 Dsp_StatLiScanCancel_Rq 1 "Cancel" 0 "Inactive" ;
VAL_ 493 Dsp_StationList_Rq 15 "reserved_last" 8 "reserved" 7 "DAB_Service_List" 6 "DAB_Ensemble_Service_List" 5 "Analog_FM_PTY_List" 4 "Analog_and_HD_FM_List" 3 "HD_FM_List" 2 "Analog_FM_List" 1 "Analog_AM_List" 0 "Inactive" ;
VAL_ 493 Dsp_RefreshFlag 1 "True" 0 "False" ;
VAL_ 493 Dsp_AFJump_Rq 2 "Enable" 1 "Inhibit" 0 "Inactive" ;
VAL_ 511 SdarsAudioRtng_D_Rq 3 "NotUsed" 2 "APIMStereoOut" 1 "X40l2SStereoOut" 0 "Null" ;
VAL_ 511 Dsp_TUPresetArea_Rq 13 "reserved" 12 "GetSAT3PresetData" 11 "GetSAT2PresetData" 15 "reserved_last" 10 "GetSAT1PresetData" 9 "GetDAB2PresetData" 8 "GetDAB1PresetData" 7 "GetDAB3PresetData" 6 "GetAmPresetData" 5 "GetAmAstPresetData" 4 "GetFmAstPresetData" 3 "GetFm3PresetData" 2 "GetFm2PresetData" 1 "GetFm1PresetData" 0 "Inactive" ;
VAL_ 511 Dsp_SetCurrTUBand_Rq 13 "reserved1" 12 "DAB3" 11 "SAT3" 10 "SAT2" 15 "reserved_last" 9 "SAT1" 8 "DAB2" 7 "DAB1" 6 "AmAst" 5 "Am" 4 "FmAst" 3 "Fm3" 2 "Fm2" 1 "Fm1" 0 "Inactive" ;
VAL_ 257 MFD_SetTagMode 2 "On" 1 "Off" 0 "Inactive" ;
VAL_ 257 MFD_SetRBDSMode 2 "On" 1 "Off" 0 "Inactive" ;
VAL_ 257 MFD_SetHDModeRq 2 "On" 1 "Off" 0 "Inactive" ;
VAL_ 257 MFD_GetTagInfo 1 "TagInformation" 0 "Inactive" ;
VAL_ 382 EngMnfldChrg_Te_Actl 127 "Faulty" 126 "NoDataExists" ;
VAL_ 382 EngInnrClnt_Te_Actl 127 "Faulty" 126 "NoDataExists" ;
VAL_ 382 DcacOut2_Pw2_Dsply 8191 "Faulty" 8190 "NoDataExists" ;
VAL_ 382 DcacOut1_Pw2_Dsply 8191 "Faulty" 8190 "NoDataExists" ;
VAL_ 877 Rr_Third_Power_Btn_Stt 3 "Unused" 2 "Disabled" 1 "Active" 0 "Enabled_Inactive" ;
VAL_ 877 Rr_Third_Floor_Btn_Stt 3 "Unused" 2 "Disabled" 1 "Active" 0 "Enabled_Inactive" ;
VAL_ 877 Rr_Third_Auto_Btn_Stt 3 "Unused" 2 "Disabled" 1 "Active" 0 "Enabled_Inactive" ;
VAL_ 877 Rr_Lock_Btn_Stt 3 "Unused" 2 "Disabled" 1 "Active" 0 "Enabled_Inactive" ;
VAL_ 877 Rr_RHS_Blower_Indicate 15 "Display_Blank" 14 "14_Indicators_On" 13 "13_Indicators_On" 12 "12_Indicators_On" 11 "11_Indicators_On" 10 "10_Indicators_On" 9 "9_Indicators_On" 8 "8_Indicators_On" 7 "7_Indicators_On" 6 "6_Indicators_On" 5 "5_Indicators_On" 4 "4_Indicators_On" 3 "3_Indicators_On" 2 "2_Indicators_On" 1 "1_Indicator_On" 0 "Indicators_Off" ;
VAL_ 877 Rr_Third_Panel_Btn_Stt 3 "Unused" 2 "Disabled" 1 "Active" 0 "Enabled_Inactive" ;
VAL_ 877 Rr_Synch_Btn_Stt 3 "Unused" 2 "Disabled" 1 "Active" 0 "Enabled_Inactive" ;
VAL_ 877 AAR_Btn_Stt 3 "Unused" 2 "Disabled" 1 "Active" 0 "Enabled_Inactive" ;
VAL_ 877 Heat_Btn_Stt 3 "Unused" 2 "Disabled" 1 "Active" 0 "Enabled_Inactive" ;
VAL_ 414 LBS2_ListStatus 0 "Inactive" 1 "Valid" 2 "Updating" 3 "Reserved" ;
VAL_ 1239 StabBarCnnctLamp_D_Cstm 3 "Fast_Flash" 2 "Slow_Flash" 1 "On" 0 "Off" ;
VAL_ 1239 SelDrvMdeCstmLamp_D_Rq 3 "NotUsed2" 2 "NotUsed1" 1 "On" 0 "Off" ;
VAL_ 1239 SelDrvMdeCstm_D_RqDrv 7 "Faulty" 6 "NotUsed_3" 5 "NotUsed_2" 4 "NotUsed_1" 3 "Recall" 2 "Save" 1 "Activate" 0 "Null" ;
VAL_ 1239 CstmDrvMdeMsgTxt_D_Rq 15 "Message15" 14 "Message14" 13 "Message13" 12 "Message12" 11 "Message11" 10 "Message10" 9 "Message9" 8 "Message8" 7 "Message7" 6 "Message6" 5 "Message5" 4 "Message4" 3 "Message3" 2 "Message2" 1 "Message1" 0 "NoMessage" ;
VAL_ 1239 ActvDrvMdeCstm_D2_Rq 31 "Faulty" 30 "SelDrvMde31" 29 "SelDrvMde30" 28 "SelDrvMde29" 27 "SelDrvMde28" 26 "SelDrvMde27" 25 "SelDrvMde26" 24 "SelDrvMde25" 23 "SelDrvMde24" 22 "SelDrvMde23" 21 "SelDrvMde22" 20 "SelDrvMde21" 19 "SelDrvMde20" 18 "SelDrvMde19" 17 "SelDrvMde18" 16 "SelDrvMde17" 15 "SelDrvMde16" 14 "SelDrvMde15" 13 "SelDrvMde14" 12 "SelDrvMde13" 11 "SelDrvMde12" 10 "SelDrvMde11" 9 "SelDrvMde10" 8 "SelDrvMde09" 7 "SelDrvMde08" 6 "SelDrvMde07" 5 "SelDrvMde06" 4 "SelDrvMde05" 3 "SelDrvMde04" 2 "SelDrvMde03" 1 "SelDrvMde02" 0 "SelDrvMde01" ;
VAL_ 1013 ChrgToPcWkndSav_D_Stat 7 "Percent_50" 6 "Percent_60" 5 "Percent_70" 4 "Percent_80" 3 "Percent_85" 2 "Percent_90" 1 "Percent_95" 0 "Percent_100" ;
VAL_ 1013 ChrgToPcWkdySav_D_Stat 7 "Percent_50" 6 "Percent_60" 5 "Percent_70" 4 "Percent_80" 3 "Percent_85" 2 "Percent_90" 1 "Percent_95" 0 "Percent_100" ;
VAL_ 1013 ChrgNowEnbl_B_Saved 1 "On" 0 "Off" ;
VAL_ 1013 ChrgLocIdUnsAck_B_Stat 1 "Yes" 0 "No" ;
VAL_ 641 ChrgGoTElement_B_Dsply_UB 1 "Fresh_data" 0 "Unchanged_data" ;
VAL_ 641 ChrgGoTElement_B_Dsply 1 "Yes" 0 "No" ;
VAL_ 641 BattChrgTrgtSoC_D_Rq 7 "Percent_50" 6 "Percent_60" 5 "Percent_70" 4 "Percent_80" 3 "Percent_85" 2 "Percent_90" 1 "Percent_95" 0 "Percent_100" ;
VAL_ 641 BattChrgTrgtSoC_D_Rq_UB 1 "Fresh_data" 0 "Unchanged_data" ;
VAL_ 641 ChrgLocIdCurnt_D_Uns_UB 1 "Fresh_data" 0 "Unchanged_data" ;
VAL_ 641 IgnPsswrdActv_B_Stat_UB 1 "Fresh_data" 0 "Unchanged_data" ;
VAL_ 641 IgnPsswrdSetup_B_Rq_UB 1 "Fresh_data" 0 "Unchanged_data" ;
VAL_ 641 IgnPsswrdLckout_B_Stat_UB 1 "Fresh_data" 0 "Unchanged_data" ;
VAL_ 641 IgnPsswrdSetup_B_Rq 1 "Active" 0 "Inactive" ;
VAL_ 641 IgnPsswrdLckout_B_Stat 1 "Active" 0 "Inactive" ;
VAL_ 641 PaakCnnct_D_Stat_UB 1 "Fresh_data" 0 "Unchanged_data" ;
VAL_ 641 PaakCnnct_D_Stat 3 "NotUsed" 2 "Connected" 1 "NotConnected" 0 "Null" ;
VAL_ 641 IgnPsswrdActv_B_Stat 1 "Active" 0 "Inactive" ;
VAL_ 641 ChrgGoTTouch_B_Stat_UB 1 "Fresh_data" 0 "Unchanged_data" ;
VAL_ 641 ChrgGoTTouch_B_Stat 1 "On" 0 "Off" ;
VAL_ 641 ChrgGoTPrcond_D_Stat_UB 1 "Fresh_data" 0 "Unchanged_data" ;
VAL_ 641 ChrgGoTPrcond_D_Stat 3 "High" 2 "Medium" 1 "Low" 0 "Off" ;
VAL_ 641 ChrgGoTNext_D_Stat_UB 1 "Fresh_data" 0 "Unchanged_data" ;
VAL_ 641 ChrgGoTMnte_D_Stat_UB 1 "Fresh_data" 0 "Unchanged_data" ;
VAL_ 641 ChrgGoTMnte_D_Stat 15 "NotUsed_4" 14 "NotUsed_3" 13 "NotUsed_2" 12 "NotUsed_1" 11 "Minute_55" 10 "Minute_50" 9 "Minute_45" 8 "Minute_40" 7 "Minute_35" 6 "Minute_30" 5 "Minute_25" 4 "Minute_20" 3 "Minute_15" 2 "Minute_10" 1 "Minute_5" 0 "Minute_0" ;
VAL_ 641 ChrgGoTHr_T_Stat_UB 1 "Fresh_data" 0 "Unchanged_data" ;
VAL_ 641 ChrgGoTHr_T_Stat 31 "Faulty" 30 "NoDataExists" ;
VAL_ 641 ChrgGoTExtHtr_B_Stat_UB 1 "Fresh_data" 0 "Unchanged_data" ;
VAL_ 641 ChrgGoTExtHtr_B_Stat 1 "On" 0 "Off" ;
VAL_ 641 ChrgGoTElement_D_Stat_UB 1 "Fresh_data" 0 "Unchanged_data" ;
VAL_ 641 ChrgGoTAllOn_B_Stat_UB 1 "Fresh_data" 0 "Unchanged_data" ;
VAL_ 641 ChrgGoTAllOn_B_Stat 1 "On" 0 "Off" ;
VAL_ 641 TrlrAidMsgTxt_D2_Rq 63 "Message63" 62 "Message62" 61 "Message61" 60 "Message60" 55 "Message55" 50 "Message50" 45 "Message45" 40 "Message40" 35 "Message35" 31 "Message31" 30 "Message30" 29 "Message29" 28 "Message28" 27 "Message27" 26 "Message26" 25 "Message25" 24 "Message24" 23 "Message23" 22 "Message22" 21 "Message21" 20 "Message20" 19 "Message19" 18 "Message18" 17 "Message17" 16 "Message16" 15 "Message15" 14 "Message14" 13 "Message13" 12 "Message12" 11 "Message11" 10 "Message10" 9 "Message9" 8 "Message8" 7 "Message7" 6 "Message6" 5 "Message5" 4 "Message4" 3 "Message3" 2 "Message2" 1 "Message1" 0 "NoMessage" ;
VAL_ 641 TrlrAidEnbl_D2_Stat 7 "NotUsed_1" 6 "TbaActiveExpertActive" 5 "TbaActiveExpertAvail" 4 "TbaOffTrgActive" 3 "TbaOffTrgSetup" 2 "TbaSetup" 1 "TbaActive" 0 "Inactive" ;
VAL_ 641 TrlrAidMsgTxt_D2_Rq_UB 1 "Fresh_data" 0 "Unchanged_data" ;
VAL_ 641 TrlrAidEnbl_D2_Stat_UB 1 "Fresh_data" 0 "Unchanged_data" ;
VAL_ 1012 ChrgLocSaved_B_Dsply 1 "Yes" 0 "No" ;
VAL_ 1012 ChrgLocLongPostv_B_Sav 1 "Yes" 0 "No" ;
VAL_ 1012 ChrgLocLattPostv_B_Sav 1 "Yes" 0 "No" ;
VAL_ 1012 AirCondRec_B_RqVehEl 1 "Yes" 0 "No" ;
VAL_ 1012 ChrgNowCurnt_B_Dsply 1 "On" 0 "Off" ;
VAL_ 1011 ChrgLocLongPostv_B_Uns 1 "Yes" 0 "No" ;
VAL_ 1011 ChrgLocLattPostv_B_Uns 1 "Yes" 0 "No" ;
VAL_ 1011 VehShutDownMsgTxt_D_Rq 3 "NotUsed" 2 "ProhibitedRestart" 1 "ShutdownWarning" 0 "NoMessage" ;
VAL_ 533 AutoEpbZoomView_B_Stat 1 "Active" 0 "Inactive" ;
VAL_ 533 ClrExitAsstEnbl_D_RqMnu 3 "NotUsed" 0 "Inactive" 2 "Enable" 1 "Disable" ;
VAL_ 533 PaakMyKey_D_Rq 3 "NotUsed" 2 "ConfirmNewPaakMyKey" 1 "RequestNewPaakMyKey" 0 "None" ;
VAL_ 533 AutoEpbButtn_B_Stat 1 "Pressed" 0 "Not_Pressed" ;
VAL_ 533 TrlrAidMde_D_Rq 3 "Mode_3" 2 "Mode_2" 1 "Mode_1" 0 "NoRequest" ;
VAL_ 533 TCU_Init_Actvtn_St 3 "NotUsed" 2 "InitialActivateDeny" 1 "InitialActivateAccept" 0 "Invalid" ;
VAL_ 533 TCU_Final_Actvtn_St 3 "NotUsed" 2 "FinalActivateDeny" 1 "FinalActivateAccept" 0 "Invalid" ;
VAL_ 533 DcacPw_D_Rq 3 "High" 2 "Low" 1 "Off" 0 "Null" ;
VAL_ 533 DcacPwReset_B_Rq 1 "Reset" 0 "Null" ;
VAL_ 533 LghtAmbDrvMde_D_Rq 3 "NotUsed" 2 "Automatic" 1 "Manual" 0 "Null" ;
VAL_ 533 OtaTrg_D_Stat 3 "NotUsed_1" 2 "Accepted" 1 "NotAccepted" 0 "Null" ;
VAL_ 533 DcacPwLoButtn_B_Stat 1 "Pressed" 0 "Not_Pressed" ;
VAL_ 533 DcacPwOffButtn_B_Stat 1 "Pressed" 0 "Not_Pressed" ;
VAL_ 533 DcacPwHiButtn_B_Stat 1 "Pressed" 0 "Not_Pressed" ;
VAL_ 533 DcacPwResetButtn_B_Stat 1 "Pressed" 0 "Not_Pressed" ;
VAL_ 533 DcacPwButtn_B_Falt 1 "Faulted" 0 "NotFaulted" ;
VAL_ 533 OnbChrgGoTTouch_D_Rq 3 "NotUsed" 2 "On" 1 "Off" 0 "Null" ;
VAL_ 533 OnbChrgGoTPrcond_D_Rq 3 "High" 2 "Medium" 1 "Low" 0 "Off" ;
VAL_ 533 OnbChrgGoTOn_D_Rq 3 "NotUsed" 2 "On" 1 "Off" 0 "Null" ;
VAL_ 533 OnbChrgGoTMnte_D_Rq 15 "NotUsed_4" 14 "NotUsed_3" 13 "NotUsed_2" 12 "NotUsed_1" 11 "Minute_55" 10 "Minute_50" 9 "Minute_45" 8 "Minute_40" 7 "Minute_35" 6 "Minute_30" 5 "Minute_25" 4 "Minute_20" 3 "Minute_15" 2 "Minute_10" 1 "Minute_5" 0 "Minute_0" ;
VAL_ 533 OnbChrgGoTHr_T_Rq 31 "Faulty" 30 "NoDataExists" ;
VAL_ 533 OnbChrgGoTExtHtr_D_Rq 3 "NotUsed" 2 "On" 1 "Off" 0 "Null" ;
VAL_ 533 OnbChrgGoTDelete_B_Rq 1 "Request" 0 "NoRequest" ;
VAL_ 533 OnbChrgClearAll_B_Rq 1 "Request" 0 "NoRequest" ;
VAL_ 533 OnbChrgGoTUpdate_B_Rq 1 "Request" 0 "NoRequest" ;
VAL_ 533 TrlrAlarmButtn_B_Stat 1 "On" 0 "Off" ;
VAL_ 533 DcacMdeButtn_B_Stat 1 "Pressed" 0 "Not_Pressed" ;
VAL_ 533 DcacGfciTestBttn_B_Stat 1 "Pressed" 0 "Not_Pressed" ;
VAL_ 533 TrlrHitch_D_RqMnu 15 "NotUsed_10" 14 "NotUsed_9" 13 "NotUsed_8" 12 "NotUsed_7" 11 "NotUsed_6" 10 "NotUsed_5" 9 "NotUsed_4" 8 "NotUsed_3" 7 "NotUsed_2" 6 "NotUsed_1" 5 "GoToTraileringDomain" 4 "Confirm" 3 "TurnOnTba" 2 "TurnOnAutohitch" 1 "CancelAutohitch" 0 "NoRequest" ;
VAL_ 533 DcacPwButtn_B_Stat 1 "Pressed" 0 "Not_Pressed" ;
VAL_ 801 CDWarnChime_St 1 "On" 0 "Off" ;
VAL_ 801 SoftWarning 1 "Chime_On" 0 "Chime_Off" ;
VAL_ 801 HardWarning 1 "Chime_On" 0 "Chime_Off" ;
VAL_ 801 InfoWarning 1 "Chime_On" 0 "Chime_Off" ;
VAL_ 801 DrvDsplyPalette_D_Stat 7 "NotUsed_3" 6 "NotUsed_2" 5 "ManualNightDark" 4 "ManualNightBright" 3 "ManualDay" 2 "AutoNight" 1 "AutoDay" 0 "Null" ;
VAL_ 878 ClimtSyncRear2_B_Stat 1 "Pressed" 0 "Not_Pressed" ;
VAL_ 878 ClimtStHeatRr2_B_Stat 1 "Pressed" 0 "Not_Pressed" ;
VAL_ 878 ClimtStHeatRl2_B_Stat 1 "Pressed" 0 "Not_Pressed" ;
VAL_ 878 ClimtStCoolRr2_B_Stat 1 "Pressed" 0 "Not_Pressed" ;
VAL_ 878 ClimtStCoolRl2_B_Stat 1 "Pressed" 0 "Not_Pressed" ;
VAL_ 878 ClimtSeatRr2_D_Rq 128 "H3_High_Heat_MAX" 64 "H2_Medium_Heat" 32 "H1_Low_Heat" 16 "C3_High_Cool_MAX" 8 "C2_Medium_Cool" 4 "C1_Low_Cool" 2 "Off" ;
VAL_ 878 ClimtSeatRl2_D_Rq 128 "H3_High_Heat_MAX" 64 "H2_Medium_Heat" 32 "H1_Low_Heat" 16 "C3_High_Cool_MAX" 8 "C2_Medium_Cool" 4 "C1_Low_Cool" 2 "Off" ;
VAL_ 878 ClimtRrTe3rd2_D_Stat 3 "NotUsed" 2 "Decrement" 1 "Increment" 0 "Inactive" ;
VAL_ 878 ClimtRrPw3rd2_B_Stat 1 "Pressed" 0 "Not_Pressed" ;
VAL_ 878 ClimtRrPnl3rd2_B_Stat 1 "Pressed" 0 "Not_Pressed" ;
VAL_ 878 ClimtRrPf3rd2_B_Stat 1 "Pressed" 0 "Not_Pressed" ;
VAL_ 878 ClimtRrFlr3rd2_B_Stat 1 "Pressed" 0 "Not_Pressed" ;
VAL_ 878 ClimtRrBlwr3rd2_D_Stat 3 "NotUsed" 2 "Decrement" 1 "Increment" 0 "Inactive" ;
VAL_ 878 ClimtRrAuto3rd2_B_Stat 1 "Pressed" 0 "Not_Pressed" ;
VAL_ 878 ClimtRearView2_D_Stat 3 "ThirdRow" 2 "SecondRow" 1 "Both" 0 "NotDisplayed" ;
VAL_ 878 ClimtRearTe2_D_Stat 3 "NotUsed" 2 "Decrement" 1 "Increment" 0 "Inactive" ;
VAL_ 878 ClimtRearTe2_An_Actl 511 "Faulty" ;
VAL_ 878 ClimtRearPw2_B_Stat 1 "Pressed" 0 "Not_Pressed" ;
VAL_ 878 ClimtRearPnlFlr2_B_Stat 1 "Pressed" 0 "Not_Pressed" ;
VAL_ 878 ClimtRearPnl2_B_Stat 1 "Pressed" 0 "Not_Pressed" ;
VAL_ 878 ClimtRearFlr2_B_Stat 1 "Pressed" 0 "Not_Pressed" ;
VAL_ 878 ClimtRearBlwr2_D_Stat 3 "NotUsed" 2 "Decrement" 1 "Increment" 0 "Inactive" ;
VAL_ 878 ClimtRearBlwr2_An_Actl 511 "Faulty" ;
VAL_ 878 ClimtRearAuto2_B_Stat 1 "Pressed" 0 "Not_Pressed" ;
VAL_ 258 GPS_Track_D_Rq 3 "NotUsed_1" 2 "NewGPSTrack" 1 "GPSTrackActive" 0 "Inactive" ;
VAL_ 258 APIM_SwPartNo_D_Rq 3 "NotUsed" 2 "Request" 1 "NoRequest" 0 "Inactive" ;
VAL_ 258 TCU_Init_Actvtn_Rq 3 "NotUsed" 2 "InitialActivateRequest" 1 "NoRequest" 0 "Inactive" ;
VAL_ 258 TCU_Final_Actvtn_Rq 3 "NotUsed" 2 "FinalActiveRequested" 1 "NoRequest" 0 "Inactive" ;
VAL_ 413 LBS1_ListStatus 0 "Inactive" 1 "Valid" 2 "Updating" 3 "Reserved" ;
VAL_ 556 DrvAsstMnuButtn_B_Stat 1 "Pressed" 0 "Not_Pressed" ;
VAL_ 556 Manual_Temp_Setting 31 "Full_Heat" 30 "Setting_30" 29 "Setting_29" 28 "Setting_28" 27 "Setting_27" 26 "Setting_26" 25 "Setting_25" 24 "Setting_24" 23 "Setting_23" 22 "Setting_22" 21 "Setting_21" 20 "Setting_20" 19 "Setting_19" 18 "Setting_18" 17 "Setting_17" 16 "Setting_16" 15 "Setting_15" 14 "Setting_14" 13 "Setting_13" 12 "Setting_12" 11 "Setting_11" 10 "Setting_10" 9 "Setting_9" 8 "Setting_8" 7 "Setting_7" 6 "Setting_6" 5 "Setting_5" 4 "Setting_4" 3 "Setting_3" 2 "Setting_2" 1 "Full_Cool" 0 "Off" ;
VAL_ 556 EFP_Bezel_Diag_St 15 "Reserved" 3 "CalibrationPartNumber" 2 "HardwarePartNumber" 1 "SoftwarePartNumber" 0 "Inactive_NOP" ;
VAL_ 556 Bezel_Beep_St 0 "Invalid" 2 "Disabled" 1 "Enabled" ;
VAL_ 556 Bezel_Beeps_Supported 2 "Not_Supported" 1 "Supported" 0 "Invalid" ;
VAL_ 556 PassRstrnInd_Stat 7 "Invalid" 6 "Unused_2" 5 "Unused_1" 4 "Both_Indicators_Faulted" 3 "AirbagOff_Indicator_fault" 2 "AirbagOn_Indicator_fault" 1 "Normal" 0 "Not_Supported" ;
VAL_ 259 SDARS_ChipControl_Rq 7 "NotUsed_4" 6 "NotUsed_3" 5 "NotUsed_2" 4 "NotUsed_1" 3 "Reset" 2 "PowerDown" 1 "PowerUp" 0 "Inactive" ;
VAL_ 259 SDARS_AlertStatus_Rq 2 "Disable" 1 "Enable" 0 "Inactive" ;
VAL_ 538 MK_SpeedMinderConf_St 31 "mph90" 30 "mph85" 29 "mph80" 28 "mph75" 27 "mph70" 26 "mph65" 25 "mph60" 24 "mph55" 23 "mph50" 22 "mph45" 21 "mph40" 20 "Kmh165" 19 "Kmh160" 18 "Kmh155" 17 "Kmh150" 16 "Kmh145" 15 "Kmh140" 14 "Kmh135" 13 "Kmh130" 12 "Kmh125" 11 "Kmh120" 10 "Kmh115" 9 "Kmh110" 8 "Kmh105" 7 "Kmh100" 6 "kmh95" 5 "kmh90" 4 "kmh85" 3 "kmh80" 2 "kmh75" 1 "kmh70" 0 "Off" ;
VAL_ 538 MK_SpeedLimitConf_St 31 "mph90" 30 "mph85" 29 "mph80" 28 "mph75" 27 "mph70" 26 "mph65" 25 "mph60" 24 "mph55" 23 "mph50" 22 "mph45" 21 "mph40" 20 "Kmh165" 19 "Kmh160" 18 "Kmh155" 17 "Kmh150" 16 "Kmh145" 15 "Kmh140" 14 "Kmh135" 13 "Kmh130" 12 "Kmh125" 11 "Kmh120" 10 "Kmh115" 9 "Kmh110" 8 "Kmh105" 7 "Kmh100" 6 "kmh95" 5 "kmh90" 4 "kmh85" 3 "kmh80" 2 "kmh75" 1 "kmh70" 0 "Off" ;
VAL_ 538 MK_ESCRestrictConf_St 3 "NotUsed" 2 "On" 1 "Off" 0 "Null" ;
VAL_ 538 MK_ECalRestrictConf_St 3 "NotUsed" 2 "On" 1 "Off" 0 "Null" ;
VAL_ 538 MK_DNDRestrictConf_St 3 "NotUsed" 2 "On" 1 "Off" 0 "Null" ;
VAL_ 538 MK_AudioLimitConfig_St 3 "NotUsed" 2 "On" 1 "Off" 0 "Null" ;
VAL_ 422 MK_UserMyKeyCount_Rsp 15 "Inactive" 14 "Unlimited" 13 "Thirteen" 12 "Twelve" 11 "Eleven" 10 "Ten" 9 "Nine" 8 "Eight" 7 "Seven" 6 "Six" 5 "Five" 4 "Four" 3 "Three" 2 "Two" 1 "One" 0 "Zero" ;
VAL_ 422 MK_CreateMyKey_Rsp 7 "NotUsed_3" 6 "NotUsed_2" 5 "NotUsed_1" 4 "Success" 3 "GenericFailure" 2 "NoKeyInSlot" 1 "KeyInSlotAlreadyMyKey" 0 "Inactive" ;
VAL_ 422 MK_AdminMyKeyCount_Rsp 15 "Inactive" 14 "Unlimited" 13 "Thirteen" 12 "Twelve" 11 "Eleven" 10 "Ten" 9 "Nine" 8 "Eight" 7 "Seven" 6 "Six" 5 "Five" 4 "Four" 3 "Three" 2 "Two" 1 "One" 0 "Zero" ;
VAL_ 1020 CtrStkPersIndex2_D_Actl 7 "Unused_3" 6 "Unused_2" 5 "Unused_1" 4 "Vehicle" 3 "PERS_4" 2 "PERS_3" 1 "PERS_2" 0 "PERS_1" ;
VAL_ 1020 CtrStkDsplyOp2_D_Rq 7 "Unused_2" 6 "Unused_1" 5 "Copy" 4 "Restore" 3 "Upload" 2 "Set" 1 "Query" 0 "Null" ;
VAL_ 1007 PersIndexIpc2_D_Actl 7 "Unused_3" 6 "Unused_2" 5 "Unused_1" 4 "Vehicle" 3 "PERS_4" 2 "PERS_3" 1 "PERS_2" 0 "PERS_1" ;
